[part 6 of 11: package /CANAnalyzer/CommunicationClusters]
AUTOSAR XML (schema 00051)
package /CANAnalyzer/CommunicationClusters  (continued)
  can cluster CAN_FD_IPB_41  (continued)
    can physical channel Channel  (continued)
      frame StatusCPDData3FBD_Trunk: id 0x161, frame-length=64, can-addressing-mode=STANDARD, can-frame-rx-behavior=CAN-FD, can-frame-tx-behavior=CAN-FD
        pdu StatusCPDData3FBD_Trunk: length=64, unused-bit-pattern=0
          signal StatusCPDData3FBD_Trunk_MsgCounter: start 0, 8 bit, little-endian, data-type-policy=OVERRIDE, base-type=uint8, compu {phys=raw}, range phys 0..252
          signal StatusCPDData3FBD_Trunk_LinkID: start 8, 8 bit, little-endian, data-type-policy=OVERRIDE, base-type=uint8, compu {phys=raw}, range phys 0..252
          signal StatusCPDData3FBD_Trunk_AGCValue: start 16, 8 bit, little-endian, data-type-policy=OVERRIDE, base-type=uint8, compu {phys=raw}, range phys 0..252
          signal StatusCPDData3FBD_Trunk_Channel: start 24, 8 bit, little-endian, data-type-policy=OVERRIDE, base-type=uint8, compu {phys=raw}, range phys 0..252
          signal StatusCPDData3FBD_Trunk_CIRData00: start 32, 8 bit, little-endian, data-type-policy=OVERRIDE, base-type=uint8, compu {phys=raw}, range phys 0..255
          signal StatusCPDData3FBD_Trunk_CIRData01: start 40, 8 bit, little-endian, data-type-policy=OVERRIDE, base-type=uint8, compu {phys=raw}, range phys 0..255
          signal StatusCPDData3FBD_Trunk_CIRData02: start 48, 8 bit, little-endian, data-type-policy=OVERRIDE, base-type=uint8, compu {phys=raw}, range phys 0..255
          signal StatusCPDData3FBD_Trunk_CIRData03: start 56, 8 bit, little-endian, data-type-policy=OVERRIDE, base-type=uint8, compu {phys=raw}, range phys 0..255
          signal StatusCPDData3FBD_Trunk_CIRData04: start 64, 8 bit, little-endian, data-type-policy=OVERRIDE, base-type=uint8, compu {phys=raw}, range phys 0..255
          signal StatusCPDData3FBD_Trunk_CIRData05: start 72, 8 bit, little-endian, data-type-policy=OVERRIDE, base-type=uint8, compu {phys=raw}, range phys 0..255
          signal StatusCPDData3FBD_Trunk_CIRData06: start 80, 8 bit, little-endian, data-type-policy=OVERRIDE, base-type=uint8, compu {phys=raw}, range phys 0..255
          signal StatusCPDData3FBD_Trunk_CIRData07: start 88, 8 bit, little-endian, data-type-policy=OVERRIDE, base-type=uint8, compu {phys=raw}, range phys 0..255
          signal StatusCPDData3FBD_Trunk_CIRData08: start 96, 8 bit, little-endian, data-type-policy=OVERRIDE, base-type=uint8, compu {phys=raw}, range phys 0..255
          signal StatusCPDData3FBD_Trunk_CIRData09: start 104, 8 bit, little-endian, data-type-policy=OVERRIDE, base-type=uint8, compu {phys=raw}, range phys 0..255
          signal StatusCPDData3FBD_Trunk_CIRData10: start 112, 8 bit, little-endian, data-type-policy=OVERRIDE, base-type=uint8, compu {phys=raw}, range phys 0..255
          signal StatusCPDData3FBD_Trunk_CIRData11: start 120, 8 bit, little-endian, data-type-policy=OVERRIDE, base-type=uint8, compu {phys=raw}, range phys 0..255
          signal StatusCPDData3FBD_Trunk_CIRData12: start 128, 8 bit, little-endian, data-type-policy=OVERRIDE, base-type=uint8, compu {phys=raw}, range phys 0..255
          signal StatusCPDData3FBD_Trunk_CIRData13: start 136, 8 bit, little-endian, data-type-policy=OVERRIDE, base-type=uint8, compu {phys=raw}, range phys 0..255
          signal StatusCPDData3FBD_Trunk_CIRData14: start 144, 8 bit, little-endian, data-type-policy=OVERRIDE, base-type=uint8, compu {phys=raw}, range phys 0..255
          signal StatusCPDData3FBD_Trunk_CIRData15: start 152, 8 bit, little-endian, data-type-policy=OVERRIDE, base-type=uint8, compu {phys=raw}, range phys 0..255
          signal StatusCPDData3FBD_Trunk_CIRData16: start 160, 8 bit, little-endian, data-type-policy=OVERRIDE, base-type=uint8, compu {phys=raw}, range phys 0..255
          signal StatusCPDData3FBD_Trunk_CIRData17: start 168, 8 bit, little-endian, data-type-policy=OVERRIDE, base-type=uint8, compu {phys=raw}, range phys 0..255
          signal StatusCPDData3FBD_Trunk_CIRData18: start 176, 8 bit, little-endian, data-type-policy=OVERRIDE, base-type=uint8, compu {phys=raw}, range phys 0..255
          signal StatusCPDData3FBD_Trunk_CIRData19: start 184, 8 bit, little-endian, data-type-policy=OVERRIDE, base-type=uint8, compu {phys=raw}, range phys 0..255
          signal StatusCPDData3FBD_Trunk_CIRData20: start 192, 8 bit, little-endian, data-type-policy=OVERRIDE, base-type=uint8, compu {phys=raw}, range phys 0..255
          signal StatusCPDData3FBD_Trunk_CIRData21: start 200, 8 bit, little-endian, data-type-policy=OVERRIDE, base-type=uint8, compu {phys=raw}, range phys 0..255
          signal StatusCPDData3FBD_Trunk_CIRData22: start 208, 8 bit, little-endian, data-type-policy=OVERRIDE, base-type=uint8, compu {phys=raw}, range phys 0..255
          signal StatusCPDData3FBD_Trunk_CIRData23: start 216, 8 bit, little-endian, data-type-policy=OVERRIDE, base-type=uint8, compu {phys=raw}, range phys 0..255
          signal StatusCPDData3FBD_Trunk_CIRData24: start 224, 8 bit, little-endian, data-type-policy=OVERRIDE, base-type=uint8, compu {phys=raw}, range phys 0..255
          signal StatusCPDData3FBD_Trunk_CIRData25: start 232, 8 bit, little-endian, data-type-policy=OVERRIDE, base-type=uint8, compu {phys=raw}, range phys 0..255
          signal StatusCPDData3FBD_Trunk_CIRData26: start 240, 8 bit, little-endian, data-type-policy=OVERRIDE, base-type=uint8, compu {phys=raw}, range phys 0..255
          signal StatusCPDData3FBD_Trunk_CIRData27: start 248, 8 bit, little-endian, data-type-policy=OVERRIDE, base-type=uint8, compu {phys=raw}, range phys 0..255
          signal StatusCPDData3FBD_Trunk_CIRData28: start 256, 8 bit, little-endian, data-type-policy=OVERRIDE, base-type=uint8, compu {phys=raw}, range phys 0..255
          signal StatusCPDData3FBD_Trunk_CIRData29: start 264, 8 bit, little-endian, data-type-policy=OVERRIDE, base-type=uint8, compu {phys=raw}, range phys 0..255
          signal StatusCPDData3FBD_Trunk_CIRData30: start 272, 8 bit, little-endian, data-type-policy=OVERRIDE, base-type=uint8, compu {phys=raw}, range phys 0..255
          signal StatusCPDData3FBD_Trunk_CIRData31: start 280, 8 bit, little-endian, data-type-policy=OVERRIDE, base-type=uint8, compu {phys=raw}, range phys 0..255
          signal StatusCPDData3FBD_Trunk_CIRData32: start 288, 8 bit, little-endian, data-type-policy=OVERRIDE, base-type=uint8, compu {phys=raw}, range phys 0..255
          signal StatusCPDData3FBD_Trunk_CIRData33: start 296, 8 bit, little-endian, data-type-policy=OVERRIDE, base-type=uint8, compu {phys=raw}, range phys 0..255
          signal StatusCPDData3FBD_Trunk_CIRData34: start 304, 8 bit, little-endian, data-type-policy=OVERRIDE, base-type=uint8, compu {phys=raw}, range phys 0..255
          signal StatusCPDData3FBD_Trunk_CIRData35: start 312, 8 bit, little-endian, data-type-policy=OVERRIDE, base-type=uint8, compu {phys=raw}, range phys 0..255
          signal StatusCPDData3FBD_Trunk_CIRData36: start 320, 8 bit, little-endian, data-type-policy=OVERRIDE, base-type=uint8, compu {phys=raw}, range phys 0..255
          signal StatusCPDData3FBD_Trunk_CIRData37: start 328, 8 bit, little-endian, data-type-policy=OVERRIDE, base-type=uint8, compu {phys=raw}, range phys 0..255
          signal StatusCPDData3FBD_Trunk_CIRData38: start 336, 8 bit, little-endian, data-type-policy=OVERRIDE, base-type=uint8, compu {phys=raw}, range phys 0..255
          signal StatusCPDData3FBD_Trunk_CIRData39: start 344, 8 bit, little-endian, data-type-policy=OVERRIDE, base-type=uint8, compu {phys=raw}, range phys 0..255
          signal StatusCPDData3FBD_Trunk_CIRData40: start 352, 8 bit, little-endian, data-type-policy=OVERRIDE, base-type=uint8, compu {phys=raw}, range phys 0..255
          signal StatusCPDData3FBD_Trunk_CIRData41: start 360, 8 bit, little-endian, data-type-policy=OVERRIDE, base-type=uint8, compu {phys=raw}, range phys 0..255
          signal StatusCPDData3FBD_Trunk_CIRData42: start 368, 8 bit, little-endian, data-type-policy=OVERRIDE, base-type=uint8, compu {phys=raw}, range phys 0..255
          signal StatusCPDData3FBD_Trunk_CIRData43: start 376, 8 bit, little-endian, data-type-policy=OVERRIDE, base-type=uint8, compu {phys=raw}, range phys 0..255
          signal StatusCPDData3FBD_Trunk_CIRData44: start 384, 8 bit, little-endian, data-type-policy=OVERRIDE, base-type=uint8, compu {phys=raw}, range phys 0..255
          signal StatusCPDData3FBD_Trunk_CIRData45: start 392, 8 bit, little-endian, data-type-policy=OVERRIDE, base-type=uint8, compu {phys=raw}, range phys 0..255
          signal StatusCPDData3FBD_Trunk_CIRData46: start 400, 8 bit, little-endian, data-type-policy=OVERRIDE, base-type=uint8, compu {phys=raw}, range phys 0..255
          signal StatusCPDData3FBD_Trunk_CIRData47: start 408, 8 bit, little-endian, data-type-policy=OVERRIDE, base-type=uint8, compu {phys=raw}, range phys 0..255
          signal StatusCPDData3FBD_Trunk_CIRData48: start 416, 8 bit, little-endian, data-type-policy=OVERRIDE, base-type=uint8, compu {phys=raw}, range phys 0..255
          signal StatusCPDData3FBD_Trunk_CIRData49: start 424, 8 bit, little-endian, data-type-policy=OVERRIDE, base-type=uint8, compu {phys=raw}, range phys 0..255
          signal StatusCPDData3FBD_Trunk_CIRData50: start 432, 8 bit, little-endian, data-type-policy=OVERRIDE, base-type=uint8, compu {phys=raw}, range phys 0..255
          signal StatusCPDData3FBD_Trunk_CIRData51: start 440, 8 bit, little-endian, data-type-policy=OVERRIDE, base-type=uint8, compu {phys=raw}, range phys 0..255
          signal StatusCPDData3FBD_Trunk_CIRData52: start 448, 8 bit, little-endian, data-type-policy=OVERRIDE, base-type=uint8, compu {phys=raw}, range phys 0..255
          signal StatusCPDData3FBD_Trunk_CIRData53: start 456, 8 bit, little-endian, data-type-policy=OVERRIDE, base-type=uint8, compu {phys=raw}, range phys 0..255
          signal StatusCPDData3FBD_Trunk_CIRData54: start 464, 8 bit, little-endian, data-type-policy=OVERRIDE, base-type=uint8, compu {phys=raw}, range phys 0..255
          signal StatusCPDData3FBD_Trunk_CIRData55: start 472, 8 bit, little-endian, data-type-policy=OVERRIDE, base-type=uint8, compu {phys=raw}, range phys 0..255
          signal StatusCPDData3FBD_Trunk_CIRData56: start 480, 8 bit, little-endian, data-type-policy=OVERRIDE, base-type=uint8, compu {phys=raw}, range phys 0..255
          signal StatusCPDData3FBD_Trunk_CIRData57: start 488, 8 bit, little-endian, data-type-policy=OVERRIDE, base-type=uint8, compu {phys=raw}, range phys 0..255
          signal StatusCPDData3FBD_Trunk_CIRData58: start 496, 8 bit, little-endian, data-type-policy=OVERRIDE, base-type=uint8, compu {phys=raw}, range phys 0..255
          signal StatusCPDData3FBD_Trunk_CIRData59: start 504, 8 bit, little-endian, data-type-policy=OVERRIDE, base-type=uint8, compu {phys=raw}, range phys 0..255
      frame StatusCPDData3FBD_VL: id 0x162, frame-length=64, can-addressing-mode=STANDARD, can-frame-rx-behavior=CAN-FD, can-frame-tx-behavior=CAN-FD
        pdu StatusCPDData3FBD_VL: length=64, unused-bit-pattern=0
          signal StatusCPDData3FBD_VL_MsgCounter: start 0, 8 bit, little-endian, data-type-policy=OVERRIDE, base-type=uint8, compu {phys=raw}, range phys 0..252
          signal StatusCPDData3FBD_VL_LinkID: start 8, 8 bit, little-endian, data-type-policy=OVERRIDE, base-type=uint8, compu {phys=raw}, range phys 0..252
          signal StatusCPDData3FBD_VL_AGCValue: start 16, 8 bit, little-endian, data-type-policy=OVERRIDE, base-type=uint8, compu {phys=raw}, range phys 0..252
          signal StatusCPDData3FBD_VL_Channel: start 24, 8 bit, little-endian, data-type-policy=OVERRIDE, base-type=uint8, compu {phys=raw}, range phys 0..252
          signal StatusCPDData3FBD_VL_CIRData00: start 32, 8 bit, little-endian, data-type-policy=OVERRIDE, base-type=uint8, compu {phys=raw}, range phys 0..255
          signal StatusCPDData3FBD_VL_CIRData01: start 40, 8 bit, little-endian, data-type-policy=OVERRIDE, base-type=uint8, compu {phys=raw}, range phys 0..255
          signal StatusCPDData3FBD_VL_CIRData02: start 48, 8 bit, little-endian, data-type-policy=OVERRIDE, base-type=uint8, compu {phys=raw}, range phys 0..255
          signal StatusCPDData3FBD_VL_CIRData03: start 56, 8 bit, little-endian, data-type-policy=OVERRIDE, base-type=uint8, compu {phys=raw}, range phys 0..255
          signal StatusCPDData3FBD_VL_CIRData04: start 64, 8 bit, little-endian, data-type-policy=OVERRIDE, base-type=uint8, compu {phys=raw}, range phys 0..255
          signal StatusCPDData3FBD_VL_CIRData05: start 72, 8 bit, little-endian, data-type-policy=OVERRIDE, base-type=uint8, compu {phys=raw}, range phys 0..255
          signal StatusCPDData3FBD_VL_CIRData06: start 80, 8 bit, little-endian, data-type-policy=OVERRIDE, base-type=uint8, compu {phys=raw}, range phys 0..255
          signal StatusCPDData3FBD_VL_CIRData07: start 88, 8 bit, little-endian, data-type-policy=OVERRIDE, base-type=uint8, compu {phys=raw}, range phys 0..255
          signal StatusCPDData3FBD_VL_CIRData08: start 96, 8 bit, little-endian, data-type-policy=OVERRIDE, base-type=uint8, compu {phys=raw}, range phys 0..255
          signal StatusCPDData3FBD_VL_CIRData09: start 104, 8 bit, little-endian, data-type-policy=OVERRIDE, base-type=uint8, compu {phys=raw}, range phys 0..255
          signal StatusCPDData3FBD_VL_CIRData10: start 112, 8 bit, little-endian, data-type-policy=OVERRIDE, base-type=uint8, compu {phys=raw}, range phys 0..255
          signal StatusCPDData3FBD_VL_CIRData11: start 120, 8 bit, little-endian, data-type-policy=OVERRIDE, base-type=uint8, compu {phys=raw}, range phys 0..255
          signal StatusCPDData3FBD_VL_CIRData12: start 128, 8 bit, little-endian, data-type-policy=OVERRIDE, base-type=uint8, compu {phys=raw}, range phys 0..255
          signal StatusCPDData3FBD_VL_CIRData13: start 136, 8 bit, little-endian, data-type-policy=OVERRIDE, base-type=uint8, compu {phys=raw}, range phys 0..255
          signal StatusCPDData3FBD_VL_CIRData14: start 144, 8 bit, little-endian, data-type-policy=OVERRIDE, base-type=uint8, compu {phys=raw}, range phys 0..255
          signal StatusCPDData3FBD_VL_CIRData15: start 152, 8 bit, little-endian, data-type-policy=OVERRIDE, base-type=uint8, compu {phys=raw}, range phys 0..255
          signal StatusCPDData3FBD_VL_CIRData16: start 160, 8 bit, little-endian, data-type-policy=OVERRIDE, base-type=uint8, compu {phys=raw}, range phys 0..255
          signal StatusCPDData3FBD_VL_CIRData17: start 168, 8 bit, little-endian, data-type-policy=OVERRIDE, base-type=uint8, compu {phys=raw}, range phys 0..255
          signal StatusCPDData3FBD_VL_CIRData18: start 176, 8 bit, little-endian, data-type-policy=OVERRIDE, base-type=uint8, compu {phys=raw}, range phys 0..255
          signal StatusCPDData3FBD_VL_CIRData19: start 184, 8 bit, little-endian, data-type-policy=OVERRIDE, base-type=uint8, compu {phys=raw}, range phys 0..255
          signal StatusCPDData3FBD_VL_CIRData20: start 192, 8 bit, little-endian, data-type-policy=OVERRIDE, base-type=uint8, compu {phys=raw}, range phys 0..255
          signal StatusCPDData3FBD_VL_CIRData21: start 200, 8 bit, little-endian, data-type-policy=OVERRIDE, base-type=uint8, compu {phys=raw}, range phys 0..255
          signal StatusCPDData3FBD_VL_CIRData22: start 208, 8 bit, little-endian, data-type-policy=OVERRIDE, base-type=uint8, compu {phys=raw}, range phys 0..255
          signal StatusCPDData3FBD_VL_CIRData23: start 216, 8 bit, little-endian, data-type-policy=OVERRIDE, base-type=uint8, compu {phys=raw}, range phys 0..255
          signal StatusCPDData3FBD_VL_CIRData24: start 224, 8 bit, little-endian, data-type-policy=OVERRIDE, base-type=uint8, compu {phys=raw}, range phys 0..255
          signal StatusCPDData3FBD_VL_CIRData25: start 232, 8 bit, little-endian, data-type-policy=OVERRIDE, base-type=uint8, compu {phys=raw}, range phys 0..255
          signal StatusCPDData3FBD_VL_CIRData26: start 240, 8 bit, little-endian, data-type-policy=OVERRIDE, base-type=uint8, compu {phys=raw}, range phys 0..255
          signal StatusCPDData3FBD_VL_CIRData27: start 248, 8 bit, little-endian, data-type-policy=OVERRIDE, base-type=uint8, compu {phys=raw}, range phys 0..255
          signal StatusCPDData3FBD_VL_CIRData28: start 256, 8 bit, little-endian, data-type-policy=OVERRIDE, base-type=uint8, compu {phys=raw}, range phys 0..255
          signal StatusCPDData3FBD_VL_CIRData29: start 264, 8 bit, little-endian, data-type-policy=OVERRIDE, base-type=uint8, compu {phys=raw}, range phys 0..255
          signal StatusCPDData3FBD_VL_CIRData30: start 272, 8 bit, little-endian, data-type-policy=OVERRIDE, base-type=uint8, compu {phys=raw}, range phys 0..255
          signal StatusCPDData3FBD_VL_CIRData31: start 280, 8 bit, little-endian, data-type-policy=OVERRIDE, base-type=uint8, compu {phys=raw}, range phys 0..255
          signal StatusCPDData3FBD_VL_CIRData32: start 288, 8 bit, little-endian, data-type-policy=OVERRIDE, base-type=uint8, compu {phys=raw}, range phys 0..255
          signal StatusCPDData3FBD_VL_CIRData33: start 296, 8 bit, little-endian, data-type-policy=OVERRIDE, base-type=uint8, compu {phys=raw}, range phys 0..255
          signal StatusCPDData3FBD_VL_CIRData34: start 304, 8 bit, little-endian, data-type-policy=OVERRIDE, base-type=uint8, compu {phys=raw}, range phys 0..255
          signal StatusCPDData3FBD_VL_CIRData35: start 312, 8 bit, little-endian, data-type-policy=OVERRIDE, base-type=uint8, compu {phys=raw}, range phys 0..255
          signal StatusCPDData3FBD_VL_CIRData36: start 320, 8 bit, little-endian, data-type-policy=OVERRIDE, base-type=uint8, compu {phys=raw}, range phys 0..255
          signal StatusCPDData3FBD_VL_CIRData37: start 328, 8 bit, little-endian, data-type-policy=OVERRIDE, base-type=uint8, compu {phys=raw}, range phys 0..255
          signal StatusCPDData3FBD_VL_CIRData38: start 336, 8 bit, little-endian, data-type-policy=OVERRIDE, base-type=uint8, compu {phys=raw}, range phys 0..255
          signal StatusCPDData3FBD_VL_CIRData39: start 344, 8 bit, little-endian, data-type-policy=OVERRIDE, base-type=uint8, compu {phys=raw}, range phys 0..255
          signal StatusCPDData3FBD_VL_CIRData40: start 352, 8 bit, little-endian, data-type-policy=OVERRIDE, base-type=uint8, compu {phys=raw}, range phys 0..255
          signal StatusCPDData3FBD_VL_CIRData41: start 360, 8 bit, little-endian, data-type-policy=OVERRIDE, base-type=uint8, compu {phys=raw}, range phys 0..255
          signal StatusCPDData3FBD_VL_CIRData42: start 368, 8 bit, little-endian, data-type-policy=OVERRIDE, base-type=uint8, compu {phys=raw}, range phys 0..255
          signal StatusCPDData3FBD_VL_CIRData43: start 376, 8 bit, little-endian, data-type-policy=OVERRIDE, base-type=uint8, compu {phys=raw}, range phys 0..255
          signal StatusCPDData3FBD_VL_CIRData44: start 384, 8 bit, little-endian, data-type-policy=OVERRIDE, base-type=uint8, compu {phys=raw}, range phys 0..255
          signal StatusCPDData3FBD_VL_CIRData45: start 392, 8 bit, little-endian, data-type-policy=OVERRIDE, base-type=uint8, compu {phys=raw}, range phys 0..255
          signal StatusCPDData3FBD_VL_CIRData46: start 400, 8 bit, little-endian, data-type-policy=OVERRIDE, base-type=uint8, compu {phys=raw}, range phys 0..255
          signal StatusCPDData3FBD_VL_CIRData47: start 408, 8 bit, little-endian, data-type-policy=OVERRIDE, base-type=uint8, compu {phys=raw}, range phys 0..255
          signal StatusCPDData3FBD_VL_CIRData48: start 416, 8 bit, little-endian, data-type-policy=OVERRIDE, base-type=uint8, compu {phys=raw}, range phys 0..255
          signal StatusCPDData3FBD_VL_CIRData49: start 424, 8 bit, little-endian, data-type-policy=OVERRIDE, base-type=uint8, compu {phys=raw}, range phys 0..255
          signal StatusCPDData3FBD_VL_CIRData50: start 432, 8 bit, little-endian, data-type-policy=OVERRIDE, base-type=uint8, compu {phys=raw}, range phys 0..255
          signal StatusCPDData3FBD_VL_CIRData51: start 440, 8 bit, little-endian, data-type-policy=OVERRIDE, base-type=uint8, compu {phys=raw}, range phys 0..255
          signal StatusCPDData3FBD_VL_CIRData52: start 448, 8 bit, little-endian, data-type-policy=OVERRIDE, base-type=uint8, compu {phys=raw}, range phys 0..255
          signal StatusCPDData3FBD_VL_CIRData53: start 456, 8 bit, little-endian, data-type-policy=OVERRIDE, base-type=uint8, compu {phys=raw}, range phys 0..255
          signal StatusCPDData3FBD_VL_CIRData54: start 464, 8 bit, little-endian, data-type-policy=OVERRIDE, base-type=uint8, compu {phys=raw}, range phys 0..255
          signal StatusCPDData3FBD_VL_CIRData55: start 472, 8 bit, little-endian, data-type-policy=OVERRIDE, base-type=uint8, compu {phys=raw}, range phys 0..255
          signal StatusCPDData3FBD_VL_CIRData56: start 480, 8 bit, little-endian, data-type-policy=OVERRIDE, base-type=uint8, compu {phys=raw}, range phys 0..255
          signal StatusCPDData3FBD_VL_CIRData57: start 488, 8 bit, little-endian, data-type-policy=OVERRIDE, base-type=uint8, compu {phys=raw}, range phys 0..255
          signal StatusCPDData3FBD_VL_CIRData58: start 496, 8 bit, little-endian, data-type-policy=OVERRIDE, base-type=uint8, compu {phys=raw}, range phys 0..255
          signal StatusCPDData3FBD_VL_CIRData59: start 504, 8 bit, little-endian, data-type-policy=OVERRIDE, base-type=uint8, compu {phys=raw}, range phys 0..255
      frame StatusCPDData3FBD_VM: id 0x15E, frame-length=64, can-addressing-mode=STANDARD, can-frame-rx-behavior=CAN-FD, can-frame-tx-behavior=CAN-FD
        pdu StatusCPDData3FBD_VM: length=64, unused-bit-pattern=0
          signal StatusCPDData3FBD_VM_MsgCounter: start 0, 8 bit, little-endian, data-type-policy=OVERRIDE, base-type=uint8, compu {phys=raw}, range phys 0..252
          signal StatusCPDData3FBD_VM_LinkID: start 8, 8 bit, little-endian, data-type-policy=OVERRIDE, base-type=uint8, compu {phys=raw}, range phys 0..252
          signal StatusCPDData3FBD_VM_AGCValue: start 16, 8 bit, little-endian, data-type-policy=OVERRIDE, base-type=uint8, compu {phys=raw}, range phys 0..252
          signal StatusCPDData3FBD_VM_Channel: start 24, 8 bit, little-endian, data-type-policy=OVERRIDE, base-type=uint8, compu {phys=raw}, range phys 0..252
          signal StatusCPDData3FBD_VM_CIRData00: start 32, 8 bit, little-endian, data-type-policy=OVERRIDE, base-type=uint8, compu {phys=raw}, range phys 0..255
          signal StatusCPDData3FBD_VM_CIRData01: start 40, 8 bit, little-endian, data-type-policy=OVERRIDE, base-type=uint8, compu {phys=raw}, range phys 0..255
          signal StatusCPDData3FBD_VM_CIRData02: start 48, 8 bit, little-endian, data-type-policy=OVERRIDE, base-type=uint8, compu {phys=raw}, range phys 0..255
          signal StatusCPDData3FBD_VM_CIRData03: start 56, 8 bit, little-endian, data-type-policy=OVERRIDE, base-type=uint8, compu {phys=raw}, range phys 0..255
          signal StatusCPDData3FBD_VM_CIRData04: start 64, 8 bit, little-endian, data-type-policy=OVERRIDE, base-type=uint8, compu {phys=raw}, range phys 0..255
          signal StatusCPDData3FBD_VM_CIRData05: start 72, 8 bit, little-endian, data-type-policy=OVERRIDE, base-type=uint8, compu {phys=raw}, range phys 0..255
          signal StatusCPDData3FBD_VM_CIRData06: start 80, 8 bit, little-endian, data-type-policy=OVERRIDE, base-type=uint8, compu {phys=raw}, range phys 0..255
          signal StatusCPDData3FBD_VM_CIRData07: start 88, 8 bit, little-endian, data-type-policy=OVERRIDE, base-type=uint8, compu {phys=raw}, range phys 0..255
          signal StatusCPDData3FBD_VM_CIRData08: start 96, 8 bit, little-endian, data-type-policy=OVERRIDE, base-type=uint8, compu {phys=raw}, range phys 0..255
          signal StatusCPDData3FBD_VM_CIRData09: start 104, 8 bit, little-endian, data-type-policy=OVERRIDE, base-type=uint8, compu {phys=raw}, range phys 0..255
          signal StatusCPDData3FBD_VM_CIRData10: start 112, 8 bit, little-endian, data-type-policy=OVERRIDE, base-type=uint8, compu {phys=raw}, range phys 0..255
          signal StatusCPDData3FBD_VM_CIRData11: start 120, 8 bit, little-endian, data-type-policy=OVERRIDE, base-type=uint8, compu {phys=raw}, range phys 0..255
          signal StatusCPDData3FBD_VM_CIRData12: start 128, 8 bit, little-endian, data-type-policy=OVERRIDE, base-type=uint8, compu {phys=raw}, range phys 0..255
          signal StatusCPDData3FBD_VM_CIRData13: start 136, 8 bit, little-endian, data-type-policy=OVERRIDE, base-type=uint8, compu {phys=raw}, range phys 0..255
          signal StatusCPDData3FBD_VM_CIRData14: start 144, 8 bit, little-endian, data-type-policy=OVERRIDE, base-type=uint8, compu {phys=raw}, range phys 0..255
          signal StatusCPDData3FBD_VM_CIRData15: start 152, 8 bit, little-endian, data-type-policy=OVERRIDE, base-type=uint8, compu {phys=raw}, range phys 0..255
          signal StatusCPDData3FBD_VM_CIRData16: start 160, 8 bit, little-endian, data-type-policy=OVERRIDE, base-type=uint8, compu {phys=raw}, range phys 0..255
          signal StatusCPDData3FBD_VM_CIRData17: start 168, 8 bit, little-endian, data-type-policy=OVERRIDE, base-type=uint8, compu {phys=raw}, range phys 0..255
          signal StatusCPDData3FBD_VM_CIRData18: start 176, 8 bit, little-endian, data-type-policy=OVERRIDE, base-type=uint8, compu {phys=raw}, range phys 0..255
          signal StatusCPDData3FBD_VM_CIRData19: start 184, 8 bit, little-endian, data-type-policy=OVERRIDE, base-type=uint8, compu {phys=raw}, range phys 0..255
          signal StatusCPDData3FBD_VM_CIRData20: start 192, 8 bit, little-endian, data-type-policy=OVERRIDE, base-type=uint8, compu {phys=raw}, range phys 0..255
          signal StatusCPDData3FBD_VM_CIRData21: start 200, 8 bit, little-endian, data-type-policy=OVERRIDE, base-type=uint8, compu {phys=raw}, range phys 0..255
          signal StatusCPDData3FBD_VM_CIRData22: start 208, 8 bit, little-endian, data-type-policy=OVERRIDE, base-type=uint8, compu {phys=raw}, range phys 0..255
          signal StatusCPDData3FBD_VM_CIRData23: start 216, 8 bit, little-endian, data-type-policy=OVERRIDE, base-type=uint8, compu {phys=raw}, range phys 0..255
          signal StatusCPDData3FBD_VM_CIRData24: start 224, 8 bit, little-endian, data-type-policy=OVERRIDE, base-type=uint8, compu {phys=raw}, range phys 0..255
          signal StatusCPDData3FBD_VM_CIRData25: start 232, 8 bit, little-endian, data-type-policy=OVERRIDE, base-type=uint8, compu {phys=raw}, range phys 0..255
          signal StatusCPDData3FBD_VM_CIRData26: start 240, 8 bit, little-endian, data-type-policy=OVERRIDE, base-type=uint8, compu {phys=raw}, range phys 0..255
          signal StatusCPDData3FBD_VM_CIRData27: start 248, 8 bit, little-endian, data-type-policy=OVERRIDE, base-type=uint8, compu {phys=raw}, range phys 0..255
          signal StatusCPDData3FBD_VM_CIRData28: start 256, 8 bit, little-endian, data-type-policy=OVERRIDE, base-type=uint8, compu {phys=raw}, range phys 0..255
          signal StatusCPDData3FBD_VM_CIRData29: start 264, 8 bit, little-endian, data-type-policy=OVERRIDE, base-type=uint8, compu {phys=raw}, range phys 0..255
          signal StatusCPDData3FBD_VM_CIRData30: start 272, 8 bit, little-endian, data-type-policy=OVERRIDE, base-type=uint8, compu {phys=raw}, range phys 0..255
          signal StatusCPDData3FBD_VM_CIRData31: start 280, 8 bit, little-endian, data-type-policy=OVERRIDE, base-type=uint8, compu {phys=raw}, range phys 0..255
          signal StatusCPDData3FBD_VM_CIRData32: start 288, 8 bit, little-endian, data-type-policy=OVERRIDE, base-type=uint8, compu {phys=raw}, range phys 0..255
          signal StatusCPDData3FBD_VM_CIRData33: start 296, 8 bit, little-endian, data-type-policy=OVERRIDE, base-type=uint8, compu {phys=raw}, range phys 0..255
          signal StatusCPDData3FBD_VM_CIRData34: start 304, 8 bit, little-endian, data-type-policy=OVERRIDE, base-type=uint8, compu {phys=raw}, range phys 0..255
          signal StatusCPDData3FBD_VM_CIRData35: start 312, 8 bit, little-endian, data-type-policy=OVERRIDE, base-type=uint8, compu {phys=raw}, range phys 0..255
          signal StatusCPDData3FBD_VM_CIRData36: start 320, 8 bit, little-endian, data-type-policy=OVERRIDE, base-type=uint8, compu {phys=raw}, range phys 0..255
          signal StatusCPDData3FBD_VM_CIRData37: start 328, 8 bit, little-endian, data-type-policy=OVERRIDE, base-type=uint8, compu {phys=raw}, range phys 0..255
          signal StatusCPDData3FBD_VM_CIRData38: start 336, 8 bit, little-endian, data-type-policy=OVERRIDE, base-type=uint8, compu {phys=raw}, range phys 0..255
          signal StatusCPDData3FBD_VM_CIRData39: start 344, 8 bit, little-endian, data-type-policy=OVERRIDE, base-type=uint8, compu {phys=raw}, range phys 0..255
          signal StatusCPDData3FBD_VM_CIRData40: start 352, 8 bit, little-endian, data-type-policy=OVERRIDE, base-type=uint8, compu {phys=raw}, range phys 0..255
          signal StatusCPDData3FBD_VM_CIRData41: start 360, 8 bit, little-endian, data-type-policy=OVERRIDE, base-type=uint8, compu {phys=raw}, range phys 0..255
          signal StatusCPDData3FBD_VM_CIRData42: start 368, 8 bit, little-endian, data-type-policy=OVERRIDE, base-type=uint8, compu {phys=raw}, range phys 0..255
          signal StatusCPDData3FBD_VM_CIRData43: start 376, 8 bit, little-endian, data-type-policy=OVERRIDE, base-type=uint8, compu {phys=raw}, range phys 0..255
          signal StatusCPDData3FBD_VM_CIRData44: start 384, 8 bit, little-endian, data-type-policy=OVERRIDE, base-type=uint8, compu {phys=raw}, range phys 0..255
          signal StatusCPDData3FBD_VM_CIRData45: start 392, 8 bit, little-endian, data-type-policy=OVERRIDE, base-type=uint8, compu {phys=raw}, range phys 0..255
          signal StatusCPDData3FBD_VM_CIRData46: start 400, 8 bit, little-endian, data-type-policy=OVERRIDE, base-type=uint8, compu {phys=raw}, range phys 0..255
          signal StatusCPDData3FBD_VM_CIRData47: start 408, 8 bit, little-endian, data-type-policy=OVERRIDE, base-type=uint8, compu {phys=raw}, range phys 0..255
          signal StatusCPDData3FBD_VM_CIRData48: start 416, 8 bit, little-endian, data-type-policy=OVERRIDE, base-type=uint8, compu {phys=raw}, range phys 0..255
          signal StatusCPDData3FBD_VM_CIRData49: start 424, 8 bit, little-endian, data-type-policy=OVERRIDE, base-type=uint8, compu {phys=raw}, range phys 0..255
          signal StatusCPDData3FBD_VM_CIRData50: start 432, 8 bit, little-endian, data-type-policy=OVERRIDE, base-type=uint8, compu {phys=raw}, range phys 0..255
          signal StatusCPDData3FBD_VM_CIRData51: start 440, 8 bit, little-endian, data-type-policy=OVERRIDE, base-type=uint8, compu {phys=raw}, range phys 0..255
          signal StatusCPDData3FBD_VM_CIRData52: start 448, 8 bit, little-endian, data-type-policy=OVERRIDE, base-type=uint8, compu {phys=raw}, range phys 0..255
          signal StatusCPDData3FBD_VM_CIRData53: start 456, 8 bit, little-endian, data-type-policy=OVERRIDE, base-type=uint8, compu {phys=raw}, range phys 0..255
          signal StatusCPDData3FBD_VM_CIRData54: start 464, 8 bit, little-endian, data-type-policy=OVERRIDE, base-type=uint8, compu {phys=raw}, range phys 0..255
          signal StatusCPDData3FBD_VM_CIRData55: start 472, 8 bit, little-endian, data-type-policy=OVERRIDE, base-type=uint8, compu {phys=raw}, range phys 0..255
          signal StatusCPDData3FBD_VM_CIRData56: start 480, 8 bit, little-endian, data-type-policy=OVERRIDE, base-type=uint8, compu {phys=raw}, range phys 0..255
          signal StatusCPDData3FBD_VM_CIRData57: start 488, 8 bit, little-endian, data-type-policy=OVERRIDE, base-type=uint8, compu {phys=raw}, range phys 0..255
          signal StatusCPDData3FBD_VM_CIRData58: start 496, 8 bit, little-endian, data-type-policy=OVERRIDE, base-type=uint8, compu {phys=raw}, range phys 0..255
          signal StatusCPDData3FBD_VM_CIRData59: start 504, 8 bit, little-endian, data-type-policy=OVERRIDE, base-type=uint8, compu {phys=raw}, range phys 0..255
      frame StatusCPDData3FBD_VR: id 0x163, frame-length=64, can-addressing-mode=STANDARD, can-frame-rx-behavior=CAN-FD, can-frame-tx-behavior=CAN-FD
        pdu StatusCPDData3FBD_VR: length=64, unused-bit-pattern=0
          signal StatusCPDData3FBD_VR_MsgCounter: start 0, 8 bit, little-endian, data-type-policy=OVERRIDE, base-type=uint8, compu {phys=raw}, range phys 0..252
          signal StatusCPDData3FBD_VR_LinkID: start 8, 8 bit, little-endian, data-type-policy=OVERRIDE, base-type=uint8, compu {phys=raw}, range phys 0..252
          signal StatusCPDData3FBD_VR_AGCValue: start 16, 8 bit, little-endian, data-type-policy=OVERRIDE, base-type=uint8, compu {phys=raw}, range phys 0..252
          signal StatusCPDData3FBD_VR_Channel: start 24, 8 bit, little-endian, data-type-policy=OVERRIDE, base-type=uint8, compu {phys=raw}, range phys 0..252
          signal StatusCPDData3FBD_VR_CIRData00: start 32, 8 bit, little-endian, data-type-policy=OVERRIDE, base-type=uint8, compu {phys=raw}, range phys 0..255
          signal StatusCPDData3FBD_VR_CIRData01: start 40, 8 bit, little-endian, data-type-policy=OVERRIDE, base-type=uint8, compu {phys=raw}, range phys 0..255
          signal StatusCPDData3FBD_VR_CIRData02: start 48, 8 bit, little-endian, data-type-policy=OVERRIDE, base-type=uint8, compu {phys=raw}, range phys 0..255
          signal StatusCPDData3FBD_VR_CIRData03: start 56, 8 bit, little-endian, data-type-policy=OVERRIDE, base-type=uint8, compu {phys=raw}, range phys 0..255
          signal StatusCPDData3FBD_VR_CIRData04: start 64, 8 bit, little-endian, data-type-policy=OVERRIDE, base-type=uint8, compu {phys=raw}, range phys 0..255
          signal StatusCPDData3FBD_VR_CIRData05: start 72, 8 bit, little-endian, data-type-policy=OVERRIDE, base-type=uint8, compu {phys=raw}, range phys 0..255
          signal StatusCPDData3FBD_VR_CIRData06: start 80, 8 bit, little-endian, data-type-policy=OVERRIDE, base-type=uint8, compu {phys=raw}, range phys 0..255
          signal StatusCPDData3FBD_VR_CIRData07: start 88, 8 bit, little-endian, data-type-policy=OVERRIDE, base-type=uint8, compu {phys=raw}, range phys 0..255
          signal StatusCPDData3FBD_VR_CIRData08: start 96, 8 bit, little-endian, data-type-policy=OVERRIDE, base-type=uint8, compu {phys=raw}, range phys 0..255
          signal StatusCPDData3FBD_VR_CIRData09: start 104, 8 bit, little-endian, data-type-policy=OVERRIDE, base-type=uint8, compu {phys=raw}, range phys 0..255
          signal StatusCPDData3FBD_VR_CIRData10: start 112, 8 bit, little-endian, data-type-policy=OVERRIDE, base-type=uint8, compu {phys=raw}, range phys 0..255
          signal StatusCPDData3FBD_VR_CIRData11: start 120, 8 bit, little-endian, data-type-policy=OVERRIDE, base-type=uint8, compu {phys=raw}, range phys 0..255
          signal StatusCPDData3FBD_VR_CIRData12: start 128, 8 bit, little-endian, data-type-policy=OVERRIDE, base-type=uint8, compu {phys=raw}, range phys 0..255
          signal StatusCPDData3FBD_VR_CIRData13: start 136, 8 bit, little-endian, data-type-policy=OVERRIDE, base-type=uint8, compu {phys=raw}, range phys 0..255
          signal StatusCPDData3FBD_VR_CIRData14: start 144, 8 bit, little-endian, data-type-policy=OVERRIDE, base-type=uint8, compu {phys=raw}, range phys 0..255
          signal StatusCPDData3FBD_VR_CIRData15: start 152, 8 bit, little-endian, data-type-policy=OVERRIDE, base-type=uint8, compu {phys=raw}, range phys 0..255
          signal StatusCPDData3FBD_VR_CIRData16: start 160, 8 bit, little-endian, data-type-policy=OVERRIDE, base-type=uint8, compu {phys=raw}, range phys 0..255
          signal StatusCPDData3FBD_VR_CIRData17: start 168, 8 bit, little-endian, data-type-policy=OVERRIDE, base-type=uint8, compu {phys=raw}, range phys 0..255
          signal StatusCPDData3FBD_VR_CIRData18: start 176, 8 bit, little-endian, data-type-policy=OVERRIDE, base-type=uint8, compu {phys=raw}, range phys 0..255
          signal StatusCPDData3FBD_VR_CIRData19: start 184, 8 bit, little-endian, data-type-policy=OVERRIDE, base-type=uint8, compu {phys=raw}, range phys 0..255
          signal StatusCPDData3FBD_VR_CIRData20: start 192, 8 bit, little-endian, data-type-policy=OVERRIDE, base-type=uint8, compu {phys=raw}, range phys 0..255
          signal StatusCPDData3FBD_VR_CIRData21: start 200, 8 bit, little-endian, data-type-policy=OVERRIDE, base-type=uint8, compu {phys=raw}, range phys 0..255
          signal StatusCPDData3FBD_VR_CIRData22: start 208, 8 bit, little-endian, data-type-policy=OVERRIDE, base-type=uint8, compu {phys=raw}, range phys 0..255
          signal StatusCPDData3FBD_VR_CIRData23: start 216, 8 bit, little-endian, data-type-policy=OVERRIDE, base-type=uint8, compu {phys=raw}, range phys 0..255
          signal StatusCPDData3FBD_VR_CIRData24: start 224, 8 bit, little-endian, data-type-policy=OVERRIDE, base-type=uint8, compu {phys=raw}, range phys 0..255
          signal StatusCPDData3FBD_VR_CIRData25: start 232, 8 bit, little-endian, data-type-policy=OVERRIDE, base-type=uint8, compu {phys=raw}, range phys 0..255
          signal StatusCPDData3FBD_VR_CIRData26: start 240, 8 bit, little-endian, data-type-policy=OVERRIDE, base-type=uint8, compu {phys=raw}, range phys 0..255
          signal StatusCPDData3FBD_VR_CIRData27: start 248, 8 bit, little-endian, data-type-policy=OVERRIDE, base-type=uint8, compu {phys=raw}, range phys 0..255
          signal StatusCPDData3FBD_VR_CIRData28: start 256, 8 bit, little-endian, data-type-policy=OVERRIDE, base-type=uint8, compu {phys=raw}, range phys 0..255
          signal StatusCPDData3FBD_VR_CIRData29: start 264, 8 bit, little-endian, data-type-policy=OVERRIDE, base-type=uint8, compu {phys=raw}, range phys 0..255
          signal StatusCPDData3FBD_VR_CIRData30: start 272, 8 bit, little-endian, data-type-policy=OVERRIDE, base-type=uint8, compu {phys=raw}, range phys 0..255
          signal StatusCPDData3FBD_VR_CIRData31: start 280, 8 bit, little-endian, data-type-policy=OVERRIDE, base-type=uint8, compu {phys=raw}, range phys 0..255
          signal StatusCPDData3FBD_VR_CIRData32: start 288, 8 bit, little-endian, data-type-policy=OVERRIDE, base-type=uint8, compu {phys=raw}, range phys 0..255
          signal StatusCPDData3FBD_VR_CIRData33: start 296, 8 bit, little-endian, data-type-policy=OVERRIDE, base-type=uint8, compu {phys=raw}, range phys 0..255
          signal StatusCPDData3FBD_VR_CIRData34: start 304, 8 bit, little-endian, data-type-policy=OVERRIDE, base-type=uint8, compu {phys=raw}, range phys 0..255
          signal StatusCPDData3FBD_VR_CIRData35: start 312, 8 bit, little-endian, data-type-policy=OVERRIDE, base-type=uint8, compu {phys=raw}, range phys 0..255
          signal StatusCPDData3FBD_VR_CIRData36: start 320, 8 bit, little-endian, data-type-policy=OVERRIDE, base-type=uint8, compu {phys=raw}, range phys 0..255
          signal StatusCPDData3FBD_VR_CIRData37: start 328, 8 bit, little-endian, data-type-policy=OVERRIDE, base-type=uint8, compu {phys=raw}, range phys 0..255
          signal StatusCPDData3FBD_VR_CIRData38: start 336, 8 bit, little-endian, data-type-policy=OVERRIDE, base-type=uint8, compu {phys=raw}, range phys 0..255
          signal StatusCPDData3FBD_VR_CIRData39: start 344, 8 bit, little-endian, data-type-policy=OVERRIDE, base-type=uint8, compu {phys=raw}, range phys 0..255
          signal StatusCPDData3FBD_VR_CIRData40: start 352, 8 bit, little-endian, data-type-policy=OVERRIDE, base-type=uint8, compu {phys=raw}, range phys 0..255
          signal StatusCPDData3FBD_VR_CIRData41: start 360, 8 bit, little-endian, data-type-policy=OVERRIDE, base-type=uint8, compu {phys=raw}, range phys 0..255
          signal StatusCPDData3FBD_VR_CIRData42: start 368, 8 bit, little-endian, data-type-policy=OVERRIDE, base-type=uint8, compu {phys=raw}, range phys 0..255
          signal StatusCPDData3FBD_VR_CIRData43: start 376, 8 bit, little-endian, data-type-policy=OVERRIDE, base-type=uint8, compu {phys=raw}, range phys 0..255
          signal StatusCPDData3FBD_VR_CIRData44: start 384, 8 bit, little-endian, data-type-policy=OVERRIDE, base-type=uint8, compu {phys=raw}, range phys 0..255
          signal StatusCPDData3FBD_VR_CIRData45: start 392, 8 bit, little-endian, data-type-policy=OVERRIDE, base-type=uint8, compu {phys=raw}, range phys 0..255
          signal StatusCPDData3FBD_VR_CIRData46: start 400, 8 bit, little-endian, data-type-policy=OVERRIDE, base-type=uint8, compu {phys=raw}, range phys 0..255
          signal StatusCPDData3FBD_VR_CIRData47: start 408, 8 bit, little-endian, data-type-policy=OVERRIDE, base-type=uint8, compu {phys=raw}, range phys 0..255
          signal StatusCPDData3FBD_VR_CIRData48: start 416, 8 bit, little-endian, data-type-policy=OVERRIDE, base-type=uint8, compu {phys=raw}, range phys 0..255
          signal StatusCPDData3FBD_VR_CIRData49: start 424, 8 bit, little-endian, data-type-policy=OVERRIDE, base-type=uint8, compu {phys=raw}, range phys 0..255
          signal StatusCPDData3FBD_VR_CIRData50: start 432, 8 bit, little-endian, data-type-policy=OVERRIDE, base-type=uint8, compu {phys=raw}, range phys 0..255
          signal StatusCPDData3FBD_VR_CIRData51: start 440, 8 bit, little-endian, data-type-policy=OVERRIDE, base-type=uint8, compu {phys=raw}, range phys 0..255
          signal StatusCPDData3FBD_VR_CIRData52: start 448, 8 bit, little-endian, data-type-policy=OVERRIDE, base-type=uint8, compu {phys=raw}, range phys 0..255
          signal StatusCPDData3FBD_VR_CIRData53: start 456, 8 bit, little-endian, data-type-policy=OVERRIDE, base-type=uint8, compu {phys=raw}, range phys 0..255
          signal StatusCPDData3FBD_VR_CIRData54: start 464, 8 bit, little-endian, data-type-policy=OVERRIDE, base-type=uint8, compu {phys=raw}, range phys 0..255
          signal StatusCPDData3FBD_VR_CIRData55: start 472, 8 bit, little-endian, data-type-policy=OVERRIDE, base-type=uint8, compu {phys=raw}, range phys 0..255
          signal StatusCPDData3FBD_VR_CIRData56: start 480, 8 bit, little-endian, data-type-policy=OVERRIDE, base-type=uint8, compu {phys=raw}, range phys 0..255
          signal StatusCPDData3FBD_VR_CIRData57: start 488, 8 bit, little-endian, data-type-policy=OVERRIDE, base-type=uint8, compu {phys=raw}, range phys 0..255
          signal StatusCPDData3FBD_VR_CIRData58: start 496, 8 bit, little-endian, data-type-policy=OVERRIDE, base-type=uint8, compu {phys=raw}, range phys 0..255
          signal StatusCPDData3FBD_VR_CIRData59: start 504, 8 bit, little-endian, data-type-policy=OVERRIDE, base-type=uint8, compu {phys=raw}, range phys 0..255
      frame StatusCPDData4FBD_HL: id 0x16E, frame-length=64, can-addressing-mode=STANDARD, can-frame-rx-behavior=CAN-FD, can-frame-tx-behavior=CAN-FD
        pdu StatusCPDData4FBD_HL: length=64, unused-bit-pattern=0
          signal StatusCPDData4FBD_HL_MsgCounter: start 0, 8 bit, little-endian, data-type-policy=OVERRIDE, base-type=uint8, compu {phys=raw}, range phys 0..252
          signal StatusCPDData4FBD_HL_LinkID: start 8, 8 bit, little-endian, data-type-policy=OVERRIDE, base-type=uint8, compu {phys=raw}, range phys 0..252
          signal StatusCPDData4FBD_HL_CollisionCounter: start 16, 8 bit, little-endian, data-type-policy=OVERRIDE, base-type=uint8, compu {phys=raw}, range phys 0..252
          signal StatusCPDData4FBD_HL_CIRSetting: start 24, 8 bit, little-endian, data-type-policy=OVERRIDE, compu {phys=raw}
          signal StatusCPDData4FBD_HL_CIRData60: start 32, 8 bit, little-endian, data-type-policy=OVERRIDE, base-type=uint8, compu {phys=raw}, range phys 0..255
          signal StatusCPDData4FBD_HL_CIRData61: start 40, 8 bit, little-endian, data-type-policy=OVERRIDE, base-type=uint8, compu {phys=raw}, range phys 0..255
          signal StatusCPDData4FBD_HL_CIRData62: start 48, 8 bit, little-endian, data-type-policy=OVERRIDE, base-type=uint8, compu {phys=raw}, range phys 0..255
          signal StatusCPDData4FBD_HL_CIRData63: start 56, 8 bit, little-endian, data-type-policy=OVERRIDE, base-type=uint8, compu {phys=raw}, range phys 0..255
          signal StatusCPDData4FBD_HL_CIRData64: start 64, 8 bit, little-endian, data-type-policy=OVERRIDE, base-type=uint8, compu {phys=raw}, range phys 0..255
          signal StatusCPDData4FBD_HL_CIRData65: start 72, 8 bit, little-endian, data-type-policy=OVERRIDE, base-type=uint8, compu {phys=raw}, range phys 0..255
          signal StatusCPDData4FBD_HL_CIRData66: start 80, 8 bit, little-endian, data-type-policy=OVERRIDE, base-type=uint8, compu {phys=raw}, range phys 0..255
          signal StatusCPDData4FBD_HL_CIRData67: start 88, 8 bit, little-endian, data-type-policy=OVERRIDE, base-type=uint8, compu {phys=raw}, range phys 0..255
          signal StatusCPDData4FBD_HL_CIRData68: start 96, 8 bit, little-endian, data-type-policy=OVERRIDE, base-type=uint8, compu {phys=raw}, range phys 0..255
          signal StatusCPDData4FBD_HL_CIRData69: start 104, 8 bit, little-endian, data-type-policy=OVERRIDE, base-type=uint8, compu {phys=raw}, range phys 0..255
          signal StatusCPDData4FBD_HL_CIRData70: start 112, 8 bit, little-endian, data-type-policy=OVERRIDE, base-type=uint8, compu {phys=raw}, range phys 0..255
          signal StatusCPDData4FBD_HL_CIRData71: start 120, 8 bit, little-endian, data-type-policy=OVERRIDE, base-type=uint8, compu {phys=raw}, range phys 0..255
          signal StatusCPDData4FBD_HL_CIRData72: start 128, 8 bit, little-endian, data-type-policy=OVERRIDE, base-type=uint8, compu {phys=raw}, range phys 0..255
          signal StatusCPDData4FBD_HL_CIRData73: start 136, 8 bit, little-endian, data-type-policy=OVERRIDE, base-type=uint8, compu {phys=raw}, range phys 0..255
          signal StatusCPDData4FBD_HL_CIRData74: start 144, 8 bit, little-endian, data-type-policy=OVERRIDE, base-type=uint8, compu {phys=raw}, range phys 0..255
          signal StatusCPDData4FBD_HL_CIRData75: start 152, 8 bit, little-endian, data-type-policy=OVERRIDE, base-type=uint8, compu {phys=raw}, range phys 0..255
          signal StatusCPDData4FBD_HL_CIRData76: start 160, 8 bit, little-endian, data-type-policy=OVERRIDE, base-type=uint8, compu {phys=raw}, range phys 0..255
          signal StatusCPDData4FBD_HL_CIRData77: start 168, 8 bit, little-endian, data-type-policy=OVERRIDE, base-type=uint8, compu {phys=raw}, range phys 0..255
          signal StatusCPDData4FBD_HL_CIRData78: start 176, 8 bit, little-endian, data-type-policy=OVERRIDE, base-type=uint8, compu {phys=raw}, range phys 0..255
          signal StatusCPDData4FBD_HL_CIRData79: start 184, 8 bit, little-endian, data-type-policy=OVERRIDE, base-type=uint8, compu {phys=raw}, range phys 0..255
          signal StatusCPDData4FBD_HL_CIRData80: start 192, 8 bit, little-endian, data-type-policy=OVERRIDE, base-type=uint8, compu {phys=raw}, range phys 0..255
          signal StatusCPDData4FBD_HL_CIRData81: start 200, 8 bit, little-endian, data-type-policy=OVERRIDE, base-type=uint8, compu {phys=raw}, range phys 0..255
          signal StatusCPDData4FBD_HL_CIRData82: start 208, 8 bit, little-endian, data-type-policy=OVERRIDE, base-type=uint8, compu {phys=raw}, range phys 0..255
          signal StatusCPDData4FBD_HL_CIRData83: start 216, 8 bit, little-endian, data-type-policy=OVERRIDE, base-type=uint8, compu {phys=raw}, range phys 0..255
          signal StatusCPDData4FBD_HL_CIRData84: start 224, 8 bit, little-endian, data-type-policy=OVERRIDE, base-type=uint8, compu {phys=raw}, range phys 0..255
          signal StatusCPDData4FBD_HL_CIRData85: start 232, 8 bit, little-endian, data-type-policy=OVERRIDE, base-type=uint8, compu {phys=raw}, range phys 0..255
          signal StatusCPDData4FBD_HL_CIRData86: start 240, 8 bit, little-endian, data-type-policy=OVERRIDE, base-type=uint8, compu {phys=raw}, range phys 0..255
          signal StatusCPDData4FBD_HL_CIRData87: start 248, 8 bit, little-endian, data-type-policy=OVERRIDE, base-type=uint8, compu {phys=raw}, range phys 0..255
          signal StatusCPDData4FBD_HL_CIRData88: start 256, 8 bit, little-endian, data-type-policy=OVERRIDE, base-type=uint8, compu {phys=raw}, range phys 0..255
          signal StatusCPDData4FBD_HL_CIRData89: start 264, 8 bit, little-endian, data-type-policy=OVERRIDE, base-type=uint8, compu {phys=raw}, range phys 0..255
          signal StatusCPDData4FBD_HL_CIRData90: start 272, 8 bit, little-endian, data-type-policy=OVERRIDE, base-type=uint8, compu {phys=raw}, range phys 0..255
          signal StatusCPDData4FBD_HL_CIRData91: start 280, 8 bit, little-endian, data-type-policy=OVERRIDE, base-type=uint8, compu {phys=raw}, range phys 0..255
          signal StatusCPDData4FBD_HL_CIRData92: start 288, 8 bit, little-endian, data-type-policy=OVERRIDE, base-type=uint8, compu {phys=raw}, range phys 0..255
          signal StatusCPDData4FBD_HL_CIRData93: start 296, 8 bit, little-endian, data-type-policy=OVERRIDE, base-type=uint8, compu {phys=raw}, range phys 0..255
          signal StatusCPDData4FBD_HL_CIRData94: start 304, 8 bit, little-endian, data-type-policy=OVERRIDE, base-type=uint8, compu {phys=raw}, range phys 0..255
          signal StatusCPDData4FBD_HL_CIRData95: start 312, 8 bit, little-endian, data-type-policy=OVERRIDE, base-type=uint8, compu {phys=raw}, range phys 0..255
          signal StatusCPDData4FBD_HL_CIRData96: start 320, 8 bit, little-endian, data-type-policy=OVERRIDE, base-type=uint8, compu {phys=raw}, range phys 0..255
          signal StatusCPDData4FBD_HL_CIRData97: start 328, 8 bit, little-endian, data-type-policy=OVERRIDE, base-type=uint8, compu {phys=raw}, range phys 0..255
          signal StatusCPDData4FBD_HL_CIRData98: start 336, 8 bit, little-endian, data-type-policy=OVERRIDE, base-type=uint8, compu {phys=raw}, range phys 0..255
          signal StatusCPDData4FBD_HL_CIRData99: start 344, 8 bit, little-endian, data-type-policy=OVERRIDE, base-type=uint8, compu {phys=raw}, range phys 0..255
          signal StatusCPDData4FBD_HL_CIRData100: start 352, 8 bit, little-endian, data-type-policy=OVERRIDE, base-type=uint8, compu {phys=raw}, range phys 0..255
          signal StatusCPDData4FBD_HL_CIRData101: start 360, 8 bit, little-endian, data-type-policy=OVERRIDE, base-type=uint8, compu {phys=raw}, range phys 0..255
          signal StatusCPDData4FBD_HL_CIRData102: start 368, 8 bit, little-endian, data-type-policy=OVERRIDE, base-type=uint8, compu {phys=raw}, range phys 0..255
          signal StatusCPDData4FBD_HL_CIRData103: start 376, 8 bit, little-endian, data-type-policy=OVERRIDE, base-type=uint8, compu {phys=raw}, range phys 0..255
          signal StatusCPDData4FBD_HL_CIRData104: start 384, 8 bit, little-endian, data-type-policy=OVERRIDE, base-type=uint8, compu {phys=raw}, range phys 0..255
          signal StatusCPDData4FBD_HL_CIRData105: start 392, 8 bit, little-endian, data-type-policy=OVERRIDE, base-type=uint8, compu {phys=raw}, range phys 0..255
          signal StatusCPDData4FBD_HL_CIRData106: start 400, 8 bit, little-endian, data-type-policy=OVERRIDE, base-type=uint8, compu {phys=raw}, range phys 0..255
          signal StatusCPDData4FBD_HL_CIRData107: start 408, 8 bit, little-endian, data-type-policy=OVERRIDE, base-type=uint8, compu {phys=raw}, range phys 0..255
          signal StatusCPDData4FBD_HL_CIRData108: start 416, 8 bit, little-endian, data-type-policy=OVERRIDE, base-type=uint8, compu {phys=raw}, range phys 0..255
          signal StatusCPDData4FBD_HL_CIRData109: start 424, 8 bit, little-endian, data-type-policy=OVERRIDE, base-type=uint8, compu {phys=raw}, range phys 0..255
          signal StatusCPDData4FBD_HL_CIRData110: start 432, 8 bit, little-endian, data-type-policy=OVERRIDE, base-type=uint8, compu {phys=raw}, range phys 0..255
          signal StatusCPDData4FBD_HL_CIRData111: start 440, 8 bit, little-endian, data-type-policy=OVERRIDE, base-type=uint8, compu {phys=raw}, range phys 0..255
          signal StatusCPDData4FBD_HL_CIRData112: start 448, 8 bit, little-endian, data-type-policy=OVERRIDE, base-type=uint8, compu {phys=raw}, range phys 0..255
          signal StatusCPDData4FBD_HL_CIRData113: start 456, 8 bit, little-endian, data-type-policy=OVERRIDE, base-type=uint8, compu {phys=raw}, range phys 0..255
          signal StatusCPDData4FBD_HL_CIRData114: start 464, 8 bit, little-endian, data-type-policy=OVERRIDE, base-type=uint8, compu {phys=raw}, range phys 0..255
          signal StatusCPDData4FBD_HL_CIRData115: start 472, 8 bit, little-endian, data-type-policy=OVERRIDE, base-type=uint8, compu {phys=raw}, range phys 0..255
          signal StatusCPDData4FBD_HL_CIRData116: start 480, 8 bit, little-endian, data-type-policy=OVERRIDE, base-type=uint8, compu {phys=raw}, range phys 0..255
          signal StatusCPDData4FBD_HL_CIRData117: start 488, 8 bit, little-endian, data-type-policy=OVERRIDE, base-type=uint8, compu {phys=raw}, range phys 0..255
          signal StatusCPDData4FBD_HL_CIRData118: start 496, 8 bit, little-endian, data-type-policy=OVERRIDE, base-type=uint8, compu {phys=raw}, range phys 0..255
          signal StatusCPDData4FBD_HL_CIRData119: start 504, 8 bit, little-endian, data-type-policy=OVERRIDE, base-type=uint8, compu {phys=raw}, range phys 0..255
      frame StatusCPDData4FBD_HM: id 0x169, frame-length=64, can-addressing-mode=STANDARD, can-frame-rx-behavior=CAN-FD, can-frame-tx-behavior=CAN-FD
        pdu StatusCPDData4FBD_HM: length=64, unused-bit-pattern=0
          signal StatusCPDData4FBD_HM_MsgCounter: start 0, 8 bit, little-endian, data-type-policy=OVERRIDE, base-type=uint8, compu {phys=raw}, range phys 0..252
          signal StatusCPDData4FBD_HM_LinkID: start 8, 8 bit, little-endian, data-type-policy=OVERRIDE, base-type=uint8, compu {phys=raw}, range phys 0..252
          signal StatusCPDData4FBD_HM_CollisionCounter: start 16, 8 bit, little-endian, data-type-policy=OVERRIDE, base-type=uint8, compu {phys=raw}, range phys 0..252
          signal StatusCPDData4FBD_HM_CIRSetting: start 24, 8 bit, little-endian, data-type-policy=OVERRIDE, compu {phys=raw}
          signal StatusCPDData4FBD_HM_CIRData60: start 32, 8 bit, little-endian, data-type-policy=OVERRIDE, base-type=uint8, compu {phys=raw}, range phys 0..255
          signal StatusCPDData4FBD_HM_CIRData61: start 40, 8 bit, little-endian, data-type-policy=OVERRIDE, base-type=uint8, compu {phys=raw}, range phys 0..255
          signal StatusCPDData4FBD_HM_CIRData62: start 48, 8 bit, little-endian, data-type-policy=OVERRIDE, base-type=uint8, compu {phys=raw}, range phys 0..255
          signal StatusCPDData4FBD_HM_CIRData63: start 56, 8 bit, little-endian, data-type-policy=OVERRIDE, base-type=uint8, compu {phys=raw}, range phys 0..255
          signal StatusCPDData4FBD_HM_CIRData64: start 64, 8 bit, little-endian, data-type-policy=OVERRIDE, base-type=uint8, compu {phys=raw}, range phys 0..255
          signal StatusCPDData4FBD_HM_CIRData65: start 72, 8 bit, little-endian, data-type-policy=OVERRIDE, base-type=uint8, compu {phys=raw}, range phys 0..255
          signal StatusCPDData4FBD_HM_CIRData66: start 80, 8 bit, little-endian, data-type-policy=OVERRIDE, base-type=uint8, compu {phys=raw}, range phys 0..255
          signal StatusCPDData4FBD_HM_CIRData67: start 88, 8 bit, little-endian, data-type-policy=OVERRIDE, base-type=uint8, compu {phys=raw}, range phys 0..255
          signal StatusCPDData4FBD_HM_CIRData68: start 96, 8 bit, little-endian, data-type-policy=OVERRIDE, base-type=uint8, compu {phys=raw}, range phys 0..255
          signal StatusCPDData4FBD_HM_CIRData69: start 104, 8 bit, little-endian, data-type-policy=OVERRIDE, base-type=uint8, compu {phys=raw}, range phys 0..255
          signal StatusCPDData4FBD_HM_CIRData70: start 112, 8 bit, little-endian, data-type-policy=OVERRIDE, base-type=uint8, compu {phys=raw}, range phys 0..255
          signal StatusCPDData4FBD_HM_CIRData71: start 120, 8 bit, little-endian, data-type-policy=OVERRIDE, base-type=uint8, compu {phys=raw}, range phys 0..255
          signal StatusCPDData4FBD_HM_CIRData72: start 128, 8 bit, little-endian, data-type-policy=OVERRIDE, base-type=uint8, compu {phys=raw}, range phys 0..255
          signal StatusCPDData4FBD_HM_CIRData73: start 136, 8 bit, little-endian, data-type-policy=OVERRIDE, base-type=uint8, compu {phys=raw}, range phys 0..255
          signal StatusCPDData4FBD_HM_CIRData74: start 144, 8 bit, little-endian, data-type-policy=OVERRIDE, base-type=uint8, compu {phys=raw}, range phys 0..255
          signal StatusCPDData4FBD_HM_CIRData75: start 152, 8 bit, little-endian, data-type-policy=OVERRIDE, base-type=uint8, compu {phys=raw}, range phys 0..255
          signal StatusCPDData4FBD_HM_CIRData76: start 160, 8 bit, little-endian, data-type-policy=OVERRIDE, base-type=uint8, compu {phys=raw}, range phys 0..255
          signal StatusCPDData4FBD_HM_CIRData77: start 168, 8 bit, little-endian, data-type-policy=OVERRIDE, base-type=uint8, compu {phys=raw}, range phys 0..255
          signal StatusCPDData4FBD_HM_CIRData78: start 176, 8 bit, little-endian, data-type-policy=OVERRIDE, base-type=uint8, compu {phys=raw}, range phys 0..255
          signal StatusCPDData4FBD_HM_CIRData79: start 184, 8 bit, little-endian, data-type-policy=OVERRIDE, base-type=uint8, compu {phys=raw}, range phys 0..255
          signal StatusCPDData4FBD_HM_CIRData80: start 192, 8 bit, little-endian, data-type-policy=OVERRIDE, base-type=uint8, compu {phys=raw}, range phys 0..255
          signal StatusCPDData4FBD_HM_CIRData81: start 200, 8 bit, little-endian, data-type-policy=OVERRIDE, base-type=uint8, compu {phys=raw}, range phys 0..255
          signal StatusCPDData4FBD_HM_CIRData82: start 208, 8 bit, little-endian, data-type-policy=OVERRIDE, base-type=uint8, compu {phys=raw}, range phys 0..255
          signal StatusCPDData4FBD_HM_CIRData83: start 216, 8 bit, little-endian, data-type-policy=OVERRIDE, base-type=uint8, compu {phys=raw}, range phys 0..255
          signal StatusCPDData4FBD_HM_CIRData84: start 224, 8 bit, little-endian, data-type-policy=OVERRIDE, base-type=uint8, compu {phys=raw}, range phys 0..255
          signal StatusCPDData4FBD_HM_CIRData85: start 232, 8 bit, little-endian, data-type-policy=OVERRIDE, base-type=uint8, compu {phys=raw}, range phys 0..255
          signal StatusCPDData4FBD_HM_CIRData86: start 240, 8 bit, little-endian, data-type-policy=OVERRIDE, base-type=uint8, compu {phys=raw}, range phys 0..255
          signal StatusCPDData4FBD_HM_CIRData87: start 248, 8 bit, little-endian, data-type-policy=OVERRIDE, base-type=uint8, compu {phys=raw}, range phys 0..255
          signal StatusCPDData4FBD_HM_CIRData88: start 256, 8 bit, little-endian, data-type-policy=OVERRIDE, base-type=uint8, compu {phys=raw}, range phys 0..255
          signal StatusCPDData4FBD_HM_CIRData89: start 264, 8 bit, little-endian, data-type-policy=OVERRIDE, base-type=uint8, compu {phys=raw}, range phys 0..255
          signal StatusCPDData4FBD_HM_CIRData90: start 272, 8 bit, little-endian, data-type-policy=OVERRIDE, base-type=uint8, compu {phys=raw}, range phys 0..255
          signal StatusCPDData4FBD_HM_CIRData91: start 280, 8 bit, little-endian, data-type-policy=OVERRIDE, base-type=uint8, compu {phys=raw}, range phys 0..255
          signal StatusCPDData4FBD_HM_CIRData92: start 288, 8 bit, little-endian, data-type-policy=OVERRIDE, base-type=uint8, compu {phys=raw}, range phys 0..255
          signal StatusCPDData4FBD_HM_CIRData93: start 296, 8 bit, little-endian, data-type-policy=OVERRIDE, base-type=uint8, compu {phys=raw}, range phys 0..255
          signal StatusCPDData4FBD_HM_CIRData94: start 304, 8 bit, little-endian, data-type-policy=OVERRIDE, base-type=uint8, compu {phys=raw}, range phys 0..255
          signal StatusCPDData4FBD_HM_CIRData95: start 312, 8 bit, little-endian, data-type-policy=OVERRIDE, base-type=uint8, compu {phys=raw}, range phys 0..255
          signal StatusCPDData4FBD_HM_CIRData96: start 320, 8 bit, little-endian, data-type-policy=OVERRIDE, base-type=uint8, compu {phys=raw}, range phys 0..255
          signal StatusCPDData4FBD_HM_CIRData97: start 328, 8 bit, little-endian, data-type-policy=OVERRIDE, base-type=uint8, compu {phys=raw}, range phys 0..255
          signal StatusCPDData4FBD_HM_CIRData98: start 336, 8 bit, little-endian, data-type-policy=OVERRIDE, base-type=uint8, compu {phys=raw}, range phys 0..255
          signal StatusCPDData4FBD_HM_CIRData99: start 344, 8 bit, little-endian, data-type-policy=OVERRIDE, base-type=uint8, compu {phys=raw}, range phys 0..255
          signal StatusCPDData4FBD_HM_CIRData100: start 352, 8 bit, little-endian, data-type-policy=OVERRIDE, base-type=uint8, compu {phys=raw}, range phys 0..255
          signal StatusCPDData4FBD_HM_CIRData101: start 360, 8 bit, little-endian, data-type-policy=OVERRIDE, base-type=uint8, compu {phys=raw}, range phys 0..255
          signal StatusCPDData4FBD_HM_CIRData102: start 368, 8 bit, little-endian, data-type-policy=OVERRIDE, base-type=uint8, compu {phys=raw}, range phys 0..255
          signal StatusCPDData4FBD_HM_CIRData103: start 376, 8 bit, little-endian, data-type-policy=OVERRIDE, base-type=uint8, compu {phys=raw}, range phys 0..255
          signal StatusCPDData4FBD_HM_CIRData104: start 384, 8 bit, little-endian, data-type-policy=OVERRIDE, base-type=uint8, compu {phys=raw}, range phys 0..255
          signal StatusCPDData4FBD_HM_CIRData105: start 392, 8 bit, little-endian, data-type-policy=OVERRIDE, base-type=uint8, compu {phys=raw}, range phys 0..255
          signal StatusCPDData4FBD_HM_CIRData106: start 400, 8 bit, little-endian, data-type-policy=OVERRIDE, base-type=uint8, compu {phys=raw}, range phys 0..255
          signal StatusCPDData4FBD_HM_CIRData107: start 408, 8 bit, little-endian, data-type-policy=OVERRIDE, base-type=uint8, compu {phys=raw}, range phys 0..255
          signal StatusCPDData4FBD_HM_CIRData108: start 416, 8 bit, little-endian, data-type-policy=OVERRIDE, base-type=uint8, compu {phys=raw}, range phys 0..255
          signal StatusCPDData4FBD_HM_CIRData109: start 424, 8 bit, little-endian, data-type-policy=OVERRIDE, base-type=uint8, compu {phys=raw}, range phys 0..255
          signal StatusCPDData4FBD_HM_CIRData110: start 432, 8 bit, little-endian, data-type-policy=OVERRIDE, base-type=uint8, compu {phys=raw}, range phys 0..255
          signal StatusCPDData4FBD_HM_CIRData111: start 440, 8 bit, little-endian, data-type-policy=OVERRIDE, base-type=uint8, compu {phys=raw}, range phys 0..255
          signal StatusCPDData4FBD_HM_CIRData112: start 448, 8 bit, little-endian, data-type-policy=OVERRIDE, base-type=uint8, compu {phys=raw}, range phys 0..255
          signal StatusCPDData4FBD_HM_CIRData113: start 456, 8 bit, little-endian, data-type-policy=OVERRIDE, base-type=uint8, compu {phys=raw}, range phys 0..255
          signal StatusCPDData4FBD_HM_CIRData114: start 464, 8 bit, little-endian, data-type-policy=OVERRIDE, base-type=uint8, compu {phys=raw}, range phys 0..255
          signal StatusCPDData4FBD_HM_CIRData115: start 472, 8 bit, little-endian, data-type-policy=OVERRIDE, base-type=uint8, compu {phys=raw}, range phys 0..255
          signal StatusCPDData4FBD_HM_CIRData116: start 480, 8 bit, little-endian, data-type-policy=OVERRIDE, base-type=uint8, compu {phys=raw}, range phys 0..255
          signal StatusCPDData4FBD_HM_CIRData117: start 488, 8 bit, little-endian, data-type-policy=OVERRIDE, base-type=uint8, compu {phys=raw}, range phys 0..255
          signal StatusCPDData4FBD_HM_CIRData118: start 496, 8 bit, little-endian, data-type-policy=OVERRIDE, base-type=uint8, compu {phys=raw}, range phys 0..255
          signal StatusCPDData4FBD_HM_CIRData119: start 504, 8 bit, little-endian, data-type-policy=OVERRIDE, base-type=uint8, compu {phys=raw}, range phys 0..255
      frame StatusCPDData4FBD_HR: id 0x16F, frame-length=64, can-addressing-mode=STANDARD, can-frame-rx-behavior=CAN-FD, can-frame-tx-behavior=CAN-FD
        pdu StatusCPDData4FBD_HR: length=64, unused-bit-pattern=0
          signal StatusCPDData4FBD_HR_MsgCounter: start 0, 8 bit, little-endian, data-type-policy=OVERRIDE, base-type=uint8, compu {phys=raw}, range phys 0..252
          signal StatusCPDData4FBD_HR_LinkID: start 8, 8 bit, little-endian, data-type-policy=OVERRIDE, base-type=uint8, compu {phys=raw}, range phys 0..252
          signal StatusCPDData4FBD_HR_CollisionCounter: start 16, 8 bit, little-endian, data-type-policy=OVERRIDE, base-type=uint8, compu {phys=raw}, range phys 0..252
          signal StatusCPDData4FBD_HR_CIRSetting: start 24, 8 bit, little-endian, data-type-policy=OVERRIDE, compu {phys=raw}
          signal StatusCPDData4FBD_HR_CIRData60: start 32, 8 bit, little-endian, data-type-policy=OVERRIDE, base-type=uint8, compu {phys=raw}, range phys 0..255
          signal StatusCPDData4FBD_HR_CIRData61: start 40, 8 bit, little-endian, data-type-policy=OVERRIDE, base-type=uint8, compu {phys=raw}, range phys 0..255
          signal StatusCPDData4FBD_HR_CIRData62: start 48, 8 bit, little-endian, data-type-policy=OVERRIDE, base-type=uint8, compu {phys=raw}, range phys 0..255
          signal StatusCPDData4FBD_HR_CIRData63: start 56, 8 bit, little-endian, data-type-policy=OVERRIDE, base-type=uint8, compu {phys=raw}, range phys 0..255
          signal StatusCPDData4FBD_HR_CIRData64: start 64, 8 bit, little-endian, data-type-policy=OVERRIDE, base-type=uint8, compu {phys=raw}, range phys 0..255
          signal StatusCPDData4FBD_HR_CIRData65: start 72, 8 bit, little-endian, data-type-policy=OVERRIDE, base-type=uint8, compu {phys=raw}, range phys 0..255
          signal StatusCPDData4FBD_HR_CIRData66: start 80, 8 bit, little-endian, data-type-policy=OVERRIDE, base-type=uint8, compu {phys=raw}, range phys 0..255
          signal StatusCPDData4FBD_HR_CIRData67: start 88, 8 bit, little-endian, data-type-policy=OVERRIDE, base-type=uint8, compu {phys=raw}, range phys 0..255
          signal StatusCPDData4FBD_HR_CIRData68: start 96, 8 bit, little-endian, data-type-policy=OVERRIDE, base-type=uint8, compu {phys=raw}, range phys 0..255
          signal StatusCPDData4FBD_HR_CIRData69: start 104, 8 bit, little-endian, data-type-policy=OVERRIDE, base-type=uint8, compu {phys=raw}, range phys 0..255
          signal StatusCPDData4FBD_HR_CIRData70: start 112, 8 bit, little-endian, data-type-policy=OVERRIDE, base-type=uint8, compu {phys=raw}, range phys 0..255
          signal StatusCPDData4FBD_HR_CIRData71: start 120, 8 bit, little-endian, data-type-policy=OVERRIDE, base-type=uint8, compu {phys=raw}, range phys 0..255
          signal StatusCPDData4FBD_HR_CIRData72: start 128, 8 bit, little-endian, data-type-policy=OVERRIDE, base-type=uint8, compu {phys=raw}, range phys 0..255
          signal StatusCPDData4FBD_HR_CIRData73: start 136, 8 bit, little-endian, data-type-policy=OVERRIDE, base-type=uint8, compu {phys=raw}, range phys 0..255
          signal StatusCPDData4FBD_HR_CIRData74: start 144, 8 bit, little-endian, data-type-policy=OVERRIDE, base-type=uint8, compu {phys=raw}, range phys 0..255
          signal StatusCPDData4FBD_HR_CIRData75: start 152, 8 bit, little-endian, data-type-policy=OVERRIDE, base-type=uint8, compu {phys=raw}, range phys 0..255
          signal StatusCPDData4FBD_HR_CIRData76: start 160, 8 bit, little-endian, data-type-policy=OVERRIDE, base-type=uint8, compu {phys=raw}, range phys 0..255
          signal StatusCPDData4FBD_HR_CIRData77: start 168, 8 bit, little-endian, data-type-policy=OVERRIDE, base-type=uint8, compu {phys=raw}, range phys 0..255
          signal StatusCPDData4FBD_HR_CIRData78: start 176, 8 bit, little-endian, data-type-policy=OVERRIDE, base-type=uint8, compu {phys=raw}, range phys 0..255
          signal StatusCPDData4FBD_HR_CIRData79: start 184, 8 bit, little-endian, data-type-policy=OVERRIDE, base-type=uint8, compu {phys=raw}, range phys 0..255
          signal StatusCPDData4FBD_HR_CIRData80: start 192, 8 bit, little-endian, data-type-policy=OVERRIDE, base-type=uint8, compu {phys=raw}, range phys 0..255
          signal StatusCPDData4FBD_HR_CIRData81: start 200, 8 bit, little-endian, data-type-policy=OVERRIDE, base-type=uint8, compu {phys=raw}, range phys 0..255
          signal StatusCPDData4FBD_HR_CIRData82: start 208, 8 bit, little-endian, data-type-policy=OVERRIDE, base-type=uint8, compu {phys=raw}, range phys 0..255
          signal StatusCPDData4FBD_HR_CIRData83: start 216, 8 bit, little-endian, data-type-policy=OVERRIDE, base-type=uint8, compu {phys=raw}, range phys 0..255
          signal StatusCPDData4FBD_HR_CIRData84: start 224, 8 bit, little-endian, data-type-policy=OVERRIDE, base-type=uint8, compu {phys=raw}, range phys 0..255
          signal StatusCPDData4FBD_HR_CIRData85: start 232, 8 bit, little-endian, data-type-policy=OVERRIDE, base-type=uint8, compu {phys=raw}, range phys 0..255
          signal StatusCPDData4FBD_HR_CIRData86: start 240, 8 bit, little-endian, data-type-policy=OVERRIDE, base-type=uint8, compu {phys=raw}, range phys 0..255
          signal StatusCPDData4FBD_HR_CIRData87: start 248, 8 bit, little-endian, data-type-policy=OVERRIDE, base-type=uint8, compu {phys=raw}, range phys 0..255
          signal StatusCPDData4FBD_HR_CIRData88: start 256, 8 bit, little-endian, data-type-policy=OVERRIDE, base-type=uint8, compu {phys=raw}, range phys 0..255
          signal StatusCPDData4FBD_HR_CIRData89: start 264, 8 bit, little-endian, data-type-policy=OVERRIDE, base-type=uint8, compu {phys=raw}, range phys 0..255
          signal StatusCPDData4FBD_HR_CIRData90: start 272, 8 bit, little-endian, data-type-policy=OVERRIDE, base-type=uint8, compu {phys=raw}, range phys 0..255
          signal StatusCPDData4FBD_HR_CIRData91: start 280, 8 bit, little-endian, data-type-policy=OVERRIDE, base-type=uint8, compu {phys=raw}, range phys 0..255
          signal StatusCPDData4FBD_HR_CIRData92: start 288, 8 bit, little-endian, data-type-policy=OVERRIDE, base-type=uint8, compu {phys=raw}, range phys 0..255
          signal StatusCPDData4FBD_HR_CIRData93: start 296, 8 bit, little-endian, data-type-policy=OVERRIDE, base-type=uint8, compu {phys=raw}, range phys 0..255
          signal StatusCPDData4FBD_HR_CIRData94: start 304, 8 bit, little-endian, data-type-policy=OVERRIDE, base-type=uint8, compu {phys=raw}, range phys 0..255
          signal StatusCPDData4FBD_HR_CIRData95: start 312, 8 bit, little-endian, data-type-policy=OVERRIDE, base-type=uint8, compu {phys=raw}, range phys 0..255
          signal StatusCPDData4FBD_HR_CIRData96: start 320, 8 bit, little-endian, data-type-policy=OVERRIDE, base-type=uint8, compu {phys=raw}, range phys 0..255
          signal StatusCPDData4FBD_HR_CIRData97: start 328, 8 bit, little-endian, data-type-policy=OVERRIDE, base-type=uint8, compu {phys=raw}, range phys 0..255
          signal StatusCPDData4FBD_HR_CIRData98: start 336, 8 bit, little-endian, data-type-policy=OVERRIDE, base-type=uint8, compu {phys=raw}, range phys 0..255
          signal StatusCPDData4FBD_HR_CIRData99: start 344, 8 bit, little-endian, data-type-policy=OVERRIDE, base-type=uint8, compu {phys=raw}, range phys 0..255
          signal StatusCPDData4FBD_HR_CIRData100: start 352, 8 bit, little-endian, data-type-policy=OVERRIDE, base-type=uint8, compu {phys=raw}, range phys 0..255
          signal StatusCPDData4FBD_HR_CIRData101: start 360, 8 bit, little-endian, data-type-policy=OVERRIDE, base-type=uint8, compu {phys=raw}, range phys 0..255
          signal StatusCPDData4FBD_HR_CIRData102: start 368, 8 bit, little-endian, data-type-policy=OVERRIDE, base-type=uint8, compu {phys=raw}, range phys 0..255
          signal StatusCPDData4FBD_HR_CIRData103: start 376, 8 bit, little-endian, data-type-policy=OVERRIDE, base-type=uint8, compu {phys=raw}, range phys 0..255
          signal StatusCPDData4FBD_HR_CIRData104: start 384, 8 bit, little-endian, data-type-policy=OVERRIDE, base-type=uint8, compu {phys=raw}, range phys 0..255
          signal StatusCPDData4FBD_HR_CIRData105: start 392, 8 bit, little-endian, data-type-policy=OVERRIDE, base-type=uint8, compu {phys=raw}, range phys 0..255
          signal StatusCPDData4FBD_HR_CIRData106: start 400, 8 bit, little-endian, data-type-policy=OVERRIDE, base-type=uint8, compu {phys=raw}, range phys 0..255
          signal StatusCPDData4FBD_HR_CIRData107: start 408, 8 bit, little-endian, data-type-policy=OVERRIDE, base-type=uint8, compu {phys=raw}, range phys 0..255
          signal StatusCPDData4FBD_HR_CIRData108: start 416, 8 bit, little-endian, data-type-policy=OVERRIDE, base-type=uint8, compu {phys=raw}, range phys 0..255
          signal StatusCPDData4FBD_HR_CIRData109: start 424, 8 bit, little-endian, data-type-policy=OVERRIDE, base-type=uint8, compu {phys=raw}, range phys 0..255
          signal StatusCPDData4FBD_HR_CIRData110: start 432, 8 bit, little-endian, data-type-policy=OVERRIDE, base-type=uint8, compu {phys=raw}, range phys 0..255
          signal StatusCPDData4FBD_HR_CIRData111: start 440, 8 bit, little-endian, data-type-policy=OVERRIDE, base-type=uint8, compu {phys=raw}, range phys 0..255
          signal StatusCPDData4FBD_HR_CIRData112: start 448, 8 bit, little-endian, data-type-policy=OVERRIDE, base-type=uint8, compu {phys=raw}, range phys 0..255
          signal StatusCPDData4FBD_HR_CIRData113: start 456, 8 bit, little-endian, data-type-policy=OVERRIDE, base-type=uint8, compu {phys=raw}, range phys 0..255
          signal StatusCPDData4FBD_HR_CIRData114: start 464, 8 bit, little-endian, data-type-policy=OVERRIDE, base-type=uint8, compu {phys=raw}, range phys 0..255
          signal StatusCPDData4FBD_HR_CIRData115: start 472, 8 bit, little-endian, data-type-policy=OVERRIDE, base-type=uint8, compu {phys=raw}, range phys 0..255
          signal StatusCPDData4FBD_HR_CIRData116: start 480, 8 bit, little-endian, data-type-policy=OVERRIDE, base-type=uint8, compu {phys=raw}, range phys 0..255
          signal StatusCPDData4FBD_HR_CIRData117: start 488, 8 bit, little-endian, data-type-policy=OVERRIDE, base-type=uint8, compu {phys=raw}, range phys 0..255
          signal StatusCPDData4FBD_HR_CIRData118: start 496, 8 bit, little-endian, data-type-policy=OVERRIDE, base-type=uint8, compu {phys=raw}, range phys 0..255
          signal StatusCPDData4FBD_HR_CIRData119: start 504, 8 bit, little-endian, data-type-policy=OVERRIDE, base-type=uint8, compu {phys=raw}, range phys 0..255
      frame StatusCPDData4FBD_Miko: id 0x16A, frame-length=64, can-addressing-mode=STANDARD, can-frame-rx-behavior=CAN-FD, can-frame-tx-behavior=CAN-FD
        pdu StatusCPDData4FBD_Miko: length=64, unused-bit-pattern=0
          signal StatusCPDData4FBD_Miko_MsgCounter: start 0, 8 bit, little-endian, data-type-policy=OVERRIDE, base-type=uint8, compu {phys=raw}, range phys 0..252
          signal StatusCPDData4FBD_Miko_LinkID: start 8, 8 bit, little-endian, data-type-policy=OVERRIDE, base-type=uint8, compu {phys=raw}, range phys 0..252
          signal StatusCPDData4FBD_Miko_CollisionCounter: start 16, 8 bit, little-endian, data-type-policy=OVERRIDE, base-type=uint8, compu {phys=raw}, range phys 0..252
          signal StatusCPDData4FBD_Miko_CIRSetting: start 24, 8 bit, little-endian, data-type-policy=OVERRIDE, compu {phys=raw}
          signal StatusCPDData4FBD_Miko_CIRData60: start 32, 8 bit, little-endian, data-type-policy=OVERRIDE, base-type=uint8, compu {phys=raw}, range phys 0..255
          signal StatusCPDData4FBD_Miko_CIRData61: start 40, 8 bit, little-endian, data-type-policy=OVERRIDE, base-type=uint8, compu {phys=raw}, range phys 0..255
          signal StatusCPDData4FBD_Miko_CIRData62: start 48, 8 bit, little-endian, data-type-policy=OVERRIDE, base-type=uint8, compu {phys=raw}, range phys 0..255
          signal StatusCPDData4FBD_Miko_CIRData63: start 56, 8 bit, little-endian, data-type-policy=OVERRIDE, base-type=uint8, compu {phys=raw}, range phys 0..255
          signal StatusCPDData4FBD_Miko_CIRData64: start 64, 8 bit, little-endian, data-type-policy=OVERRIDE, base-type=uint8, compu {phys=raw}, range phys 0..255
          signal StatusCPDData4FBD_Miko_CIRData65: start 72, 8 bit, little-endian, data-type-policy=OVERRIDE, base-type=uint8, compu {phys=raw}, range phys 0..255
          signal StatusCPDData4FBD_Miko_CIRData66: start 80, 8 bit, little-endian, data-type-policy=OVERRIDE, base-type=uint8, compu {phys=raw}, range phys 0..255
          signal StatusCPDData4FBD_Miko_CIRData67: start 88, 8 bit, little-endian, data-type-policy=OVERRIDE, base-type=uint8, compu {phys=raw}, range phys 0..255
          signal StatusCPDData4FBD_Miko_CIRData68: start 96, 8 bit, little-endian, data-type-policy=OVERRIDE, base-type=uint8, compu {phys=raw}, range phys 0..255
          signal StatusCPDData4FBD_Miko_CIRData69: start 104, 8 bit, little-endian, data-type-policy=OVERRIDE, base-type=uint8, compu {phys=raw}, range phys 0..255
          signal StatusCPDData4FBD_Miko_CIRData70: start 112, 8 bit, little-endian, data-type-policy=OVERRIDE, base-type=uint8, compu {phys=raw}, range phys 0..255
          signal StatusCPDData4FBD_Miko_CIRData71: start 120, 8 bit, little-endian, data-type-policy=OVERRIDE, base-type=uint8, compu {phys=raw}, range phys 0..255
          signal StatusCPDData4FBD_Miko_CIRData72: start 128, 8 bit, little-endian, data-type-policy=OVERRIDE, base-type=uint8, compu {phys=raw}, range phys 0..255
          signal StatusCPDData4FBD_Miko_CIRData73: start 136, 8 bit, little-endian, data-type-policy=OVERRIDE, base-type=uint8, compu {phys=raw}, range phys 0..255
          signal StatusCPDData4FBD_Miko_CIRData74: start 144, 8 bit, little-endian, data-type-policy=OVERRIDE, base-type=uint8, compu {phys=raw}, range phys 0..255
          signal StatusCPDData4FBD_Miko_CIRData75: start 152, 8 bit, little-endian, data-type-policy=OVERRIDE, base-type=uint8, compu {phys=raw}, range phys 0..255
          signal StatusCPDData4FBD_Miko_CIRData76: start 160, 8 bit, little-endian, data-type-policy=OVERRIDE, base-type=uint8, compu {phys=raw}, range phys 0..255
          signal StatusCPDData4FBD_Miko_CIRData77: start 168, 8 bit, little-endian, data-type-policy=OVERRIDE, base-type=uint8, compu {phys=raw}, range phys 0..255
          signal StatusCPDData4FBD_Miko_CIRData78: start 176, 8 bit, little-endian, data-type-policy=OVERRIDE, base-type=uint8, compu {phys=raw}, range phys 0..255
          signal StatusCPDData4FBD_Miko_CIRData79: start 184, 8 bit, little-endian, data-type-policy=OVERRIDE, base-type=uint8, compu {phys=raw}, range phys 0..255
          signal StatusCPDData4FBD_Miko_CIRData80: start 192, 8 bit, little-endian, data-type-policy=OVERRIDE, base-type=uint8, compu {phys=raw}, range phys 0..255
          signal StatusCPDData4FBD_Miko_CIRData81: start 200, 8 bit, little-endian, data-type-policy=OVERRIDE, base-type=uint8, compu {phys=raw}, range phys 0..255
          signal StatusCPDData4FBD_Miko_CIRData82: start 208, 8 bit, little-endian, data-type-policy=OVERRIDE, base-type=uint8, compu {phys=raw}, range phys 0..255
          signal StatusCPDData4FBD_Miko_CIRData83: start 216, 8 bit, little-endian, data-type-policy=OVERRIDE, base-type=uint8, compu {phys=raw}, range phys 0..255
          signal StatusCPDData4FBD_Miko_CIRData84: start 224, 8 bit, little-endian, data-type-policy=OVERRIDE, base-type=uint8, compu {phys=raw}, range phys 0..255
          signal StatusCPDData4FBD_Miko_CIRData85: start 232, 8 bit, little-endian, data-type-policy=OVERRIDE, base-type=uint8, compu {phys=raw}, range phys 0..255
          signal StatusCPDData4FBD_Miko_CIRData86: start 240, 8 bit, little-endian, data-type-policy=OVERRIDE, base-type=uint8, compu {phys=raw}, range phys 0..255
          signal StatusCPDData4FBD_Miko_CIRData87: start 248, 8 bit, little-endian, data-type-policy=OVERRIDE, base-type=uint8, compu {phys=raw}, range phys 0..255
          signal StatusCPDData4FBD_Miko_CIRData88: start 256, 8 bit, little-endian, data-type-policy=OVERRIDE, base-type=uint8, compu {phys=raw}, range phys 0..255
          signal StatusCPDData4FBD_Miko_CIRData89: start 264, 8 bit, little-endian, data-type-policy=OVERRIDE, base-type=uint8, compu {phys=raw}, range phys 0..255
          signal StatusCPDData4FBD_Miko_CIRData90: start 272, 8 bit, little-endian, data-type-policy=OVERRIDE, base-type=uint8, compu {phys=raw}, range phys 0..255
          signal StatusCPDData4FBD_Miko_CIRData91: start 280, 8 bit, little-endian, data-type-policy=OVERRIDE, base-type=uint8, compu {phys=raw}, range phys 0..255
          signal StatusCPDData4FBD_Miko_CIRData92: start 288, 8 bit, little-endian, data-type-policy=OVERRIDE, base-type=uint8, compu {phys=raw}, range phys 0..255
          signal StatusCPDData4FBD_Miko_CIRData93: start 296, 8 bit, little-endian, data-type-policy=OVERRIDE, base-type=uint8, compu {phys=raw}, range phys 0..255
          signal StatusCPDData4FBD_Miko_CIRData94: start 304, 8 bit, little-endian, data-type-policy=OVERRIDE, base-type=uint8, compu {phys=raw}, range phys 0..255
          signal StatusCPDData4FBD_Miko_CIRData95: start 312, 8 bit, little-endian, data-type-policy=OVERRIDE, base-type=uint8, compu {phys=raw}, range phys 0..255
          signal StatusCPDData4FBD_Miko_CIRData96: start 320, 8 bit, little-endian, data-type-policy=OVERRIDE, base-type=uint8, compu {phys=raw}, range phys 0..255
          signal StatusCPDData4FBD_Miko_CIRData97: start 328, 8 bit, little-endian, data-type-policy=OVERRIDE, base-type=uint8, compu {phys=raw}, range phys 0..255
          signal StatusCPDData4FBD_Miko_CIRData98: start 336, 8 bit, little-endian, data-type-policy=OVERRIDE, base-type=uint8, compu {phys=raw}, range phys 0..255
          signal StatusCPDData4FBD_Miko_CIRData99: start 344, 8 bit, little-endian, data-type-policy=OVERRIDE, base-type=uint8, compu {phys=raw}, range phys 0..255
          signal StatusCPDData4FBD_Miko_CIRData100: start 352, 8 bit, little-endian, data-type-policy=OVERRIDE, base-type=uint8, compu {phys=raw}, range phys 0..255
          signal StatusCPDData4FBD_Miko_CIRData101: start 360, 8 bit, little-endian, data-type-policy=OVERRIDE, base-type=uint8, compu {phys=raw}, range phys 0..255
          signal StatusCPDData4FBD_Miko_CIRData102: start 368, 8 bit, little-endian, data-type-policy=OVERRIDE, base-type=uint8, compu {phys=raw}, range phys 0..255
          signal StatusCPDData4FBD_Miko_CIRData103: start 376, 8 bit, little-endian, data-type-policy=OVERRIDE, base-type=uint8, compu {phys=raw}, range phys 0..255
          signal StatusCPDData4FBD_Miko_CIRData104: start 384, 8 bit, little-endian, data-type-policy=OVERRIDE, base-type=uint8, compu {phys=raw}, range phys 0..255
          signal StatusCPDData4FBD_Miko_CIRData105: start 392, 8 bit, little-endian, data-type-policy=OVERRIDE, base-type=uint8, compu {phys=raw}, range phys 0..255
          signal StatusCPDData4FBD_Miko_CIRData106: start 400, 8 bit, little-endian, data-type-policy=OVERRIDE, base-type=uint8, compu {phys=raw}, range phys 0..255
          signal StatusCPDData4FBD_Miko_CIRData107: start 408, 8 bit, little-endian, data-type-policy=OVERRIDE, base-type=uint8, compu {phys=raw}, range phys 0..255
          signal StatusCPDData4FBD_Miko_CIRData108: start 416, 8 bit, little-endian, data-type-policy=OVERRIDE, base-type=uint8, compu {phys=raw}, range phys 0..255
          signal StatusCPDData4FBD_Miko_CIRData109: start 424, 8 bit, little-endian, data-type-policy=OVERRIDE, base-type=uint8, compu {phys=raw}, range phys 0..255
          signal StatusCPDData4FBD_Miko_CIRData110: start 432, 8 bit, little-endian, data-type-policy=OVERRIDE, base-type=uint8, compu {phys=raw}, range phys 0..255
          signal StatusCPDData4FBD_Miko_CIRData111: start 440, 8 bit, little-endian, data-type-policy=OVERRIDE, base-type=uint8, compu {phys=raw}, range phys 0..255
          signal StatusCPDData4FBD_Miko_CIRData112: start 448, 8 bit, little-endian, data-type-policy=OVERRIDE, base-type=uint8, compu {phys=raw}, range phys 0..255
          signal StatusCPDData4FBD_Miko_CIRData113: start 456, 8 bit, little-endian, data-type-policy=OVERRIDE, base-type=uint8, compu {phys=raw}, range phys 0..255
          signal StatusCPDData4FBD_Miko_CIRData114: start 464, 8 bit, little-endian, data-type-policy=OVERRIDE, base-type=uint8, compu {phys=raw}, range phys 0..255
          signal StatusCPDData4FBD_Miko_CIRData115: start 472, 8 bit, little-endian, data-type-policy=OVERRIDE, base-type=uint8, compu {phys=raw}, range phys 0..255
          signal StatusCPDData4FBD_Miko_CIRData116: start 480, 8 bit, little-endian, data-type-policy=OVERRIDE, base-type=uint8, compu {phys=raw}, range phys 0..255
          signal StatusCPDData4FBD_Miko_CIRData117: start 488, 8 bit, little-endian, data-type-policy=OVERRIDE, base-type=uint8, compu {phys=raw}, range phys 0..255
          signal StatusCPDData4FBD_Miko_CIRData118: start 496, 8 bit, little-endian, data-type-policy=OVERRIDE, base-type=uint8, compu {phys=raw}, range phys 0..255
          signal StatusCPDData4FBD_Miko_CIRData119: start 504, 8 bit, little-endian, data-type-policy=OVERRIDE, base-type=uint8, compu {phys=raw}, range phys 0..255
      frame StatusCPDData4FBD_MM: id 0x344, frame-length=64, can-addressing-mode=STANDARD, can-frame-rx-behavior=CAN-FD, can-frame-tx-behavior=CAN-FD
        pdu StatusCPDData4FBD_MM: length=64, unused-bit-pattern=0
          signal StatusCPDData4FBD_MM_MsgCounter: start 0, 8 bit, little-endian, data-type-policy=OVERRIDE, base-type=uint8, compu {phys=raw}, range phys 0..252
          signal StatusCPDData4FBD_MM_LinkID: start 8, 8 bit, little-endian, data-type-policy=OVERRIDE, base-type=uint8, compu {phys=raw}, range phys 0..252
          signal StatusCPDData4FBD_MM_CollisionCounter: start 16, 8 bit, little-endian, data-type-policy=OVERRIDE, base-type=uint8, compu {phys=raw}, range phys 0..252
          signal StatusCPDData4FBD_MM_CIRSetting: start 24, 8 bit, little-endian, data-type-policy=OVERRIDE, compu {phys=raw}
          signal StatusCPDData4FBD_MM_CIRData60: start 32, 8 bit, little-endian, data-type-policy=OVERRIDE, base-type=uint8, compu {phys=raw}, range phys 0..255
          signal StatusCPDData4FBD_MM_CIRData61: start 40, 8 bit, little-endian, data-type-policy=OVERRIDE, base-type=uint8, compu {phys=raw}, range phys 0..255
          signal StatusCPDData4FBD_MM_CIRData62: start 48, 8 bit, little-endian, data-type-policy=OVERRIDE, base-type=uint8, compu {phys=raw}, range phys 0..255
          signal StatusCPDData4FBD_MM_CIRData63: start 56, 8 bit, little-endian, data-type-policy=OVERRIDE, base-type=uint8, compu {phys=raw}, range phys 0..255
          signal StatusCPDData4FBD_MM_CIRData64: start 64, 8 bit, little-endian, data-type-policy=OVERRIDE, base-type=uint8, compu {phys=raw}, range phys 0..255
          signal StatusCPDData4FBD_MM_CIRData65: start 72, 8 bit, little-endian, data-type-policy=OVERRIDE, base-type=uint8, compu {phys=raw}, range phys 0..255
          signal StatusCPDData4FBD_MM_CIRData66: start 80, 8 bit, little-endian, data-type-policy=OVERRIDE, base-type=uint8, compu {phys=raw}, range phys 0..255
          signal StatusCPDData4FBD_MM_CIRData67: start 88, 8 bit, little-endian, data-type-policy=OVERRIDE, base-type=uint8, compu {phys=raw}, range phys 0..255
          signal StatusCPDData4FBD_MM_CIRData68: start 96, 8 bit, little-endian, data-type-policy=OVERRIDE, base-type=uint8, compu {phys=raw}, range phys 0..255
          signal StatusCPDData4FBD_MM_CIRData69: start 104, 8 bit, little-endian, data-type-policy=OVERRIDE, base-type=uint8, compu {phys=raw}, range phys 0..255
          signal StatusCPDData4FBD_MM_CIRData70: start 112, 8 bit, little-endian, data-type-policy=OVERRIDE, base-type=uint8, compu {phys=raw}, range phys 0..255
          signal StatusCPDData4FBD_MM_CIRData71: start 120, 8 bit, little-endian, data-type-policy=OVERRIDE, base-type=uint8, compu {phys=raw}, range phys 0..255
          signal StatusCPDData4FBD_MM_CIRData72: start 128, 8 bit, little-endian, data-type-policy=OVERRIDE, base-type=uint8, compu {phys=raw}, range phys 0..255
          signal StatusCPDData4FBD_MM_CIRData73: start 136, 8 bit, little-endian, data-type-policy=OVERRIDE, base-type=uint8, compu {phys=raw}, range phys 0..255
          signal StatusCPDData4FBD_MM_CIRData74: start 144, 8 bit, little-endian, data-type-policy=OVERRIDE, base-type=uint8, compu {phys=raw}, range phys 0..255
          signal StatusCPDData4FBD_MM_CIRData75: start 152, 8 bit, little-endian, data-type-policy=OVERRIDE, base-type=uint8, compu {phys=raw}, range phys 0..255
          signal StatusCPDData4FBD_MM_CIRData76: start 160, 8 bit, little-endian, data-type-policy=OVERRIDE, base-type=uint8, compu {phys=raw}, range phys 0..255
          signal StatusCPDData4FBD_MM_CIRData77: start 168, 8 bit, little-endian, data-type-policy=OVERRIDE, base-type=uint8, compu {phys=raw}, range phys 0..255
          signal StatusCPDData4FBD_MM_CIRData78: start 176, 8 bit, little-endian, data-type-policy=OVERRIDE, base-type=uint8, compu {phys=raw}, range phys 0..255
          signal StatusCPDData4FBD_MM_CIRData79: start 184, 8 bit, little-endian, data-type-policy=OVERRIDE, base-type=uint8, compu {phys=raw}, range phys 0..255
          signal StatusCPDData4FBD_MM_CIRData80: start 192, 8 bit, little-endian, data-type-policy=OVERRIDE, base-type=uint8, compu {phys=raw}, range phys 0..255
          signal StatusCPDData4FBD_MM_CIRData81: start 200, 8 bit, little-endian, data-type-policy=OVERRIDE, base-type=uint8, compu {phys=raw}, range phys 0..255
          signal StatusCPDData4FBD_MM_CIRData82: start 208, 8 bit, little-endian, data-type-policy=OVERRIDE, base-type=uint8, compu {phys=raw}, range phys 0..255
          signal StatusCPDData4FBD_MM_CIRData83: start 216, 8 bit, little-endian, data-type-policy=OVERRIDE, base-type=uint8, compu {phys=raw}, range phys 0..255
          signal StatusCPDData4FBD_MM_CIRData84: start 224, 8 bit, little-endian, data-type-policy=OVERRIDE, base-type=uint8, compu {phys=raw}, range phys 0..255
          signal StatusCPDData4FBD_MM_CIRData85: start 232, 8 bit, little-endian, data-type-policy=OVERRIDE, base-type=uint8, compu {phys=raw}, range phys 0..255
          signal StatusCPDData4FBD_MM_CIRData86: start 240, 8 bit, little-endian, data-type-policy=OVERRIDE, base-type=uint8, compu {phys=raw}, range phys 0..255
          signal StatusCPDData4FBD_MM_CIRData87: start 248, 8 bit, little-endian, data-type-policy=OVERRIDE, base-type=uint8, compu {phys=raw}, range phys 0..255
          signal StatusCPDData4FBD_MM_CIRData88: start 256, 8 bit, little-endian, data-type-policy=OVERRIDE, base-type=uint8, compu {phys=raw}, range phys 0..255
          signal StatusCPDData4FBD_MM_CIRData89: start 264, 8 bit, little-endian, data-type-policy=OVERRIDE, base-type=uint8, compu {phys=raw}, range phys 0..255
          signal StatusCPDData4FBD_MM_CIRData90: start 272, 8 bit, little-endian, data-type-policy=OVERRIDE, base-type=uint8, compu {phys=raw}, range phys 0..255
          signal StatusCPDData4FBD_MM_CIRData91: start 280, 8 bit, little-endian, data-type-policy=OVERRIDE, base-type=uint8, compu {phys=raw}, range phys 0..255
          signal StatusCPDData4FBD_MM_CIRData92: start 288, 8 bit, little-endian, data-type-policy=OVERRIDE, base-type=uint8, compu {phys=raw}, range phys 0..255
          signal StatusCPDData4FBD_MM_CIRData93: start 296, 8 bit, little-endian, data-type-policy=OVERRIDE, base-type=uint8, compu {phys=raw}, range phys 0..255
          signal StatusCPDData4FBD_MM_CIRData94: start 304, 8 bit, little-endian, data-type-policy=OVERRIDE, base-type=uint8, compu {phys=raw}, range phys 0..255
          signal StatusCPDData4FBD_MM_CIRData95: start 312, 8 bit, little-endian, data-type-policy=OVERRIDE, base-type=uint8, compu {phys=raw}, range phys 0..255
          signal StatusCPDData4FBD_MM_CIRData96: start 320, 8 bit, little-endian, data-type-policy=OVERRIDE, base-type=uint8, compu {phys=raw}, range phys 0..255
          signal StatusCPDData4FBD_MM_CIRData97: start 328, 8 bit, little-endian, data-type-policy=OVERRIDE, base-type=uint8, compu {phys=raw}, range phys 0..255
          signal StatusCPDData4FBD_MM_CIRData98: start 336, 8 bit, little-endian, data-type-policy=OVERRIDE, base-type=uint8, compu {phys=raw}, range phys 0..255
          signal StatusCPDData4FBD_MM_CIRData99: start 344, 8 bit, little-endian, data-type-policy=OVERRIDE, base-type=uint8, compu {phys=raw}, range phys 0..255
          signal StatusCPDData4FBD_MM_CIRData100: start 352, 8 bit, little-endian, data-type-policy=OVERRIDE, base-type=uint8, compu {phys=raw}, range phys 0..255
          signal StatusCPDData4FBD_MM_CIRData101: start 360, 8 bit, little-endian, data-type-policy=OVERRIDE, base-type=uint8, compu {phys=raw}, range phys 0..255
          signal StatusCPDData4FBD_MM_CIRData102: start 368, 8 bit, little-endian, data-type-policy=OVERRIDE, base-type=uint8, compu {phys=raw}, range phys 0..255
          signal StatusCPDData4FBD_MM_CIRData103: start 376, 8 bit, little-endian, data-type-policy=OVERRIDE, base-type=uint8, compu {phys=raw}, range phys 0..255
          signal StatusCPDData4FBD_MM_CIRData104: start 384, 8 bit, little-endian, data-type-policy=OVERRIDE, base-type=uint8, compu {phys=raw}, range phys 0..255
          signal StatusCPDData4FBD_MM_CIRData105: start 392, 8 bit, little-endian, data-type-policy=OVERRIDE, base-type=uint8, compu {phys=raw}, range phys 0..255
          signal StatusCPDData4FBD_MM_CIRData106: start 400, 8 bit, little-endian, data-type-policy=OVERRIDE, base-type=uint8, compu {phys=raw}, range phys 0..255
          signal StatusCPDData4FBD_MM_CIRData107: start 408, 8 bit, little-endian, data-type-policy=OVERRIDE, base-type=uint8, compu {phys=raw}, range phys 0..255
          signal StatusCPDData4FBD_MM_CIRData108: start 416, 8 bit, little-endian, data-type-policy=OVERRIDE, base-type=uint8, compu {phys=raw}, range phys 0..255
          signal StatusCPDData4FBD_MM_CIRData109: start 424, 8 bit, little-endian, data-type-policy=OVERRIDE, base-type=uint8, compu {phys=raw}, range phys 0..255
          signal StatusCPDData4FBD_MM_CIRData110: start 432, 8 bit, little-endian, data-type-policy=OVERRIDE, base-type=uint8, compu {phys=raw}, range phys 0..255
          signal StatusCPDData4FBD_MM_CIRData111: start 440, 8 bit, little-endian, data-type-policy=OVERRIDE, base-type=uint8, compu {phys=raw}, range phys 0..255
          signal StatusCPDData4FBD_MM_CIRData112: start 448, 8 bit, little-endian, data-type-policy=OVERRIDE, base-type=uint8, compu {phys=raw}, range phys 0..255
          signal StatusCPDData4FBD_MM_CIRData113: start 456, 8 bit, little-endian, data-type-policy=OVERRIDE, base-type=uint8, compu {phys=raw}, range phys 0..255
          signal StatusCPDData4FBD_MM_CIRData114: start 464, 8 bit, little-endian, data-type-policy=OVERRIDE, base-type=uint8, compu {phys=raw}, range phys 0..255
          signal StatusCPDData4FBD_MM_CIRData115: start 472, 8 bit, little-endian, data-type-policy=OVERRIDE, base-type=uint8, compu {phys=raw}, range phys 0..255
          signal StatusCPDData4FBD_MM_CIRData116: start 480, 8 bit, little-endian, data-type-policy=OVERRIDE, base-type=uint8, compu {phys=raw}, range phys 0..255
          signal StatusCPDData4FBD_MM_CIRData117: start 488, 8 bit, little-endian, data-type-policy=OVERRIDE, base-type=uint8, compu {phys=raw}, range phys 0..255
          signal StatusCPDData4FBD_MM_CIRData118: start 496, 8 bit, little-endian, data-type-policy=OVERRIDE, base-type=uint8, compu {phys=raw}, range phys 0..255
          signal StatusCPDData4FBD_MM_CIRData119: start 504, 8 bit, little-endian, data-type-policy=OVERRIDE, base-type=uint8, compu {phys=raw}, range phys 0..255
      frame StatusCPDData4FBD_Trunk: id 0x16B, frame-length=64, can-addressing-mode=STANDARD, can-frame-rx-behavior=CAN-FD, can-frame-tx-behavior=CAN-FD
        pdu StatusCPDData4FBD_Trunk: length=64, unused-bit-pattern=0
          signal StatusCPDData4FBD_Trunk_MsgCounter: start 0, 8 bit, little-endian, data-type-policy=OVERRIDE, base-type=uint8, compu {phys=raw}, range phys 0..252
          signal StatusCPDData4FBD_Trunk_LinkID: start 8, 8 bit, little-endian, data-type-policy=OVERRIDE, base-type=uint8, compu {phys=raw}, range phys 0..252
          signal StatusCPDData4FBD_Trunk_CollisionCounter: start 16, 8 bit, little-endian, data-type-policy=OVERRIDE, base-type=uint8, compu {phys=raw}, range phys 0..252
          signal StatusCPDData4FBD_Trunk_CIRSetting: start 24, 8 bit, little-endian, data-type-policy=OVERRIDE, compu {phys=raw}
          signal StatusCPDData4FBD_Trunk_CIRData60: start 32, 8 bit, little-endian, data-type-policy=OVERRIDE, base-type=uint8, compu {phys=raw}, range phys 0..255
          signal StatusCPDData4FBD_Trunk_CIRData61: start 40, 8 bit, little-endian, data-type-policy=OVERRIDE, base-type=uint8, compu {phys=raw}, range phys 0..255
          signal StatusCPDData4FBD_Trunk_CIRData62: start 48, 8 bit, little-endian, data-type-policy=OVERRIDE, base-type=uint8, compu {phys=raw}, range phys 0..255
          signal StatusCPDData4FBD_Trunk_CIRData63: start 56, 8 bit, little-endian, data-type-policy=OVERRIDE, base-type=uint8, compu {phys=raw}, range phys 0..255
          signal StatusCPDData4FBD_Trunk_CIRData64: start 64, 8 bit, little-endian, data-type-policy=OVERRIDE, base-type=uint8, compu {phys=raw}, range phys 0..255
          signal StatusCPDData4FBD_Trunk_CIRData65: start 72, 8 bit, little-endian, data-type-policy=OVERRIDE, base-type=uint8, compu {phys=raw}, range phys 0..255
          signal StatusCPDData4FBD_Trunk_CIRData66: start 80, 8 bit, little-endian, data-type-policy=OVERRIDE, base-type=uint8, compu {phys=raw}, range phys 0..255
          signal StatusCPDData4FBD_Trunk_CIRData67: start 88, 8 bit, little-endian, data-type-policy=OVERRIDE, base-type=uint8, compu {phys=raw}, range phys 0..255
          signal StatusCPDData4FBD_Trunk_CIRData68: start 96, 8 bit, little-endian, data-type-policy=OVERRIDE, base-type=uint8, compu {phys=raw}, range phys 0..255
          signal StatusCPDData4FBD_Trunk_CIRData69: start 104, 8 bit, little-endian, data-type-policy=OVERRIDE, base-type=uint8, compu {phys=raw}, range phys 0..255
          signal StatusCPDData4FBD_Trunk_CIRData70: start 112, 8 bit, little-endian, data-type-policy=OVERRIDE, base-type=uint8, compu {phys=raw}, range phys 0..255
          signal StatusCPDData4FBD_Trunk_CIRData71: start 120, 8 bit, little-endian, data-type-policy=OVERRIDE, base-type=uint8, compu {phys=raw}, range phys 0..255
          signal StatusCPDData4FBD_Trunk_CIRData72: start 128, 8 bit, little-endian, data-type-policy=OVERRIDE, base-type=uint8, compu {phys=raw}, range phys 0..255
          signal StatusCPDData4FBD_Trunk_CIRData73: start 136, 8 bit, little-endian, data-type-policy=OVERRIDE, base-type=uint8, compu {phys=raw}, range phys 0..255
          signal StatusCPDData4FBD_Trunk_CIRData74: start 144, 8 bit, little-endian, data-type-policy=OVERRIDE, base-type=uint8, compu {phys=raw}, range phys 0..255
          signal StatusCPDData4FBD_Trunk_CIRData75: start 152, 8 bit, little-endian, data-type-policy=OVERRIDE, base-type=uint8, compu {phys=raw}, range phys 0..255
          signal StatusCPDData4FBD_Trunk_CIRData76: start 160, 8 bit, little-endian, data-type-policy=OVERRIDE, base-type=uint8, compu {phys=raw}, range phys 0..255
          signal StatusCPDData4FBD_Trunk_CIRData77: start 168, 8 bit, little-endian, data-type-policy=OVERRIDE, base-type=uint8, compu {phys=raw}, range phys 0..255
          signal StatusCPDData4FBD_Trunk_CIRData78: start 176, 8 bit, little-endian, data-type-policy=OVERRIDE, base-type=uint8, compu {phys=raw}, range phys 0..255
          signal StatusCPDData4FBD_Trunk_CIRData79: start 184, 8 bit, little-endian, data-type-policy=OVERRIDE, base-type=uint8, compu {phys=raw}, range phys 0..255
          signal StatusCPDData4FBD_Trunk_CIRData80: start 192, 8 bit, little-endian, data-type-policy=OVERRIDE, base-type=uint8, compu {phys=raw}, range phys 0..255
          signal StatusCPDData4FBD_Trunk_CIRData81: start 200, 8 bit, little-endian, data-type-policy=OVERRIDE, base-type=uint8, compu {phys=raw}, range phys 0..255
          signal StatusCPDData4FBD_Trunk_CIRData82: start 208, 8 bit, little-endian, data-type-policy=OVERRIDE, base-type=uint8, compu {phys=raw}, range phys 0..255
          signal StatusCPDData4FBD_Trunk_CIRData83: start 216, 8 bit, little-endian, data-type-policy=OVERRIDE, base-type=uint8, compu {phys=raw}, range phys 0..255
          signal StatusCPDData4FBD_Trunk_CIRData84: start 224, 8 bit, little-endian, data-type-policy=OVERRIDE, base-type=uint8, compu {phys=raw}, range phys 0..255
          signal StatusCPDData4FBD_Trunk_CIRData85: start 232, 8 bit, little-endian, data-type-policy=OVERRIDE, base-type=uint8, compu {phys=raw}, range phys 0..255
          signal StatusCPDData4FBD_Trunk_CIRData86: start 240, 8 bit, little-endian, data-type-policy=OVERRIDE, base-type=uint8, compu {phys=raw}, range phys 0..255
          signal StatusCPDData4FBD_Trunk_CIRData87: start 248, 8 bit, little-endian, data-type-policy=OVERRIDE, base-type=uint8, compu {phys=raw}, range phys 0..255
          signal StatusCPDData4FBD_Trunk_CIRData88: start 256, 8 bit, little-endian, data-type-policy=OVERRIDE, base-type=uint8, compu {phys=raw}, range phys 0..255
          signal StatusCPDData4FBD_Trunk_CIRData89: start 264, 8 bit, little-endian, data-type-policy=OVERRIDE, base-type=uint8, compu {phys=raw}, range phys 0..255
          signal StatusCPDData4FBD_Trunk_CIRData90: start 272, 8 bit, little-endian, data-type-policy=OVERRIDE, base-type=uint8, compu {phys=raw}, range phys 0..255
          signal StatusCPDData4FBD_Trunk_CIRData91: start 280, 8 bit, little-endian, data-type-policy=OVERRIDE, base-type=uint8, compu {phys=raw}, range phys 0..255
          signal StatusCPDData4FBD_Trunk_CIRData92: start 288, 8 bit, little-endian, data-type-policy=OVERRIDE, base-type=uint8, compu {phys=raw}, range phys 0..255
          signal StatusCPDData4FBD_Trunk_CIRData93: start 296, 8 bit, little-endian, data-type-policy=OVERRIDE, base-type=uint8, compu {phys=raw}, range phys 0..255
          signal StatusCPDData4FBD_Trunk_CIRData94: start 304, 8 bit, little-endian, data-type-policy=OVERRIDE, base-type=uint8, compu {phys=raw}, range phys 0..255
          signal StatusCPDData4FBD_Trunk_CIRData95: start 312, 8 bit, little-endian, data-type-policy=OVERRIDE, base-type=uint8, compu {phys=raw}, range phys 0..255
          signal StatusCPDData4FBD_Trunk_CIRData96: start 320, 8 bit, little-endian, data-type-policy=OVERRIDE, base-type=uint8, compu {phys=raw}, range phys 0..255
          signal StatusCPDData4FBD_Trunk_CIRData97: start 328, 8 bit, little-endian, data-type-policy=OVERRIDE, base-type=uint8, compu {phys=raw}, range phys 0..255
          signal StatusCPDData4FBD_Trunk_CIRData98: start 336, 8 bit, little-endian, data-type-policy=OVERRIDE, base-type=uint8, compu {phys=raw}, range phys 0..255
          signal StatusCPDData4FBD_Trunk_CIRData99: start 344, 8 bit, little-endian, data-type-policy=OVERRIDE, base-type=uint8, compu {phys=raw}, range phys 0..255
          signal StatusCPDData4FBD_Trunk_CIRData100: start 352, 8 bit, little-endian, data-type-policy=OVERRIDE, base-type=uint8, compu {phys=raw}, range phys 0..255
          signal StatusCPDData4FBD_Trunk_CIRData101: start 360, 8 bit, little-endian, data-type-policy=OVERRIDE, base-type=uint8, compu {phys=raw}, range phys 0..255
          signal StatusCPDData4FBD_Trunk_CIRData102: start 368, 8 bit, little-endian, data-type-policy=OVERRIDE, base-type=uint8, compu {phys=raw}, range phys 0..255
          signal StatusCPDData4FBD_Trunk_CIRData103: start 376, 8 bit, little-endian, data-type-policy=OVERRIDE, base-type=uint8, compu {phys=raw}, range phys 0..255
          signal StatusCPDData4FBD_Trunk_CIRData104: start 384, 8 bit, little-endian, data-type-policy=OVERRIDE, base-type=uint8, compu {phys=raw}, range phys 0..255
          signal StatusCPDData4FBD_Trunk_CIRData105: start 392, 8 bit, little-endian, data-type-policy=OVERRIDE, base-type=uint8, compu {phys=raw}, range phys 0..255
          signal StatusCPDData4FBD_Trunk_CIRData106: start 400, 8 bit, little-endian, data-type-policy=OVERRIDE, base-type=uint8, compu {phys=raw}, range phys 0..255
          signal StatusCPDData4FBD_Trunk_CIRData107: start 408, 8 bit, little-endian, data-type-policy=OVERRIDE, base-type=uint8, compu {phys=raw}, range phys 0..255
          signal StatusCPDData4FBD_Trunk_CIRData108: start 416, 8 bit, little-endian, data-type-policy=OVERRIDE, base-type=uint8, compu {phys=raw}, range phys 0..255
          signal StatusCPDData4FBD_Trunk_CIRData109: start 424, 8 bit, little-endian, data-type-policy=OVERRIDE, base-type=uint8, compu {phys=raw}, range phys 0..255
          signal StatusCPDData4FBD_Trunk_CIRData110: start 432, 8 bit, little-endian, data-type-policy=OVERRIDE, base-type=uint8, compu {phys=raw}, range phys 0..255
          signal StatusCPDData4FBD_Trunk_CIRData111: start 440, 8 bit, little-endian, data-type-policy=OVERRIDE, base-type=uint8, compu {phys=raw}, range phys 0..255
          signal StatusCPDData4FBD_Trunk_CIRData112: start 448, 8 bit, little-endian, data-type-policy=OVERRIDE, base-type=uint8, compu {phys=raw}, range phys 0..255
          signal StatusCPDData4FBD_Trunk_CIRData113: start 456, 8 bit, little-endian, data-type-policy=OVERRIDE, base-type=uint8, compu {phys=raw}, range phys 0..255
          signal StatusCPDData4FBD_Trunk_CIRData114: start 464, 8 bit, little-endian, data-type-policy=OVERRIDE, base-type=uint8, compu {phys=raw}, range phys 0..255
          signal StatusCPDData4FBD_Trunk_CIRData115: start 472, 8 bit, little-endian, data-type-policy=OVERRIDE, base-type=uint8, compu {phys=raw}, range phys 0..255
          signal StatusCPDData4FBD_Trunk_CIRData116: start 480, 8 bit, little-endian, data-type-policy=OVERRIDE, base-type=uint8, compu {phys=raw}, range phys 0..255
          signal StatusCPDData4FBD_Trunk_CIRData117: start 488, 8 bit, little-endian, data-type-policy=OVERRIDE, base-type=uint8, compu {phys=raw}, range phys 0..255
          signal StatusCPDData4FBD_Trunk_CIRData118: start 496, 8 bit, little-endian, data-type-policy=OVERRIDE, base-type=uint8, compu {phys=raw}, range phys 0..255
          signal StatusCPDData4FBD_Trunk_CIRData119: start 504, 8 bit, little-endian, data-type-policy=OVERRIDE, base-type=uint8, compu {phys=raw}, range phys 0..255
      frame StatusCPDData4FBD_VL: id 0x16C, frame-length=64, can-addressing-mode=STANDARD, can-frame-rx-behavior=CAN-FD, can-frame-tx-behavior=CAN-FD
        pdu StatusCPDData4FBD_VL: length=64, unused-bit-pattern=0
          signal StatusCPDData4FBD_VL_MsgCounter: start 0, 8 bit, little-endian, data-type-policy=OVERRIDE, base-type=uint8, compu {phys=raw}, range phys 0..252
          signal StatusCPDData4FBD_VL_LinkID: start 8, 8 bit, little-endian, data-type-policy=OVERRIDE, base-type=uint8, compu {phys=raw}, range phys 0..252
          signal StatusCPDData4FBD_VL_CollisionCounter: start 16, 8 bit, little-endian, data-type-policy=OVERRIDE, base-type=uint8, compu {phys=raw}, range phys 0..252
          signal StatusCPDData4FBD_VL_CIRSetting: start 24, 8 bit, little-endian, data-type-policy=OVERRIDE, compu {phys=raw}
          signal StatusCPDData4FBD_VL_CIRData60: start 32, 8 bit, little-endian, data-type-policy=OVERRIDE, base-type=uint8, compu {phys=raw}, range phys 0..255
          signal StatusCPDData4FBD_VL_CIRData61: start 40, 8 bit, little-endian, data-type-policy=OVERRIDE, base-type=uint8, compu {phys=raw}, range phys 0..255
          signal StatusCPDData4FBD_VL_CIRData62: start 48, 8 bit, little-endian, data-type-policy=OVERRIDE, base-type=uint8, compu {phys=raw}, range phys 0..255
          signal StatusCPDData4FBD_VL_CIRData63: start 56, 8 bit, little-endian, data-type-policy=OVERRIDE, base-type=uint8, compu {phys=raw}, range phys 0..255
          signal StatusCPDData4FBD_VL_CIRData64: start 64, 8 bit, little-endian, data-type-policy=OVERRIDE, base-type=uint8, compu {phys=raw}, range phys 0..255
          signal StatusCPDData4FBD_VL_CIRData65: start 72, 8 bit, little-endian, data-type-policy=OVERRIDE, base-type=uint8, compu {phys=raw}, range phys 0..255
          signal StatusCPDData4FBD_VL_CIRData66: start 80, 8 bit, little-endian, data-type-policy=OVERRIDE, base-type=uint8, compu {phys=raw}, range phys 0..255
          signal StatusCPDData4FBD_VL_CIRData67: start 88, 8 bit, little-endian, data-type-policy=OVERRIDE, base-type=uint8, compu {phys=raw}, range phys 0..255
          signal StatusCPDData4FBD_VL_CIRData68: start 96, 8 bit, little-endian, data-type-policy=OVERRIDE, base-type=uint8, compu {phys=raw}, range phys 0..255
          signal StatusCPDData4FBD_VL_CIRData69: start 104, 8 bit, little-endian, data-type-policy=OVERRIDE, base-type=uint8, compu {phys=raw}, range phys 0..255
          signal StatusCPDData4FBD_VL_CIRData70: start 112, 8 bit, little-endian, data-type-policy=OVERRIDE, base-type=uint8, compu {phys=raw}, range phys 0..255
          signal StatusCPDData4FBD_VL_CIRData71: start 120, 8 bit, little-endian, data-type-policy=OVERRIDE, base-type=uint8, compu {phys=raw}, range phys 0..255
          signal StatusCPDData4FBD_VL_CIRData72: start 128, 8 bit, little-endian, data-type-policy=OVERRIDE, base-type=uint8, compu {phys=raw}, range phys 0..255
          signal StatusCPDData4FBD_VL_CIRData73: start 136, 8 bit, little-endian, data-type-policy=OVERRIDE, base-type=uint8, compu {phys=raw}, range phys 0..255
          signal StatusCPDData4FBD_VL_CIRData74: start 144, 8 bit, little-endian, data-type-policy=OVERRIDE, base-type=uint8, compu {phys=raw}, range phys 0..255
          signal StatusCPDData4FBD_VL_CIRData75: start 152, 8 bit, little-endian, data-type-policy=OVERRIDE, base-type=uint8, compu {phys=raw}, range phys 0..255
          signal StatusCPDData4FBD_VL_CIRData76: start 160, 8 bit, little-endian, data-type-policy=OVERRIDE, base-type=uint8, compu {phys=raw}, range phys 0..255
          signal StatusCPDData4FBD_VL_CIRData77: start 168, 8 bit, little-endian, data-type-policy=OVERRIDE, base-type=uint8, compu {phys=raw}, range phys 0..255
          signal StatusCPDData4FBD_VL_CIRData78: start 176, 8 bit, little-endian, data-type-policy=OVERRIDE, base-type=uint8, compu {phys=raw}, range phys 0..255
          signal StatusCPDData4FBD_VL_CIRData79: start 184, 8 bit, little-endian, data-type-policy=OVERRIDE, base-type=uint8, compu {phys=raw}, range phys 0..255
          signal StatusCPDData4FBD_VL_CIRData80: start 192, 8 bit, little-endian, data-type-policy=OVERRIDE, base-type=uint8, compu {phys=raw}, range phys 0..255
          signal StatusCPDData4FBD_VL_CIRData81: start 200, 8 bit, little-endian, data-type-policy=OVERRIDE, base-type=uint8, compu {phys=raw}, range phys 0..255
          signal StatusCPDData4FBD_VL_CIRData82: start 208, 8 bit, little-endian, data-type-policy=OVERRIDE, base-type=uint8, compu {phys=raw}, range phys 0..255
          signal StatusCPDData4FBD_VL_CIRData83: start 216, 8 bit, little-endian, data-type-policy=OVERRIDE, base-type=uint8, compu {phys=raw}, range phys 0..255
          signal StatusCPDData4FBD_VL_CIRData84: start 224, 8 bit, little-endian, data-type-policy=OVERRIDE, base-type=uint8, compu {phys=raw}, range phys 0..255
          signal StatusCPDData4FBD_VL_CIRData85: start 232, 8 bit, little-endian, data-type-policy=OVERRIDE, base-type=uint8, compu {phys=raw}, range phys 0..255
          signal StatusCPDData4FBD_VL_CIRData86: start 240, 8 bit, little-endian, data-type-policy=OVERRIDE, base-type=uint8, compu {phys=raw}, range phys 0..255
          signal StatusCPDData4FBD_VL_CIRData87: start 248, 8 bit, little-endian, data-type-policy=OVERRIDE, base-type=uint8, compu {phys=raw}, range phys 0..255
          signal StatusCPDData4FBD_VL_CIRData88: start 256, 8 bit, little-endian, data-type-policy=OVERRIDE, base-type=uint8, compu {phys=raw}, range phys 0..255
          signal StatusCPDData4FBD_VL_CIRData89: start 264, 8 bit, little-endian, data-type-policy=OVERRIDE, base-type=uint8, compu {phys=raw}, range phys 0..255
          signal StatusCPDData4FBD_VL_CIRData90: start 272, 8 bit, little-endian, data-type-policy=OVERRIDE, base-type=uint8, compu {phys=raw}, range phys 0..255
          signal StatusCPDData4FBD_VL_CIRData91: start 280, 8 bit, little-endian, data-type-policy=OVERRIDE, base-type=uint8, compu {phys=raw}, range phys 0..255
          signal StatusCPDData4FBD_VL_CIRData92: start 288, 8 bit, little-endian, data-type-policy=OVERRIDE, base-type=uint8, compu {phys=raw}, range phys 0..255
          signal StatusCPDData4FBD_VL_CIRData93: start 296, 8 bit, little-endian, data-type-policy=OVERRIDE, base-type=uint8, compu {phys=raw}, range phys 0..255
          signal StatusCPDData4FBD_VL_CIRData94: start 304, 8 bit, little-endian, data-type-policy=OVERRIDE, base-type=uint8, compu {phys=raw}, range phys 0..255
          signal StatusCPDData4FBD_VL_CIRData95: start 312, 8 bit, little-endian, data-type-policy=OVERRIDE, base-type=uint8, compu {phys=raw}, range phys 0..255
          signal StatusCPDData4FBD_VL_CIRData96: start 320, 8 bit, little-endian, data-type-policy=OVERRIDE, base-type=uint8, compu {phys=raw}, range phys 0..255
          signal StatusCPDData4FBD_VL_CIRData97: start 328, 8 bit, little-endian, data-type-policy=OVERRIDE, base-type=uint8, compu {phys=raw}, range phys 0..255
          signal StatusCPDData4FBD_VL_CIRData98: start 336, 8 bit, little-endian, data-type-policy=OVERRIDE, base-type=uint8, compu {phys=raw}, range phys 0..255
          signal StatusCPDData4FBD_VL_CIRData99: start 344, 8 bit, little-endian, data-type-policy=OVERRIDE, base-type=uint8, compu {phys=raw}, range phys 0..255
          signal StatusCPDData4FBD_VL_CIRData100: start 352, 8 bit, little-endian, data-type-policy=OVERRIDE, base-type=uint8, compu {phys=raw}, range phys 0..255
          signal StatusCPDData4FBD_VL_CIRData101: start 360, 8 bit, little-endian, data-type-policy=OVERRIDE, base-type=uint8, compu {phys=raw}, range phys 0..255
          signal StatusCPDData4FBD_VL_CIRData102: start 368, 8 bit, little-endian, data-type-policy=OVERRIDE, base-type=uint8, compu {phys=raw}, range phys 0..255
          signal StatusCPDData4FBD_VL_CIRData103: start 376, 8 bit, little-endian, data-type-policy=OVERRIDE, base-type=uint8, compu {phys=raw}, range phys 0..255
          signal StatusCPDData4FBD_VL_CIRData104: start 384, 8 bit, little-endian, data-type-policy=OVERRIDE, base-type=uint8, compu {phys=raw}, range phys 0..255
          signal StatusCPDData4FBD_VL_CIRData105: start 392, 8 bit, little-endian, data-type-policy=OVERRIDE, base-type=uint8, compu {phys=raw}, range phys 0..255
          signal StatusCPDData4FBD_VL_CIRData106: start 400, 8 bit, little-endian, data-type-policy=OVERRIDE, base-type=uint8, compu {phys=raw}, range phys 0..255
          signal StatusCPDData4FBD_VL_CIRData107: start 408, 8 bit, little-endian, data-type-policy=OVERRIDE, base-type=uint8, compu {phys=raw}, range phys 0..255
          signal StatusCPDData4FBD_VL_CIRData108: start 416, 8 bit, little-endian, data-type-policy=OVERRIDE, base-type=uint8, compu {phys=raw}, range phys 0..255
          signal StatusCPDData4FBD_VL_CIRData109: start 424, 8 bit, little-endian, data-type-policy=OVERRIDE, base-type=uint8, compu {phys=raw}, range phys 0..255
          signal StatusCPDData4FBD_VL_CIRData110: start 432, 8 bit, little-endian, data-type-policy=OVERRIDE, base-type=uint8, compu {phys=raw}, range phys 0..255
          signal StatusCPDData4FBD_VL_CIRData111: start 440, 8 bit, little-endian, data-type-policy=OVERRIDE, base-type=uint8, compu {phys=raw}, range phys 0..255
          signal StatusCPDData4FBD_VL_CIRData112: start 448, 8 bit, little-endian, data-type-policy=OVERRIDE, base-type=uint8, compu {phys=raw}, range phys 0..255
          signal StatusCPDData4FBD_VL_CIRData113: start 456, 8 bit, little-endian, data-type-policy=OVERRIDE, base-type=uint8, compu {phys=raw}, range phys 0..255
          signal StatusCPDData4FBD_VL_CIRData114: start 464, 8 bit, little-endian, data-type-policy=OVERRIDE, base-type=uint8, compu {phys=raw}, range phys 0..255
          signal StatusCPDData4FBD_VL_CIRData115: start 472, 8 bit, little-endian, data-type-policy=OVERRIDE, base-type=uint8, compu {phys=raw}, range phys 0..255
          signal StatusCPDData4FBD_VL_CIRData116: start 480, 8 bit, little-endian, data-type-policy=OVERRIDE, base-type=uint8, compu {phys=raw}, range phys 0..255
          signal StatusCPDData4FBD_VL_CIRData117: start 488, 8 bit, little-endian, data-type-policy=OVERRIDE, base-type=uint8, compu {phys=raw}, range phys 0..255
          signal StatusCPDData4FBD_VL_CIRData118: start 496, 8 bit, little-endian, data-type-policy=OVERRIDE, base-type=uint8, compu {phys=raw}, range phys 0..255
          signal StatusCPDData4FBD_VL_CIRData119: start 504, 8 bit, little-endian, data-type-policy=OVERRIDE, base-type=uint8, compu {phys=raw}, range phys 0..255
      frame StatusCPDData4FBD_VM: id 0x168, frame-length=64, can-addressing-mode=STANDARD, can-frame-rx-behavior=CAN-FD, can-frame-tx-behavior=CAN-FD
        pdu StatusCPDData4FBD_VM: length=64, unused-bit-pattern=0
          signal StatusCPDData4FBD_VM_MsgCounter: start 0, 8 bit, little-endian, data-type-policy=OVERRIDE, base-type=uint8, compu {phys=raw}, range phys 0..252
          signal StatusCPDData4FBD_VM_LinkID: start 8, 8 bit, little-endian, data-type-policy=OVERRIDE, base-type=uint8, compu {phys=raw}, range phys 0..252
          signal StatusCPDData4FBD_VM_CollisionCounter: start 16, 8 bit, little-endian, data-type-policy=OVERRIDE, base-type=uint8, compu {phys=raw}, range phys 0..252
          signal StatusCPDData4FBD_VM_CIRSetting: start 24, 8 bit, little-endian, data-type-policy=OVERRIDE, compu {phys=raw}
          signal StatusCPDData4FBD_VM_CIRData60: start 32, 8 bit, little-endian, data-type-policy=OVERRIDE, base-type=uint8, compu {phys=raw}, range phys 0..255
          signal StatusCPDData4FBD_VM_CIRData61: start 40, 8 bit, little-endian, data-type-policy=OVERRIDE, base-type=uint8, compu {phys=raw}, range phys 0..255
          signal StatusCPDData4FBD_VM_CIRData62: start 48, 8 bit, little-endian, data-type-policy=OVERRIDE, base-type=uint8, compu {phys=raw}, range phys 0..255
          signal StatusCPDData4FBD_VM_CIRData63: start 56, 8 bit, little-endian, data-type-policy=OVERRIDE, base-type=uint8, compu {phys=raw}, range phys 0..255
          signal StatusCPDData4FBD_VM_CIRData64: start 64, 8 bit, little-endian, data-type-policy=OVERRIDE, base-type=uint8, compu {phys=raw}, range phys 0..255
          signal StatusCPDData4FBD_VM_CIRData65: start 72, 8 bit, little-endian, data-type-policy=OVERRIDE, base-type=uint8, compu {phys=raw}, range phys 0..255
          signal StatusCPDData4FBD_VM_CIRData66: start 80, 8 bit, little-endian, data-type-policy=OVERRIDE, base-type=uint8, compu {phys=raw}, range phys 0..255
          signal StatusCPDData4FBD_VM_CIRData67: start 88, 8 bit, little-endian, data-type-policy=OVERRIDE, base-type=uint8, compu {phys=raw}, range phys 0..255
          signal StatusCPDData4FBD_VM_CIRData68: start 96, 8 bit, little-endian, data-type-policy=OVERRIDE, base-type=uint8, compu {phys=raw}, range phys 0..255
          signal StatusCPDData4FBD_VM_CIRData69: start 104, 8 bit, little-endian, data-type-policy=OVERRIDE, base-type=uint8, compu {phys=raw}, range phys 0..255
          signal StatusCPDData4FBD_VM_CIRData70: start 112, 8 bit, little-endian, data-type-policy=OVERRIDE, base-type=uint8, compu {phys=raw}, range phys 0..255
          signal StatusCPDData4FBD_VM_CIRData71: start 120, 8 bit, little-endian, data-type-policy=OVERRIDE, base-type=uint8, compu {phys=raw}, range phys 0..255
          signal StatusCPDData4FBD_VM_CIRData72: start 128, 8 bit, little-endian, data-type-policy=OVERRIDE, base-type=uint8, compu {phys=raw}, range phys 0..255
          signal StatusCPDData4FBD_VM_CIRData73: start 136, 8 bit, little-endian, data-type-policy=OVERRIDE, base-type=uint8, compu {phys=raw}, range phys 0..255
          signal StatusCPDData4FBD_VM_CIRData74: start 144, 8 bit, little-endian, data-type-policy=OVERRIDE, base-type=uint8, compu {phys=raw}, range phys 0..255
          signal StatusCPDData4FBD_VM_CIRData75: start 152, 8 bit, little-endian, data-type-policy=OVERRIDE, base-type=uint8, compu {phys=raw}, range phys 0..255
          signal StatusCPDData4FBD_VM_CIRData76: start 160, 8 bit, little-endian, data-type-policy=OVERRIDE, base-type=uint8, compu {phys=raw}, range phys 0..255
          signal StatusCPDData4FBD_VM_CIRData77: start 168, 8 bit, little-endian, data-type-policy=OVERRIDE, base-type=uint8, compu {phys=raw}, range phys 0..255
          signal StatusCPDData4FBD_VM_CIRData78: start 176, 8 bit, little-endian, data-type-policy=OVERRIDE, base-type=uint8, compu {phys=raw}, range phys 0..255
          signal StatusCPDData4FBD_VM_CIRData79: start 184, 8 bit, little-endian, data-type-policy=OVERRIDE, base-type=uint8, compu {phys=raw}, range phys 0..255
          signal StatusCPDData4FBD_VM_CIRData80: start 192, 8 bit, little-endian, data-type-policy=OVERRIDE, base-type=uint8, compu {phys=raw}, range phys 0..255
          signal StatusCPDData4FBD_VM_CIRData81: start 200, 8 bit, little-endian, data-type-policy=OVERRIDE, base-type=uint8, compu {phys=raw}, range phys 0..255
          signal StatusCPDData4FBD_VM_CIRData82: start 208, 8 bit, little-endian, data-type-policy=OVERRIDE, base-type=uint8, compu {phys=raw}, range phys 0..255
          signal StatusCPDData4FBD_VM_CIRData83: start 216, 8 bit, little-endian, data-type-policy=OVERRIDE, base-type=uint8, compu {phys=raw}, range phys 0..255
          signal StatusCPDData4FBD_VM_CIRData84: start 224, 8 bit, little-endian, data-type-policy=OVERRIDE, base-type=uint8, compu {phys=raw}, range phys 0..255
          signal StatusCPDData4FBD_VM_CIRData85: start 232, 8 bit, little-endian, data-type-policy=OVERRIDE, base-type=uint8, compu {phys=raw}, range phys 0..255
          signal StatusCPDData4FBD_VM_CIRData86: start 240, 8 bit, little-endian, data-type-policy=OVERRIDE, base-type=uint8, compu {phys=raw}, range phys 0..255
          signal StatusCPDData4FBD_VM_CIRData87: start 248, 8 bit, little-endian, data-type-policy=OVERRIDE, base-type=uint8, compu {phys=raw}, range phys 0..255
          signal StatusCPDData4FBD_VM_CIRData88: start 256, 8 bit, little-endian, data-type-policy=OVERRIDE, base-type=uint8, compu {phys=raw}, range phys 0..255
          signal StatusCPDData4FBD_VM_CIRData89: start 264, 8 bit, little-endian, data-type-policy=OVERRIDE, base-type=uint8, compu {phys=raw}, range phys 0..255
          signal StatusCPDData4FBD_VM_CIRData90: start 272, 8 bit, little-endian, data-type-policy=OVERRIDE, base-type=uint8, compu {phys=raw}, range phys 0..255
          signal StatusCPDData4FBD_VM_CIRData91: start 280, 8 bit, little-endian, data-type-policy=OVERRIDE, base-type=uint8, compu {phys=raw}, range phys 0..255
          signal StatusCPDData4FBD_VM_CIRData92: start 288, 8 bit, little-endian, data-type-policy=OVERRIDE, base-type=uint8, compu {phys=raw}, range phys 0..255
          signal StatusCPDData4FBD_VM_CIRData93: start 296, 8 bit, little-endian, data-type-policy=OVERRIDE, base-type=uint8, compu {phys=raw}, range phys 0..255
          signal StatusCPDData4FBD_VM_CIRData94: start 304, 8 bit, little-endian, data-type-policy=OVERRIDE, base-type=uint8, compu {phys=raw}, range phys 0..255
          signal StatusCPDData4FBD_VM_CIRData95: start 312, 8 bit, little-endian, data-type-policy=OVERRIDE, base-type=uint8, compu {phys=raw}, range phys 0..255
          signal StatusCPDData4FBD_VM_CIRData96: start 320, 8 bit, little-endian, data-type-policy=OVERRIDE, base-type=uint8, compu {phys=raw}, range phys 0..255
          signal StatusCPDData4FBD_VM_CIRData97: start 328, 8 bit, little-endian, data-type-policy=OVERRIDE, base-type=uint8, compu {phys=raw}, range phys 0..255
          signal StatusCPDData4FBD_VM_CIRData98: start 336, 8 bit, little-endian, data-type-policy=OVERRIDE, base-type=uint8, compu {phys=raw}, range phys 0..255
          signal StatusCPDData4FBD_VM_CIRData99: start 344, 8 bit, little-endian, data-type-policy=OVERRIDE, base-type=uint8, compu {phys=raw}, range phys 0..255
          signal StatusCPDData4FBD_VM_CIRData100: start 352, 8 bit, little-endian, data-type-policy=OVERRIDE, base-type=uint8, compu {phys=raw}, range phys 0..255
          signal StatusCPDData4FBD_VM_CIRData101: start 360, 8 bit, little-endian, data-type-policy=OVERRIDE, base-type=uint8, compu {phys=raw}, range phys 0..255
          signal StatusCPDData4FBD_VM_CIRData102: start 368, 8 bit, little-endian, data-type-policy=OVERRIDE, base-type=uint8, compu {phys=raw}, range phys 0..255
          signal StatusCPDData4FBD_VM_CIRData103: start 376, 8 bit, little-endian, data-type-policy=OVERRIDE, base-type=uint8, compu {phys=raw}, range phys 0..255
          signal StatusCPDData4FBD_VM_CIRData104: start 384, 8 bit, little-endian, data-type-policy=OVERRIDE, base-type=uint8, compu {phys=raw}, range phys 0..255
          signal StatusCPDData4FBD_VM_CIRData105: start 392, 8 bit, little-endian, data-type-policy=OVERRIDE, base-type=uint8, compu {phys=raw}, range phys 0..255
          signal StatusCPDData4FBD_VM_CIRData106: start 400, 8 bit, little-endian, data-type-policy=OVERRIDE, base-type=uint8, compu {phys=raw}, range phys 0..255
          signal StatusCPDData4FBD_VM_CIRData107: start 408, 8 bit, little-endian, data-type-policy=OVERRIDE, base-type=uint8, compu {phys=raw}, range phys 0..255
          signal StatusCPDData4FBD_VM_CIRData108: start 416, 8 bit, little-endian, data-type-policy=OVERRIDE, base-type=uint8, compu {phys=raw}, range phys 0..255
          signal StatusCPDData4FBD_VM_CIRData109: start 424, 8 bit, little-endian, data-type-policy=OVERRIDE, base-type=uint8, compu {phys=raw}, range phys 0..255
          signal StatusCPDData4FBD_VM_CIRData110: start 432, 8 bit, little-endian, data-type-policy=OVERRIDE, base-type=uint8, compu {phys=raw}, range phys 0..255
          signal StatusCPDData4FBD_VM_CIRData111: start 440, 8 bit, little-endian, data-type-policy=OVERRIDE, base-type=uint8, compu {phys=raw}, range phys 0..255
          signal StatusCPDData4FBD_VM_CIRData112: start 448, 8 bit, little-endian, data-type-policy=OVERRIDE, base-type=uint8, compu {phys=raw}, range phys 0..255
          signal StatusCPDData4FBD_VM_CIRData113: start 456, 8 bit, little-endian, data-type-policy=OVERRIDE, base-type=uint8, compu {phys=raw}, range phys 0..255
          signal StatusCPDData4FBD_VM_CIRData114: start 464, 8 bit, little-endian, data-type-policy=OVERRIDE, base-type=uint8, compu {phys=raw}, range phys 0..255
          signal StatusCPDData4FBD_VM_CIRData115: start 472, 8 bit, little-endian, data-type-policy=OVERRIDE, base-type=uint8, compu {phys=raw}, range phys 0..255
          signal StatusCPDData4FBD_VM_CIRData116: start 480, 8 bit, little-endian, data-type-policy=OVERRIDE, base-type=uint8, compu {phys=raw}, range phys 0..255
          signal StatusCPDData4FBD_VM_CIRData117: start 488, 8 bit, little-endian, data-type-policy=OVERRIDE, base-type=uint8, compu {phys=raw}, range phys 0..255
          signal StatusCPDData4FBD_VM_CIRData118: start 496, 8 bit, little-endian, data-type-policy=OVERRIDE, base-type=uint8, compu {phys=raw}, range phys 0..255
          signal StatusCPDData4FBD_VM_CIRData119: start 504, 8 bit, little-endian, data-type-policy=OVERRIDE, base-type=uint8, compu {phys=raw}, range phys 0..255
      frame StatusCPDData4FBD_VR: id 0x16D, frame-length=64, can-addressing-mode=STANDARD, can-frame-rx-behavior=CAN-FD, can-frame-tx-behavior=CAN-FD
        pdu StatusCPDData4FBD_VR: length=64, unused-bit-pattern=0
          signal StatusCPDData4FBD_VR_MsgCounter: start 0, 8 bit, little-endian, data-type-policy=OVERRIDE, base-type=uint8, compu {phys=raw}, range phys 0..252
          signal StatusCPDData4FBD_VR_LinkID: start 8, 8 bit, little-endian, data-type-policy=OVERRIDE, base-type=uint8, compu {phys=raw}, range phys 0..252
          signal StatusCPDData4FBD_VR_CollisionCounter: start 16, 8 bit, little-endian, data-type-policy=OVERRIDE, base-type=uint8, compu {phys=raw}, range phys 0..252
          signal StatusCPDData4FBD_VR_CIRSetting: start 24, 8 bit, little-endian, data-type-policy=OVERRIDE, compu {phys=raw}
          signal StatusCPDData4FBD_VR_CIRData60: start 32, 8 bit, little-endian, data-type-policy=OVERRIDE, base-type=uint8, compu {phys=raw}, range phys 0..255
          signal StatusCPDData4FBD_VR_CIRData61: start 40, 8 bit, little-endian, data-type-policy=OVERRIDE, base-type=uint8, compu {phys=raw}, range phys 0..255
          signal StatusCPDData4FBD_VR_CIRData62: start 48, 8 bit, little-endian, data-type-policy=OVERRIDE, base-type=uint8, compu {phys=raw}, range phys 0..255
          signal StatusCPDData4FBD_VR_CIRData63: start 56, 8 bit, little-endian, data-type-policy=OVERRIDE, base-type=uint8, compu {phys=raw}, range phys 0..255
          signal StatusCPDData4FBD_VR_CIRData64: start 64, 8 bit, little-endian, data-type-policy=OVERRIDE, base-type=uint8, compu {phys=raw}, range phys 0..255
          signal StatusCPDData4FBD_VR_CIRData65: start 72, 8 bit, little-endian, data-type-policy=OVERRIDE, base-type=uint8, compu {phys=raw}, range phys 0..255
          signal StatusCPDData4FBD_VR_CIRData66: start 80, 8 bit, little-endian, data-type-policy=OVERRIDE, base-type=uint8, compu {phys=raw}, range phys 0..255
          signal StatusCPDData4FBD_VR_CIRData67: start 88, 8 bit, little-endian, data-type-policy=OVERRIDE, base-type=uint8, compu {phys=raw}, range phys 0..255
          signal StatusCPDData4FBD_VR_CIRData68: start 96, 8 bit, little-endian, data-type-policy=OVERRIDE, base-type=uint8, compu {phys=raw}, range phys 0..255
          signal StatusCPDData4FBD_VR_CIRData69: start 104, 8 bit, little-endian, data-type-policy=OVERRIDE, base-type=uint8, compu {phys=raw}, range phys 0..255
          signal StatusCPDData4FBD_VR_CIRData70: start 112, 8 bit, little-endian, data-type-policy=OVERRIDE, base-type=uint8, compu {phys=raw}, range phys 0..255
          signal StatusCPDData4FBD_VR_CIRData71: start 120, 8 bit, little-endian, data-type-policy=OVERRIDE, base-type=uint8, compu {phys=raw}, range phys 0..255
          signal StatusCPDData4FBD_VR_CIRData72: start 128, 8 bit, little-endian, data-type-policy=OVERRIDE, base-type=uint8, compu {phys=raw}, range phys 0..255
          signal StatusCPDData4FBD_VR_CIRData73: start 136, 8 bit, little-endian, data-type-policy=OVERRIDE, base-type=uint8, compu {phys=raw}, range phys 0..255
          signal StatusCPDData4FBD_VR_CIRData74: start 144, 8 bit, little-endian, data-type-policy=OVERRIDE, base-type=uint8, compu {phys=raw}, range phys 0..255
          signal StatusCPDData4FBD_VR_CIRData75: start 152, 8 bit, little-endian, data-type-policy=OVERRIDE, base-type=uint8, compu {phys=raw}, range phys 0..255
          signal StatusCPDData4FBD_VR_CIRData76: start 160, 8 bit, little-endian, data-type-policy=OVERRIDE, base-type=uint8, compu {phys=raw}, range phys 0..255
          signal StatusCPDData4FBD_VR_CIRData77: start 168, 8 bit, little-endian, data-type-policy=OVERRIDE, base-type=uint8, compu {phys=raw}, range phys 0..255
          signal StatusCPDData4FBD_VR_CIRData78: start 176, 8 bit, little-endian, data-type-policy=OVERRIDE, base-type=uint8, compu {phys=raw}, range phys 0..255
          signal StatusCPDData4FBD_VR_CIRData79: start 184, 8 bit, little-endian, data-type-policy=OVERRIDE, base-type=uint8, compu {phys=raw}, range phys 0..255
          signal StatusCPDData4FBD_VR_CIRData80: start 192, 8 bit, little-endian, data-type-policy=OVERRIDE, base-type=uint8, compu {phys=raw}, range phys 0..255
          signal StatusCPDData4FBD_VR_CIRData81: start 200, 8 bit, little-endian, data-type-policy=OVERRIDE, base-type=uint8, compu {phys=raw}, range phys 0..255
          signal StatusCPDData4FBD_VR_CIRData82: start 208, 8 bit, little-endian, data-type-policy=OVERRIDE, base-type=uint8, compu {phys=raw}, range phys 0..255
          signal StatusCPDData4FBD_VR_CIRData83: start 216, 8 bit, little-endian, data-type-policy=OVERRIDE, base-type=uint8, compu {phys=raw}, range phys 0..255
          signal StatusCPDData4FBD_VR_CIRData84: start 224, 8 bit, little-endian, data-type-policy=OVERRIDE, base-type=uint8, compu {phys=raw}, range phys 0..255
          signal StatusCPDData4FBD_VR_CIRData85: start 232, 8 bit, little-endian, data-type-policy=OVERRIDE, base-type=uint8, compu {phys=raw}, range phys 0..255
          signal StatusCPDData4FBD_VR_CIRData86: start 240, 8 bit, little-endian, data-type-policy=OVERRIDE, base-type=uint8, compu {phys=raw}, range phys 0..255
          signal StatusCPDData4FBD_VR_CIRData87: start 248, 8 bit, little-endian, data-type-policy=OVERRIDE, base-type=uint8, compu {phys=raw}, range phys 0..255
          signal StatusCPDData4FBD_VR_CIRData88: start 256, 8 bit, little-endian, data-type-policy=OVERRIDE, base-type=uint8, compu {phys=raw}, range phys 0..255
          signal StatusCPDData4FBD_VR_CIRData89: start 264, 8 bit, little-endian, data-type-policy=OVERRIDE, base-type=uint8, compu {phys=raw}, range phys 0..255
          signal StatusCPDData4FBD_VR_CIRData90: start 272, 8 bit, little-endian, data-type-policy=OVERRIDE, base-type=uint8, compu {phys=raw}, range phys 0..255
          signal StatusCPDData4FBD_VR_CIRData91: start 280, 8 bit, little-endian, data-type-policy=OVERRIDE, base-type=uint8, compu {phys=raw}, range phys 0..255
          signal StatusCPDData4FBD_VR_CIRData92: start 288, 8 bit, little-endian, data-type-policy=OVERRIDE, base-type=uint8, compu {phys=raw}, range phys 0..255
          signal StatusCPDData4FBD_VR_CIRData93: start 296, 8 bit, little-endian, data-type-policy=OVERRIDE, base-type=uint8, compu {phys=raw}, range phys 0..255
          signal StatusCPDData4FBD_VR_CIRData94: start 304, 8 bit, little-endian, data-type-policy=OVERRIDE, base-type=uint8, compu {phys=raw}, range phys 0..255
          signal StatusCPDData4FBD_VR_CIRData95: start 312, 8 bit, little-endian, data-type-policy=OVERRIDE, base-type=uint8, compu {phys=raw}, range phys 0..255
          signal StatusCPDData4FBD_VR_CIRData96: start 320, 8 bit, little-endian, data-type-policy=OVERRIDE, base-type=uint8, compu {phys=raw}, range phys 0..255
          signal StatusCPDData4FBD_VR_CIRData97: start 328, 8 bit, little-endian, data-type-policy=OVERRIDE, base-type=uint8, compu {phys=raw}, range phys 0..255
          signal StatusCPDData4FBD_VR_CIRData98: start 336, 8 bit, little-endian, data-type-policy=OVERRIDE, base-type=uint8, compu {phys=raw}, range phys 0..255
          signal StatusCPDData4FBD_VR_CIRData99: start 344, 8 bit, little-endian, data-type-policy=OVERRIDE, base-type=uint8, compu {phys=raw}, range phys 0..255
          signal StatusCPDData4FBD_VR_CIRData100: start 352, 8 bit, little-endian, data-type-policy=OVERRIDE, base-type=uint8, compu {phys=raw}, range phys 0..255
          signal StatusCPDData4FBD_VR_CIRData101: start 360, 8 bit, little-endian, data-type-policy=OVERRIDE, base-type=uint8, compu {phys=raw}, range phys 0..255
          signal StatusCPDData4FBD_VR_CIRData102: start 368, 8 bit, little-endian, data-type-policy=OVERRIDE, base-type=uint8, compu {phys=raw}, range phys 0..255
          signal StatusCPDData4FBD_VR_CIRData103: start 376, 8 bit, little-endian, data-type-policy=OVERRIDE, base-type=uint8, compu {phys=raw}, range phys 0..255
          signal StatusCPDData4FBD_VR_CIRData104: start 384, 8 bit, little-endian, data-type-policy=OVERRIDE, base-type=uint8, compu {phys=raw}, range phys 0..255
          signal StatusCPDData4FBD_VR_CIRData105: start 392, 8 bit, little-endian, data-type-policy=OVERRIDE, base-type=uint8, compu {phys=raw}, range phys 0..255
          signal StatusCPDData4FBD_VR_CIRData106: start 400, 8 bit, little-endian, data-type-policy=OVERRIDE, base-type=uint8, compu {phys=raw}, range phys 0..255
          signal StatusCPDData4FBD_VR_CIRData107: start 408, 8 bit, little-endian, data-type-policy=OVERRIDE, base-type=uint8, compu {phys=raw}, range phys 0..255
          signal StatusCPDData4FBD_VR_CIRData108: start 416, 8 bit, little-endian, data-type-policy=OVERRIDE, base-type=uint8, compu {phys=raw}, range phys 0..255
          signal StatusCPDData4FBD_VR_CIRData109: start 424, 8 bit, little-endian, data-type-policy=OVERRIDE, base-type=uint8, compu {phys=raw}, range phys 0..255
          signal StatusCPDData4FBD_VR_CIRData110: start 432, 8 bit, little-endian, data-type-policy=OVERRIDE, base-type=uint8, compu {phys=raw}, range phys 0..255
          signal StatusCPDData4FBD_VR_CIRData111: start 440, 8 bit, little-endian, data-type-policy=OVERRIDE, base-type=uint8, compu {phys=raw}, range phys 0..255
          signal StatusCPDData4FBD_VR_CIRData112: start 448, 8 bit, little-endian, data-type-policy=OVERRIDE, base-type=uint8, compu {phys=raw}, range phys 0..255
          signal StatusCPDData4FBD_VR_CIRData113: start 456, 8 bit, little-endian, data-type-policy=OVERRIDE, base-type=uint8, compu {phys=raw}, range phys 0..255
          signal StatusCPDData4FBD_VR_CIRData114: start 464, 8 bit, little-endian, data-type-policy=OVERRIDE, base-type=uint8, compu {phys=raw}, range phys 0..255
          signal StatusCPDData4FBD_VR_CIRData115: start 472, 8 bit, little-endian, data-type-policy=OVERRIDE, base-type=uint8, compu {phys=raw}, range phys 0..255
          signal StatusCPDData4FBD_VR_CIRData116: start 480, 8 bit, little-endian, data-type-policy=OVERRIDE, base-type=uint8, compu {phys=raw}, range phys 0..255
          signal StatusCPDData4FBD_VR_CIRData117: start 488, 8 bit, little-endian, data-type-policy=OVERRIDE, base-type=uint8, compu {phys=raw}, range phys 0..255
          signal StatusCPDData4FBD_VR_CIRData118: start 496, 8 bit, little-endian, data-type-policy=OVERRIDE, base-type=uint8, compu {phys=raw}, range phys 0..255
          signal StatusCPDData4FBD_VR_CIRData119: start 504, 8 bit, little-endian, data-type-policy=OVERRIDE, base-type=uint8, compu {phys=raw}, range phys 0..255
      frame StatusCSRangingFBD_HL: id 0xC4, frame-length=24, can-addressing-mode=STANDARD, can-frame-rx-behavior=CAN-FD, can-frame-tx-behavior=CAN-FD
        pdu StatusCSRangingFBD_HL: length=24, unused-bit-pattern=0
          signal StatusCSRangingFBD_HL_SessionID: start 0, 8 bit, little-endian, data-type-policy=OVERRIDE, base-type=uint8, compu {phys=raw}, range phys 0..252
          signal StatusCSRangingFBD_HL_IRKListIndex: start 8, 8 bit, little-endian, data-type-policy=OVERRIDE, base-type=uint8, compu {phys=raw}, range phys 0..252
          signal StatusCSRangingFBD_HL_Distance: start 16, 16 bit, little-endian, data-type-policy=OVERRIDE, base-type=uint16, compu {phys=raw; unit cm}, range phys 0..65532
          signal StatusCSRangingFBD_HL_ProcedureCount: start 32, 16 bit, little-endian, data-type-policy=OVERRIDE, base-type=uint16, compu {phys=raw}, range phys 0..65532
          signal StatusCSRangingFBD_HL_Quality: start 48, 8 bit, little-endian, data-type-policy=OVERRIDE, base-type=uint8, compu {phys=raw}, range phys 0..252
          signal StatusCSRangingFBD_HL_RoundTripTime: start 56, 16 bit, little-endian, data-type-policy=OVERRIDE, base-type=uint16, compu {phys=raw; unit cm}, range phys 0..65532
          signal StatusCSRangingFBD_HL_IV00: start 72, 8 bit, little-endian, data-type-policy=OVERRIDE, base-type=uint8, compu {phys=raw}, range phys 0..255
          signal StatusCSRangingFBD_HL_IV01: start 80, 8 bit, little-endian, data-type-policy=OVERRIDE, base-type=uint8, compu {phys=raw}, range phys 0..255
          signal StatusCSRangingFBD_HL_IV02: start 88, 8 bit, little-endian, data-type-policy=OVERRIDE, base-type=uint8, compu {phys=raw}, range phys 0..255
          signal StatusCSRangingFBD_HL_IV03: start 96, 8 bit, little-endian, data-type-policy=OVERRIDE, base-type=uint8, compu {phys=raw}, range phys 0..255
          signal StatusCSRangingFBD_HL_Sign00: start 104, 8 bit, little-endian, data-type-policy=OVERRIDE, base-type=uint8, compu {phys=raw}, range phys 0..255
          signal StatusCSRangingFBD_HL_Sign01: start 112, 8 bit, little-endian, data-type-policy=OVERRIDE, base-type=uint8, compu {phys=raw}, range phys 0..255
          signal StatusCSRangingFBD_HL_Sign02: start 120, 8 bit, little-endian, data-type-policy=OVERRIDE, base-type=uint8, compu {phys=raw}, range phys 0..255
          signal StatusCSRangingFBD_HL_Sign03: start 128, 8 bit, little-endian, data-type-policy=OVERRIDE, base-type=uint8, compu {phys=raw}, range phys 0..255
          signal StatusCSRangingFBD_HL_Sign04: start 136, 8 bit, little-endian, data-type-policy=OVERRIDE, base-type=uint8, compu {phys=raw}, range phys 0..255
          signal StatusCSRangingFBD_HL_Sign05: start 144, 8 bit, little-endian, data-type-policy=OVERRIDE, base-type=uint8, compu {phys=raw}, range phys 0..255
          signal StatusCSRangingFBD_HL_Sign06: start 152, 8 bit, little-endian, data-type-policy=OVERRIDE, base-type=uint8, compu {phys=raw}, range phys 0..255
          signal StatusCSRangingFBD_HL_Sign07: start 160, 8 bit, little-endian, data-type-policy=OVERRIDE, base-type=uint8, compu {phys=raw}, range phys 0..255
          signal StatusCSRangingFBD_HL_Status1: start 168, 8 bit, little-endian, data-type-policy=OVERRIDE, base-type=uint8, compu {phys=raw}, range phys 0..252
          signal StatusCSRangingFBD_HL_Status2: start 176, 8 bit, little-endian, data-type-policy=OVERRIDE, base-type=uint8, compu {phys=raw}, range phys 0..252
          signal StatusCSRangingFBD_HL_NADM: start 184, 8 bit, little-endian, data-type-policy=OVERRIDE, compu {phys=raw}
      frame StatusCSRangingFBD_HM: id 0xBF, frame-length=24, can-addressing-mode=STANDARD, can-frame-rx-behavior=CAN-FD, can-frame-tx-behavior=CAN-FD
        pdu StatusCSRangingFBD_HM: length=24, unused-bit-pattern=0
          signal StatusCSRangingFBD_HM_SessionID: start 0, 8 bit, little-endian, data-type-policy=OVERRIDE, base-type=uint8, compu {phys=raw}, range phys 0..252
          signal StatusCSRangingFBD_HM_IRKListIndex: start 8, 8 bit, little-endian, data-type-policy=OVERRIDE, base-type=uint8, compu {phys=raw}, range phys 0..252
          signal StatusCSRangingFBD_HM_Distance: start 16, 16 bit, little-endian, data-type-policy=OVERRIDE, base-type=uint16, compu {phys=raw; unit cm}, range phys 0..65532
          signal StatusCSRangingFBD_HM_ProcedureCount: start 32, 16 bit, little-endian, data-type-policy=OVERRIDE, base-type=uint16, compu {phys=raw}, range phys 0..65532
          signal StatusCSRangingFBD_HM_Quality: start 48, 8 bit, little-endian, data-type-policy=OVERRIDE, base-type=uint8, compu {phys=raw}, range phys 0..252
          signal StatusCSRangingFBD_HM_RoundTripTime: start 56, 16 bit, little-endian, data-type-policy=OVERRIDE, base-type=uint16, compu {phys=raw; unit cm}, range phys 0..65532
          signal StatusCSRangingFBD_HM_IV00: start 72, 8 bit, little-endian, data-type-policy=OVERRIDE, base-type=uint8, compu {phys=raw}, range phys 0..255
          signal StatusCSRangingFBD_HM_IV01: start 80, 8 bit, little-endian, data-type-policy=OVERRIDE, base-type=uint8, compu {phys=raw}, range phys 0..255
          signal StatusCSRangingFBD_HM_IV02: start 88, 8 bit, little-endian, data-type-policy=OVERRIDE, base-type=uint8, compu {phys=raw}, range phys 0..255
          signal StatusCSRangingFBD_HM_IV03: start 96, 8 bit, little-endian, data-type-policy=OVERRIDE, base-type=uint8, compu {phys=raw}, range phys 0..255
          signal StatusCSRangingFBD_HM_Sign00: start 104, 8 bit, little-endian, data-type-policy=OVERRIDE, base-type=uint8, compu {phys=raw}, range phys 0..255
          signal StatusCSRangingFBD_HM_Sign01: start 112, 8 bit, little-endian, data-type-policy=OVERRIDE, base-type=uint8, compu {phys=raw}, range phys 0..255
          signal StatusCSRangingFBD_HM_Sign02: start 120, 8 bit, little-endian, data-type-policy=OVERRIDE, base-type=uint8, compu {phys=raw}, range phys 0..255
          signal StatusCSRangingFBD_HM_Sign03: start 128, 8 bit, little-endian, data-type-policy=OVERRIDE, base-type=uint8, compu {phys=raw}, range phys 0..255
          signal StatusCSRangingFBD_HM_Sign04: start 136, 8 bit, little-endian, data-type-policy=OVERRIDE, base-type=uint8, compu {phys=raw}, range phys 0..255
          signal StatusCSRangingFBD_HM_Sign05: start 144, 8 bit, little-endian, data-type-policy=OVERRIDE, base-type=uint8, compu {phys=raw}, range phys 0..255
          signal StatusCSRangingFBD_HM_Sign06: start 152, 8 bit, little-endian, data-type-policy=OVERRIDE, base-type=uint8, compu {phys=raw}, range phys 0..255
          signal StatusCSRangingFBD_HM_Sign07: start 160, 8 bit, little-endian, data-type-policy=OVERRIDE, base-type=uint8, compu {phys=raw}, range phys 0..255
          signal StatusCSRangingFBD_HM_Status1: start 168, 8 bit, little-endian, data-type-policy=OVERRIDE, base-type=uint8, compu {phys=raw}, range phys 0..252
          signal StatusCSRangingFBD_HM_Status2: start 176, 8 bit, little-endian, data-type-policy=OVERRIDE, base-type=uint8, compu {phys=raw}, range phys 0..252
          signal StatusCSRangingFBD_HM_NADM: start 184, 8 bit, little-endian, data-type-policy=OVERRIDE, compu {phys=raw}
      frame StatusCSRangingFBD_HR: id 0xC5, frame-length=24, can-addressing-mode=STANDARD, can-frame-rx-behavior=CAN-FD, can-frame-tx-behavior=CAN-FD
        pdu StatusCSRangingFBD_HR: length=24, unused-bit-pattern=0
          signal StatusCSRangingFBD_HR_SessionID: start 0, 8 bit, little-endian, data-type-policy=OVERRIDE, base-type=uint8, compu {phys=raw}, range phys 0..252
          signal StatusCSRangingFBD_HR_IRKListIndex: start 8, 8 bit, little-endian, data-type-policy=OVERRIDE, base-type=uint8, compu {phys=raw}, range phys 0..252
          signal StatusCSRangingFBD_HR_Distance: start 16, 16 bit, little-endian, data-type-policy=OVERRIDE, base-type=uint16, compu {phys=raw; unit cm}, range phys 0..65532
          signal StatusCSRangingFBD_HR_ProcedureCount: start 32, 16 bit, little-endian, data-type-policy=OVERRIDE, base-type=uint16, compu {phys=raw}, range phys 0..65532
          signal StatusCSRangingFBD_HR_Quality: start 48, 8 bit, little-endian, data-type-policy=OVERRIDE, base-type=uint8, compu {phys=raw}, range phys 0..252
          signal StatusCSRangingFBD_HR_RoundTripTime: start 56, 16 bit, little-endian, data-type-policy=OVERRIDE, base-type=uint16, compu {phys=raw; unit cm}, range phys 0..65532
          signal StatusCSRangingFBD_HR_IV00: start 72, 8 bit, little-endian, data-type-policy=OVERRIDE, base-type=uint8, compu {phys=raw}, range phys 0..255
          signal StatusCSRangingFBD_HR_IV01: start 80, 8 bit, little-endian, data-type-policy=OVERRIDE, base-type=uint8, compu {phys=raw}, range phys 0..255
          signal StatusCSRangingFBD_HR_IV02: start 88, 8 bit, little-endian, data-type-policy=OVERRIDE, base-type=uint8, compu {phys=raw}, range phys 0..255
          signal StatusCSRangingFBD_HR_IV03: start 96, 8 bit, little-endian, data-type-policy=OVERRIDE, base-type=uint8, compu {phys=raw}, range phys 0..255
          signal StatusCSRangingFBD_HR_Sign00: start 104, 8 bit, little-endian, data-type-policy=OVERRIDE, base-type=uint8, compu {phys=raw}, range phys 0..255
          signal StatusCSRangingFBD_HR_Sign01: start 112, 8 bit, little-endian, data-type-policy=OVERRIDE, base-type=uint8, compu {phys=raw}, range phys 0..255
          signal StatusCSRangingFBD_HR_Sign02: start 120, 8 bit, little-endian, data-type-policy=OVERRIDE, base-type=uint8, compu {phys=raw}, range phys 0..255
          signal StatusCSRangingFBD_HR_Sign03: start 128, 8 bit, little-endian, data-type-policy=OVERRIDE, base-type=uint8, compu {phys=raw}, range phys 0..255
          signal StatusCSRangingFBD_HR_Sign04: start 136, 8 bit, little-endian, data-type-policy=OVERRIDE, base-type=uint8, compu {phys=raw}, range phys 0..255
          signal StatusCSRangingFBD_HR_Sign05: start 144, 8 bit, little-endian, data-type-policy=OVERRIDE, base-type=uint8, compu {phys=raw}, range phys 0..255
          signal StatusCSRangingFBD_HR_Sign06: start 152, 8 bit, little-endian, data-type-policy=OVERRIDE, base-type=uint8, compu {phys=raw}, range phys 0..255
          signal StatusCSRangingFBD_HR_Sign07: start 160, 8 bit, little-endian, data-type-policy=OVERRIDE, base-type=uint8, compu {phys=raw}, range phys 0..255
          signal StatusCSRangingFBD_HR_Status1: start 168, 8 bit, little-endian, data-type-policy=OVERRIDE, base-type=uint8, compu {phys=raw}, range phys 0..252
          signal StatusCSRangingFBD_HR_Status2: start 176, 8 bit, little-endian, data-type-policy=OVERRIDE, base-type=uint8, compu {phys=raw}, range phys 0..252
          signal StatusCSRangingFBD_HR_NADM: start 184, 8 bit, little-endian, data-type-policy=OVERRIDE, compu {phys=raw}
      frame StatusCSRangingFBD_Miko: id 0xC0, frame-length=24, can-addressing-mode=STANDARD, can-frame-rx-behavior=CAN-FD, can-frame-tx-behavior=CAN-FD
        pdu StatusCSRangingFBD_Miko: length=24, unused-bit-pattern=0
          signal StatusCSRangingFBD_Miko_SessionID: start 0, 8 bit, little-endian, data-type-policy=OVERRIDE, base-type=uint8, compu {phys=raw}, range phys 0..252
          signal StatusCSRangingFBD_Miko_IRKListIndex: start 8, 8 bit, little-endian, data-type-policy=OVERRIDE, base-type=uint8, compu {phys=raw}, range phys 0..252
          signal StatusCSRangingFBD_Miko_Distance: start 16, 16 bit, little-endian, data-type-policy=OVERRIDE, base-type=uint16, compu {phys=raw; unit cm}, range phys 0..65532
          signal StatusCSRangingFBD_Miko_ProcedureCount: start 32, 16 bit, little-endian, data-type-policy=OVERRIDE, base-type=uint16, compu {phys=raw}, range phys 0..65532
          signal StatusCSRangingFBD_Miko_Quality: start 48, 8 bit, little-endian, data-type-policy=OVERRIDE, base-type=uint8, compu {phys=raw}, range phys 0..252
          signal StatusCSRangingFBD_Miko_RoundTripTime: start 56, 16 bit, little-endian, data-type-policy=OVERRIDE, base-type=uint16, compu {phys=raw; unit cm}, range phys 0..65532
          signal StatusCSRangingFBD_Miko_IV00: start 72, 8 bit, little-endian, data-type-policy=OVERRIDE, base-type=uint8, compu {phys=raw}, range phys 0..255
          signal StatusCSRangingFBD_Miko_IV01: start 80, 8 bit, little-endian, data-type-policy=OVERRIDE, base-type=uint8, compu {phys=raw}, range phys 0..255
          signal StatusCSRangingFBD_Miko_IV02: start 88, 8 bit, little-endian, data-type-policy=OVERRIDE, base-type=uint8, compu {phys=raw}, range phys 0..255
          signal StatusCSRangingFBD_Miko_IV03: start 96, 8 bit, little-endian, data-type-policy=OVERRIDE, base-type=uint8, compu {phys=raw}, range phys 0..255
          signal StatusCSRangingFBD_Miko_Sign00: start 104, 8 bit, little-endian, data-type-policy=OVERRIDE, base-type=uint8, compu {phys=raw}, range phys 0..255
          signal StatusCSRangingFBD_Miko_Sign01: start 112, 8 bit, little-endian, data-type-policy=OVERRIDE, base-type=uint8, compu {phys=raw}, range phys 0..255
          signal StatusCSRangingFBD_Miko_Sign02: start 120, 8 bit, little-endian, data-type-policy=OVERRIDE, base-type=uint8, compu {phys=raw}, range phys 0..255
          signal StatusCSRangingFBD_Miko_Sign03: start 128, 8 bit, little-endian, data-type-policy=OVERRIDE, base-type=uint8, compu {phys=raw}, range phys 0..255
          signal StatusCSRangingFBD_Miko_Sign04: start 136, 8 bit, little-endian, data-type-policy=OVERRIDE, base-type=uint8, compu {phys=raw}, range phys 0..255
          signal StatusCSRangingFBD_Miko_Sign05: start 144, 8 bit, little-endian, data-type-policy=OVERRIDE, base-type=uint8, compu {phys=raw}, range phys 0..255
          signal StatusCSRangingFBD_Miko_Sign06: start 152, 8 bit, little-endian, data-type-policy=OVERRIDE, base-type=uint8, compu {phys=raw}, range phys 0..255
          signal StatusCSRangingFBD_Miko_Sign07: start 160, 8 bit, little-endian, data-type-policy=OVERRIDE, base-type=uint8, compu {phys=raw}, range phys 0..255
          signal StatusCSRangingFBD_Miko_Status1: start 168, 8 bit, little-endian, data-type-policy=OVERRIDE, base-type=uint8, compu {phys=raw}, range phys 0..252
          signal StatusCSRangingFBD_Miko_Status2: start 176, 8 bit, little-endian, data-type-policy=OVERRIDE, base-type=uint8, compu {phys=raw}, range phys 0..252
          signal StatusCSRangingFBD_Miko_NADM: start 184, 8 bit, little-endian, data-type-policy=OVERRIDE, compu {phys=raw}
      frame StatusCSRangingFBD_MM: id 0xC6, frame-length=24, can-addressing-mode=STANDARD, can-frame-rx-behavior=CAN-FD, can-frame-tx-behavior=CAN-FD
        pdu StatusCSRangingFBD_MM: length=24, unused-bit-pattern=0
          signal StatusCSRangingFBD_MM_SessionID: start 0, 8 bit, little-endian, data-type-policy=OVERRIDE, base-type=uint8, compu {phys=raw}, range phys 0..252
          signal StatusCSRangingFBD_MM_IRKListIndex: start 8, 8 bit, little-endian, data-type-policy=OVERRIDE, base-type=uint8, compu {phys=raw}, range phys 0..252
          signal StatusCSRangingFBD_MM_Distance: start 16, 16 bit, little-endian, data-type-policy=OVERRIDE, base-type=uint16, compu {phys=raw; unit cm}, range phys 0..65532
          signal StatusCSRangingFBD_MM_ProcedureCount: start 32, 16 bit, little-endian, data-type-policy=OVERRIDE, base-type=uint16, compu {phys=raw}, range phys 0..65532
          signal StatusCSRangingFBD_MM_Quality: start 48, 8 bit, little-endian, data-type-policy=OVERRIDE, base-type=uint8, compu {phys=raw}, range phys 0..252
          signal StatusCSRangingFBD_MM_RoundTripTime: start 56, 16 bit, little-endian, data-type-policy=OVERRIDE, base-type=uint16, compu {phys=raw; unit cm}, range phys 0..65532
          signal StatusCSRangingFBD_MM_IV00: start 72, 8 bit, little-endian, data-type-policy=OVERRIDE, base-type=uint8, compu {phys=raw}, range phys 0..255
          signal StatusCSRangingFBD_MM_IV01: start 80, 8 bit, little-endian, data-type-policy=OVERRIDE, base-type=uint8, compu {phys=raw}, range phys 0..255
          signal StatusCSRangingFBD_MM_IV02: start 88, 8 bit, little-endian, data-type-policy=OVERRIDE, base-type=uint8, compu {phys=raw}, range phys 0..255
          signal StatusCSRangingFBD_MM_IV03: start 96, 8 bit, little-endian, data-type-policy=OVERRIDE, base-type=uint8, compu {phys=raw}, range phys 0..255
          signal StatusCSRangingFBD_MM_Sign00: start 104, 8 bit, little-endian, data-type-policy=OVERRIDE, base-type=uint8, compu {phys=raw}, range phys 0..255
          signal StatusCSRangingFBD_MM_Sign01: start 112, 8 bit, little-endian, data-type-policy=OVERRIDE, base-type=uint8, compu {phys=raw}, range phys 0..255
          signal StatusCSRangingFBD_MM_Sign02: start 120, 8 bit, little-endian, data-type-policy=OVERRIDE, base-type=uint8, compu {phys=raw}, range phys 0..255
          signal StatusCSRangingFBD_MM_Sign03: start 128, 8 bit, little-endian, data-type-policy=OVERRIDE, base-type=uint8, compu {phys=raw}, range phys 0..255
          signal StatusCSRangingFBD_MM_Sign04: start 136, 8 bit, little-endian, data-type-policy=OVERRIDE, base-type=uint8, compu {phys=raw}, range phys 0..255
          signal StatusCSRangingFBD_MM_Sign05: start 144, 8 bit, little-endian, data-type-policy=OVERRIDE, base-type=uint8, compu {phys=raw}, range phys 0..255
          signal StatusCSRangingFBD_MM_Sign06: start 152, 8 bit, little-endian, data-type-policy=OVERRIDE, base-type=uint8, compu {phys=raw}, range phys 0..255
          signal StatusCSRangingFBD_MM_Sign07: start 160, 8 bit, little-endian, data-type-policy=OVERRIDE, base-type=uint8, compu {phys=raw}, range phys 0..255
          signal StatusCSRangingFBD_MM_Status1: start 168, 8 bit, little-endian, data-type-policy=OVERRIDE, base-type=uint8, compu {phys=raw}, range phys 0..252
          signal StatusCSRangingFBD_MM_Status2: start 176, 8 bit, little-endian, data-type-policy=OVERRIDE, base-type=uint8, compu {phys=raw}, range phys 0..252
          signal StatusCSRangingFBD_MM_NADM: start 184, 8 bit, little-endian, data-type-policy=OVERRIDE, compu {phys=raw}
      frame StatusCSRangingFBD_Trunk: id 0xC1, frame-length=24, can-addressing-mode=STANDARD, can-frame-rx-behavior=CAN-FD, can-frame-tx-behavior=CAN-FD
        pdu StatusCSRangingFBD_Trunk: length=24, unused-bit-pattern=0
          signal StatusCSRangingFBD_Trunk_SessionID: start 0, 8 bit, little-endian, data-type-policy=OVERRIDE, base-type=uint8, compu {phys=raw}, range phys 0..252
          signal StatusCSRangingFBD_Trunk_IRKListIndex: start 8, 8 bit, little-endian, data-type-policy=OVERRIDE, base-type=uint8, compu {phys=raw}, range phys 0..252
          signal StatusCSRangingFBD_Trunk_Distance: start 16, 16 bit, little-endian, data-type-policy=OVERRIDE, base-type=uint16, compu {phys=raw; unit cm}, range phys 0..65532
          signal StatusCSRangingFBD_Trunk_ProcedureCount: start 32, 16 bit, little-endian, data-type-policy=OVERRIDE, base-type=uint16, compu {phys=raw}, range phys 0..65532
          signal StatusCSRangingFBD_Trunk_Quality: start 48, 8 bit, little-endian, data-type-policy=OVERRIDE, base-type=uint8, compu {phys=raw}, range phys 0..252
          signal StatusCSRangingFBD_Trunk_RoundTripTime: start 56, 16 bit, little-endian, data-type-policy=OVERRIDE, base-type=uint16, compu {phys=raw; unit cm}, range phys 0..65532
          signal StatusCSRangingFBD_Trunk_IV00: start 72, 8 bit, little-endian, data-type-policy=OVERRIDE, base-type=uint8, compu {phys=raw}, range phys 0..255
          signal StatusCSRangingFBD_Trunk_IV01: start 80, 8 bit, little-endian, data-type-policy=OVERRIDE, base-type=uint8, compu {phys=raw}, range phys 0..255
          signal StatusCSRangingFBD_Trunk_IV02: start 88, 8 bit, little-endian, data-type-policy=OVERRIDE, base-type=uint8, compu {phys=raw}, range phys 0..255
          signal StatusCSRangingFBD_Trunk_IV03: start 96, 8 bit, little-endian, data-type-policy=OVERRIDE, base-type=uint8, compu {phys=raw}, range phys 0..255
          signal StatusCSRangingFBD_Trunk_Sign00: start 104, 8 bit, little-endian, data-type-policy=OVERRIDE, base-type=uint8, compu {phys=raw}, range phys 0..255
          signal StatusCSRangingFBD_Trunk_Sign01: start 112, 8 bit, little-endian, data-type-policy=OVERRIDE, base-type=uint8, compu {phys=raw}, range phys 0..255
          signal StatusCSRangingFBD_Trunk_Sign02: start 120, 8 bit, little-endian, data-type-policy=OVERRIDE, base-type=uint8, compu {phys=raw}, range phys 0..255
          signal StatusCSRangingFBD_Trunk_Sign03: start 128, 8 bit, little-endian, data-type-policy=OVERRIDE, base-type=uint8, compu {phys=raw}, range phys 0..255
          signal StatusCSRangingFBD_Trunk_Sign04: start 136, 8 bit, little-endian, data-type-policy=OVERRIDE, base-type=uint8, compu {phys=raw}, range phys 0..255
          signal StatusCSRangingFBD_Trunk_Sign05: start 144, 8 bit, little-endian, data-type-policy=OVERRIDE, base-type=uint8, compu {phys=raw}, range phys 0..255
          signal StatusCSRangingFBD_Trunk_Sign06: start 152, 8 bit, little-endian, data-type-policy=OVERRIDE, base-type=uint8, compu {phys=raw}, range phys 0..255
          signal StatusCSRangingFBD_Trunk_Sign07: start 160, 8 bit, little-endian, data-type-policy=OVERRIDE, base-type=uint8, compu {phys=raw}, range phys 0..255
          signal StatusCSRangingFBD_Trunk_Status1: start 168, 8 bit, little-endian, data-type-policy=OVERRIDE, base-type=uint8, compu {phys=raw}, range phys 0..252
          signal StatusCSRangingFBD_Trunk_Status2: start 176, 8 bit, little-endian, data-type-policy=OVERRIDE, base-type=uint8, compu {phys=raw}, range phys 0..252
          signal StatusCSRangingFBD_Trunk_NADM: start 184, 8 bit, little-endian, data-type-policy=OVERRIDE, compu {phys=raw}
      frame StatusCSRangingFBD_VL: id 0xC2, frame-length=24, can-addressing-mode=STANDARD, can-frame-rx-behavior=CAN-FD, can-frame-tx-behavior=CAN-FD
        pdu StatusCSRangingFBD_VL: length=24, unused-bit-pattern=0
          signal StatusCSRangingFBD_VL_SessionID: start 0, 8 bit, little-endian, data-type-policy=OVERRIDE, base-type=uint8, compu {phys=raw}, range phys 0..252
          signal StatusCSRangingFBD_VL_IRKListIndex: start 8, 8 bit, little-endian, data-type-policy=OVERRIDE, base-type=uint8, compu {phys=raw}, range phys 0..252
          signal StatusCSRangingFBD_VL_Distance: start 16, 16 bit, little-endian, data-type-policy=OVERRIDE, base-type=uint16, compu {phys=raw; unit cm}, range phys 0..65532
          signal StatusCSRangingFBD_VL_ProcedureCount: start 32, 16 bit, little-endian, data-type-policy=OVERRIDE, base-type=uint16, compu {phys=raw}, range phys 0..65532
          signal StatusCSRangingFBD_VL_Quality: start 48, 8 bit, little-endian, data-type-policy=OVERRIDE, base-type=uint8, compu {phys=raw}, range phys 0..252
          signal StatusCSRangingFBD_VL_RoundTripTime: start 56, 16 bit, little-endian, data-type-policy=OVERRIDE, base-type=uint16, compu {phys=raw; unit cm}, range phys 0..65532
          signal StatusCSRangingFBD_VL_IV00: start 72, 8 bit, little-endian, data-type-policy=OVERRIDE, base-type=uint8, compu {phys=raw}, range phys 0..255
          signal StatusCSRangingFBD_VL_IV01: start 80, 8 bit, little-endian, data-type-policy=OVERRIDE, base-type=uint8, compu {phys=raw}, range phys 0..255
          signal StatusCSRangingFBD_VL_IV02: start 88, 8 bit, little-endian, data-type-policy=OVERRIDE, base-type=uint8, compu {phys=raw}, range phys 0..255
          signal StatusCSRangingFBD_VL_IV03: start 96, 8 bit, little-endian, data-type-policy=OVERRIDE, base-type=uint8, compu {phys=raw}, range phys 0..255
          signal StatusCSRangingFBD_VL_Sign00: start 104, 8 bit, little-endian, data-type-policy=OVERRIDE, base-type=uint8, compu {phys=raw}, range phys 0..255
          signal StatusCSRangingFBD_VL_Sign01: start 112, 8 bit, little-endian, data-type-policy=OVERRIDE, base-type=uint8, compu {phys=raw}, range phys 0..255
          signal StatusCSRangingFBD_VL_Sign02: start 120, 8 bit, little-endian, data-type-policy=OVERRIDE, base-type=uint8, compu {phys=raw}, range phys 0..255
          signal StatusCSRangingFBD_VL_Sign03: start 128, 8 bit, little-endian, data-type-policy=OVERRIDE, base-type=uint8, compu {phys=raw}, range phys 0..255
          signal StatusCSRangingFBD_VL_Sign04: start 136, 8 bit, little-endian, data-type-policy=OVERRIDE, base-type=uint8, compu {phys=raw}, range phys 0..255
          signal StatusCSRangingFBD_VL_Sign05: start 144, 8 bit, little-endian, data-type-policy=OVERRIDE, base-type=uint8, compu {phys=raw}, range phys 0..255
          signal StatusCSRangingFBD_VL_Sign06: start 152, 8 bit, little-endian, data-type-policy=OVERRIDE, base-type=uint8, compu {phys=raw}, range phys 0..255
          signal StatusCSRangingFBD_VL_Sign07: start 160, 8 bit, little-endian, data-type-policy=OVERRIDE, base-type=uint8, compu {phys=raw}, range phys 0..255
          signal StatusCSRangingFBD_VL_Status1: start 168, 8 bit, little-endian, data-type-policy=OVERRIDE, base-type=uint8, compu {phys=raw}, range phys 0..252
          signal StatusCSRangingFBD_VL_Status2: start 176, 8 bit, little-endian, data-type-policy=OVERRIDE, base-type=uint8, compu {phys=raw}, range phys 0..252
          signal StatusCSRangingFBD_VL_NADM: start 184, 8 bit, little-endian, data-type-policy=OVERRIDE, compu {phys=raw}
      frame StatusCSRangingFBD_VM: id 0xBE, frame-length=24, can-addressing-mode=STANDARD, can-frame-rx-behavior=CAN-FD, can-frame-tx-behavior=CAN-FD
        pdu StatusCSRangingFBD_VM: length=24, unused-bit-pattern=0
          signal StatusCSRangingFBD_VM_SessionID: start 0, 8 bit, little-endian, data-type-policy=OVERRIDE, base-type=uint8, compu {phys=raw}, range phys 0..252
          signal StatusCSRangingFBD_VM_IRKListIndex: start 8, 8 bit, little-endian, data-type-policy=OVERRIDE, base-type=uint8, compu {phys=raw}, range phys 0..252
          signal StatusCSRangingFBD_VM_Distance: start 16, 16 bit, little-endian, data-type-policy=OVERRIDE, base-type=uint16, compu {phys=raw; unit cm}, range phys 0..65532
          signal StatusCSRangingFBD_VM_ProcedureCount: start 32, 16 bit, little-endian, data-type-policy=OVERRIDE, base-type=uint16, compu {phys=raw}, range phys 0..65532
          signal StatusCSRangingFBD_VM_Quality: start 48, 8 bit, little-endian, data-type-policy=OVERRIDE, base-type=uint8, compu {phys=raw}, range phys 0..252
          signal StatusCSRangingFBD_VM_RoundTripTime: start 56, 16 bit, little-endian, data-type-policy=OVERRIDE, base-type=uint16, compu {phys=raw; unit cm}, range phys 0..65532
          signal StatusCSRangingFBD_VM_IV00: start 72, 8 bit, little-endian, data-type-policy=OVERRIDE, base-type=uint8, compu {phys=raw}, range phys 0..255
          signal StatusCSRangingFBD_VM_IV01: start 80, 8 bit, little-endian, data-type-policy=OVERRIDE, base-type=uint8, compu {phys=raw}, range phys 0..255
          signal StatusCSRangingFBD_VM_IV02: start 88, 8 bit, little-endian, data-type-policy=OVERRIDE, base-type=uint8, compu {phys=raw}, range phys 0..255
          signal StatusCSRangingFBD_VM_IV03: start 96, 8 bit, little-endian, data-type-policy=OVERRIDE, base-type=uint8, compu {phys=raw}, range phys 0..255
          signal StatusCSRangingFBD_VM_Sign00: start 104, 8 bit, little-endian, data-type-policy=OVERRIDE, base-type=uint8, compu {phys=raw}, range phys 0..255
          signal StatusCSRangingFBD_VM_Sign01: start 112, 8 bit, little-endian, data-type-policy=OVERRIDE, base-type=uint8, compu {phys=raw}, range phys 0..255
          signal StatusCSRangingFBD_VM_Sign02: start 120, 8 bit, little-endian, data-type-policy=OVERRIDE, base-type=uint8, compu {phys=raw}, range phys 0..255
          signal StatusCSRangingFBD_VM_Sign03: start 128, 8 bit, little-endian, data-type-policy=OVERRIDE, base-type=uint8, compu {phys=raw}, range phys 0..255
          signal StatusCSRangingFBD_VM_Sign04: start 136, 8 bit, little-endian, data-type-policy=OVERRIDE, base-type=uint8, compu {phys=raw}, range phys 0..255
          signal StatusCSRangingFBD_VM_Sign05: start 144, 8 bit, little-endian, data-type-policy=OVERRIDE, base-type=uint8, compu {phys=raw}, range phys 0..255
          signal StatusCSRangingFBD_VM_Sign06: start 152, 8 bit, little-endian, data-type-policy=OVERRIDE, base-type=uint8, compu {phys=raw}, range phys 0..255
          signal StatusCSRangingFBD_VM_Sign07: start 160, 8 bit, little-endian, data-type-policy=OVERRIDE, base-type=uint8, compu {phys=raw}, range phys 0..255
          signal StatusCSRangingFBD_VM_Status1: start 168, 8 bit, little-endian, data-type-policy=OVERRIDE, base-type=uint8, compu {phys=raw}, range phys 0..252
          signal StatusCSRangingFBD_VM_Status2: start 176, 8 bit, little-endian, data-type-policy=OVERRIDE, base-type=uint8, compu {phys=raw}, range phys 0..252
          signal StatusCSRangingFBD_VM_NADM: start 184, 8 bit, little-endian, data-type-policy=OVERRIDE, compu {phys=raw}
      frame StatusCSRangingFBD_VR: id 0xC3, frame-length=24, can-addressing-mode=STANDARD, can-frame-rx-behavior=CAN-FD, can-frame-tx-behavior=CAN-FD
        pdu StatusCSRangingFBD_VR: length=24, unused-bit-pattern=0
          signal StatusCSRangingFBD_VR_SessionID: start 0, 8 bit, little-endian, data-type-policy=OVERRIDE, base-type=uint8, compu {phys=raw}, range phys 0..252
          signal StatusCSRangingFBD_VR_IRKListIndex: start 8, 8 bit, little-endian, data-type-policy=OVERRIDE, base-type=uint8, compu {phys=raw}, range phys 0..252
          signal StatusCSRangingFBD_VR_Distance: start 16, 16 bit, little-endian, data-type-policy=OVERRIDE, base-type=uint16, compu {phys=raw; unit cm}, range phys 0..65532
          signal StatusCSRangingFBD_VR_ProcedureCount: start 32, 16 bit, little-endian, data-type-policy=OVERRIDE, base-type=uint16, compu {phys=raw}, range phys 0..65532
          signal StatusCSRangingFBD_VR_Quality: start 48, 8 bit, little-endian, data-type-policy=OVERRIDE, base-type=uint8, compu {phys=raw}, range phys 0..252
          signal StatusCSRangingFBD_VR_RoundTripTime: start 56, 16 bit, little-endian, data-type-policy=OVERRIDE, base-type=uint16, compu {phys=raw; unit cm}, range phys 0..65532
          signal StatusCSRangingFBD_VR_IV00: start 72, 8 bit, little-endian, data-type-policy=OVERRIDE, base-type=uint8, compu {phys=raw}, range phys 0..255
          signal StatusCSRangingFBD_VR_IV01: start 80, 8 bit, little-endian, data-type-policy=OVERRIDE, base-type=uint8, compu {phys=raw}, range phys 0..255
          signal StatusCSRangingFBD_VR_IV02: start 88, 8 bit, little-endian, data-type-policy=OVERRIDE, base-type=uint8, compu {phys=raw}, range phys 0..255
          signal StatusCSRangingFBD_VR_IV03: start 96, 8 bit, little-endian, data-type-policy=OVERRIDE, base-type=uint8, compu {phys=raw}, range phys 0..255
          signal StatusCSRangingFBD_VR_Sign00: start 104, 8 bit, little-endian, data-type-policy=OVERRIDE, base-type=uint8, compu {phys=raw}, range phys 0..255
          signal StatusCSRangingFBD_VR_Sign01: start 112, 8 bit, little-endian, data-type-policy=OVERRIDE, base-type=uint8, compu {phys=raw}, range phys 0..255
          signal StatusCSRangingFBD_VR_Sign02: start 120, 8 bit, little-endian, data-type-policy=OVERRIDE, base-type=uint8, compu {phys=raw}, range phys 0..255
          signal StatusCSRangingFBD_VR_Sign03: start 128, 8 bit, little-endian, data-type-policy=OVERRIDE, base-type=uint8, compu {phys=raw}, range phys 0..255
          signal StatusCSRangingFBD_VR_Sign04: start 136, 8 bit, little-endian, data-type-policy=OVERRIDE, base-type=uint8, compu {phys=raw}, range phys 0..255
          signal StatusCSRangingFBD_VR_Sign05: start 144, 8 bit, little-endian, data-type-policy=OVERRIDE, base-type=uint8, compu {phys=raw}, range phys 0..255
          signal StatusCSRangingFBD_VR_Sign06: start 152, 8 bit, little-endian, data-type-policy=OVERRIDE, base-type=uint8, compu {phys=raw}, range phys 0..255
          signal StatusCSRangingFBD_VR_Sign07: start 160, 8 bit, little-endian, data-type-policy=OVERRIDE, base-type=uint8, compu {phys=raw}, range phys 0..255
          signal StatusCSRangingFBD_VR_Status1: start 168, 8 bit, little-endian, data-type-policy=OVERRIDE, base-type=uint8, compu {phys=raw}, range phys 0..252
          signal StatusCSRangingFBD_VR_Status2: start 176, 8 bit, little-endian, data-type-policy=OVERRIDE, base-type=uint8, compu {phys=raw}, range phys 0..252
          signal StatusCSRangingFBD_VR_NADM: start 184, 8 bit, little-endian, data-type-policy=OVERRIDE, compu {phys=raw}
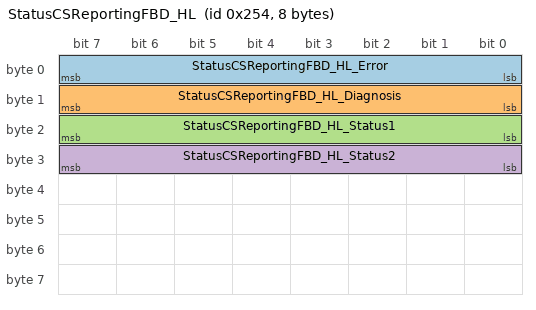
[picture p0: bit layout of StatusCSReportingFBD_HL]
      frame StatusCSReportingFBD_HL: id 0x254, frame-length=8, can-addressing-mode=STANDARD, can-frame-rx-behavior=CAN-20, can-frame-tx-behavior=CAN-20
        pdu StatusCSReportingFBD_HL: length=8, unused-bit-pattern=0
          signal StatusCSReportingFBD_HL_Error: start 0, 8 bit, little-endian, data-type-policy=OVERRIDE, compu {phys=raw}
          signal StatusCSReportingFBD_HL_Diagnosis: start 8, 8 bit, little-endian, data-type-policy=OVERRIDE, base-type=uint8, compu {phys=raw}, range phys 0..252
          signal StatusCSReportingFBD_HL_Status1: start 16, 8 bit, little-endian, data-type-policy=OVERRIDE, base-type=uint8, compu {phys=raw}, range phys 0..252
          signal StatusCSReportingFBD_HL_Status2: start 24, 8 bit, little-endian, data-type-policy=OVERRIDE, base-type=uint8, compu {phys=raw}, range phys 0..252
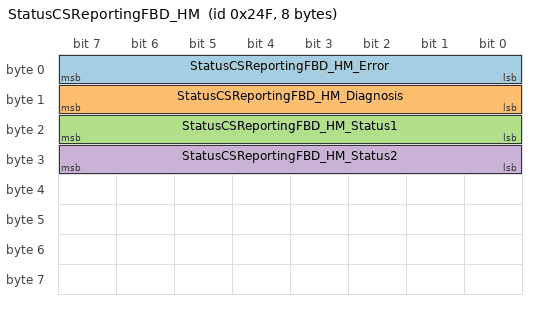
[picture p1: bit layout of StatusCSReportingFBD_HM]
      frame StatusCSReportingFBD_HM: id 0x24F, frame-length=8, can-addressing-mode=STANDARD, can-frame-rx-behavior=CAN-20, can-frame-tx-behavior=CAN-20
        pdu StatusCSReportingFBD_HM: length=8, unused-bit-pattern=0
          signal StatusCSReportingFBD_HM_Error: start 0, 8 bit, little-endian, data-type-policy=OVERRIDE, compu {phys=raw}
          signal StatusCSReportingFBD_HM_Diagnosis: start 8, 8 bit, little-endian, data-type-policy=OVERRIDE, base-type=uint8, compu {phys=raw}, range phys 0..252
          signal StatusCSReportingFBD_HM_Status1: start 16, 8 bit, little-endian, data-type-policy=OVERRIDE, base-type=uint8, compu {phys=raw}, range phys 0..252
          signal StatusCSReportingFBD_HM_Status2: start 24, 8 bit, little-endian, data-type-policy=OVERRIDE, base-type=uint8, compu {phys=raw}, range phys 0..252
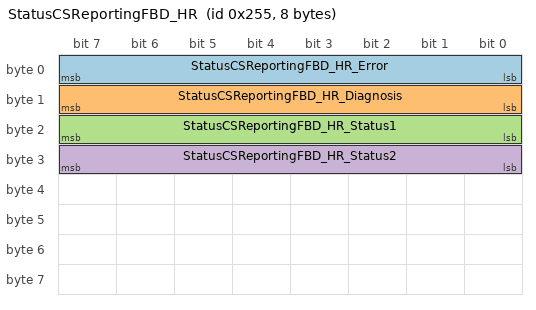
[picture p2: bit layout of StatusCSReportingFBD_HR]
      frame StatusCSReportingFBD_HR: id 0x255, frame-length=8, can-addressing-mode=STANDARD, can-frame-rx-behavior=CAN-20, can-frame-tx-behavior=CAN-20
        pdu StatusCSReportingFBD_HR: length=8, unused-bit-pattern=0
          signal StatusCSReportingFBD_HR_Error: start 0, 8 bit, little-endian, data-type-policy=OVERRIDE, compu {phys=raw}
          signal StatusCSReportingFBD_HR_Diagnosis: start 8, 8 bit, little-endian, data-type-policy=OVERRIDE, base-type=uint8, compu {phys=raw}, range phys 0..252
          signal StatusCSReportingFBD_HR_Status1: start 16, 8 bit, little-endian, data-type-policy=OVERRIDE, base-type=uint8, compu {phys=raw}, range phys 0..252
          signal StatusCSReportingFBD_HR_Status2: start 24, 8 bit, little-endian, data-type-policy=OVERRIDE, base-type=uint8, compu {phys=raw}, range phys 0..252
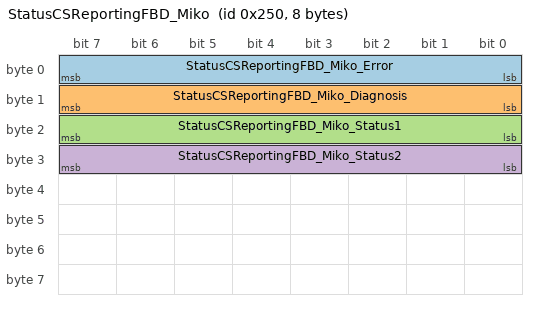
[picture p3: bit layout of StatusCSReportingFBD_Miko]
      frame StatusCSReportingFBD_Miko: id 0x250, frame-length=8, can-addressing-mode=STANDARD, can-frame-rx-behavior=CAN-20, can-frame-tx-behavior=CAN-20
        pdu StatusCSReportingFBD_Miko: length=8, unused-bit-pattern=0
          signal StatusCSReportingFBD_Miko_Error: start 0, 8 bit, little-endian, data-type-policy=OVERRIDE, compu {phys=raw}
          signal StatusCSReportingFBD_Miko_Diagnosis: start 8, 8 bit, little-endian, data-type-policy=OVERRIDE, base-type=uint8, compu {phys=raw}, range phys 0..252
          signal StatusCSReportingFBD_Miko_Status1: start 16, 8 bit, little-endian, data-type-policy=OVERRIDE, base-type=uint8, compu {phys=raw}, range phys 0..252
          signal StatusCSReportingFBD_Miko_Status2: start 24, 8 bit, little-endian, data-type-policy=OVERRIDE, base-type=uint8, compu {phys=raw}, range phys 0..252
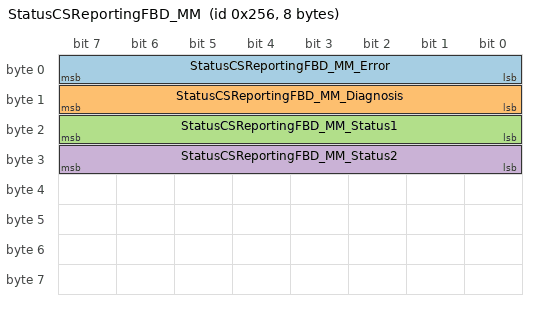
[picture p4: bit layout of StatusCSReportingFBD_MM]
      frame StatusCSReportingFBD_MM: id 0x256, frame-length=8, can-addressing-mode=STANDARD, can-frame-rx-behavior=CAN-20, can-frame-tx-behavior=CAN-20
        pdu StatusCSReportingFBD_MM: length=8, unused-bit-pattern=0
          signal StatusCSReportingFBD_MM_Error: start 0, 8 bit, little-endian, data-type-policy=OVERRIDE, compu {phys=raw}
          signal StatusCSReportingFBD_MM_Diagnosis: start 8, 8 bit, little-endian, data-type-policy=OVERRIDE, base-type=uint8, compu {phys=raw}, range phys 0..252
          signal StatusCSReportingFBD_MM_Status1: start 16, 8 bit, little-endian, data-type-policy=OVERRIDE, base-type=uint8, compu {phys=raw}, range phys 0..252
          signal StatusCSReportingFBD_MM_Status2: start 24, 8 bit, little-endian, data-type-policy=OVERRIDE, base-type=uint8, compu {phys=raw}, range phys 0..252
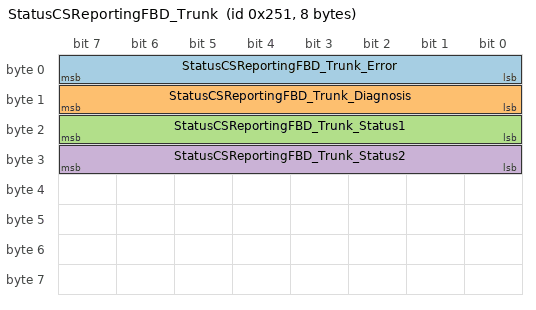
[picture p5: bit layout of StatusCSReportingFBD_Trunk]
      frame StatusCSReportingFBD_Trunk: id 0x251, frame-length=8, can-addressing-mode=STANDARD, can-frame-rx-behavior=CAN-20, can-frame-tx-behavior=CAN-20
        pdu StatusCSReportingFBD_Trunk: length=8, unused-bit-pattern=0
          signal StatusCSReportingFBD_Trunk_Error: start 0, 8 bit, little-endian, data-type-policy=OVERRIDE, compu {phys=raw}
          signal StatusCSReportingFBD_Trunk_Diagnosis: start 8, 8 bit, little-endian, data-type-policy=OVERRIDE, base-type=uint8, compu {phys=raw}, range phys 0..252
          signal StatusCSReportingFBD_Trunk_Status1: start 16, 8 bit, little-endian, data-type-policy=OVERRIDE, base-type=uint8, compu {phys=raw}, range phys 0..252
          signal StatusCSReportingFBD_Trunk_Status2: start 24, 8 bit, little-endian, data-type-policy=OVERRIDE, base-type=uint8, compu {phys=raw}, range phys 0..252
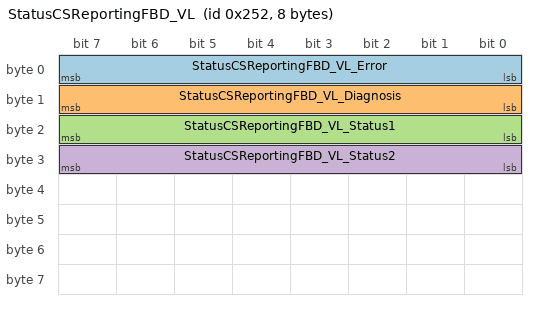
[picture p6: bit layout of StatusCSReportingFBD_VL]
      frame StatusCSReportingFBD_VL: id 0x252, frame-length=8, can-addressing-mode=STANDARD, can-frame-rx-behavior=CAN-20, can-frame-tx-behavior=CAN-20
        pdu StatusCSReportingFBD_VL: length=8, unused-bit-pattern=0
          signal StatusCSReportingFBD_VL_Error: start 0, 8 bit, little-endian, data-type-policy=OVERRIDE, compu {phys=raw}
          signal StatusCSReportingFBD_VL_Diagnosis: start 8, 8 bit, little-endian, data-type-policy=OVERRIDE, base-type=uint8, compu {phys=raw}, range phys 0..252
          signal StatusCSReportingFBD_VL_Status1: start 16, 8 bit, little-endian, data-type-policy=OVERRIDE, base-type=uint8, compu {phys=raw}, range phys 0..252
          signal StatusCSReportingFBD_VL_Status2: start 24, 8 bit, little-endian, data-type-policy=OVERRIDE, base-type=uint8, compu {phys=raw}, range phys 0..252
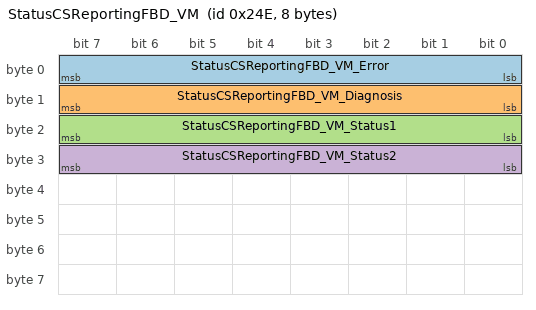
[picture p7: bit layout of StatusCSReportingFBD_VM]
      frame StatusCSReportingFBD_VM: id 0x24E, frame-length=8, can-addressing-mode=STANDARD, can-frame-rx-behavior=CAN-20, can-frame-tx-behavior=CAN-20
        pdu StatusCSReportingFBD_VM: length=8, unused-bit-pattern=0
          signal StatusCSReportingFBD_VM_Error: start 0, 8 bit, little-endian, data-type-policy=OVERRIDE, compu {phys=raw}
          signal StatusCSReportingFBD_VM_Diagnosis: start 8, 8 bit, little-endian, data-type-policy=OVERRIDE, base-type=uint8, compu {phys=raw}, range phys 0..252
          signal StatusCSReportingFBD_VM_Status1: start 16, 8 bit, little-endian, data-type-policy=OVERRIDE, base-type=uint8, compu {phys=raw}, range phys 0..252
          signal StatusCSReportingFBD_VM_Status2: start 24, 8 bit, little-endian, data-type-policy=OVERRIDE, base-type=uint8, compu {phys=raw}, range phys 0..252
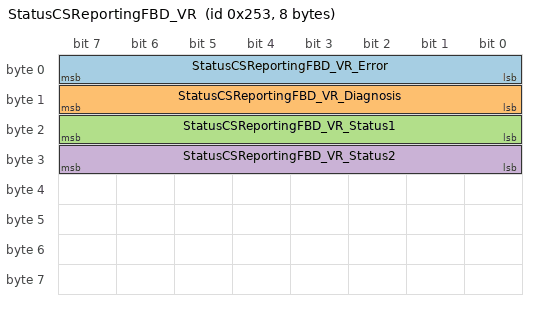
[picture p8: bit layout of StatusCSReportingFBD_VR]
      frame StatusCSReportingFBD_VR: id 0x253, frame-length=8, can-addressing-mode=STANDARD, can-frame-rx-behavior=CAN-20, can-frame-tx-behavior=CAN-20
        pdu StatusCSReportingFBD_VR: length=8, unused-bit-pattern=0
          signal StatusCSReportingFBD_VR_Error: start 0, 8 bit, little-endian, data-type-policy=OVERRIDE, compu {phys=raw}
          signal StatusCSReportingFBD_VR_Diagnosis: start 8, 8 bit, little-endian, data-type-policy=OVERRIDE, base-type=uint8, compu {phys=raw}, range phys 0..252
          signal StatusCSReportingFBD_VR_Status1: start 16, 8 bit, little-endian, data-type-policy=OVERRIDE, base-type=uint8, compu {phys=raw}, range phys 0..252
          signal StatusCSReportingFBD_VR_Status2: start 24, 8 bit, little-endian, data-type-policy=OVERRIDE, base-type=uint8, compu {phys=raw}, range phys 0..252
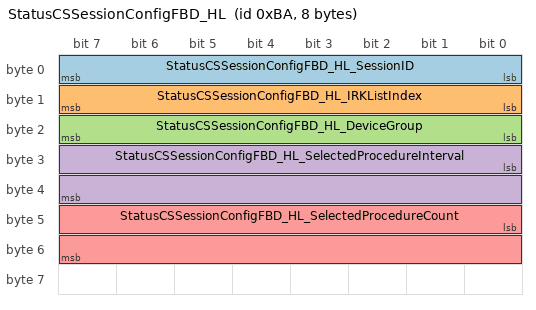
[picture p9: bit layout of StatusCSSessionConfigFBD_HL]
      frame StatusCSSessionConfigFBD_HL: id 0xBA, frame-length=8, can-addressing-mode=STANDARD, can-frame-rx-behavior=CAN-20, can-frame-tx-behavior=CAN-20
        pdu StatusCSSessionConfigFBD_HL: length=8, unused-bit-pattern=0
          signal StatusCSSessionConfigFBD_HL_SessionID: start 0, 8 bit, little-endian, data-type-policy=OVERRIDE, base-type=uint8, compu {phys=raw}, range phys 0..252
          signal StatusCSSessionConfigFBD_HL_IRKListIndex: start 8, 8 bit, little-endian, data-type-policy=OVERRIDE, base-type=uint8, compu {phys=raw}, range phys 0..252
          signal StatusCSSessionConfigFBD_HL_DeviceGroup: start 16, 8 bit, little-endian, data-type-policy=OVERRIDE, base-type=uint8, compu {phys=raw}, range phys 0..252
          signal StatusCSSessionConfigFBD_HL_SelectedProcedureInterval: start 24, 16 bit, little-endian, data-type-policy=OVERRIDE, base-type=uint16, compu {phys=raw*0.625; unit ms}, range phys 0..40900
          signal StatusCSSessionConfigFBD_HL_SelectedProcedureCount: start 40, 16 bit, little-endian, data-type-policy=OVERRIDE, base-type=uint16, compu {phys=raw}, range phys 0..65532
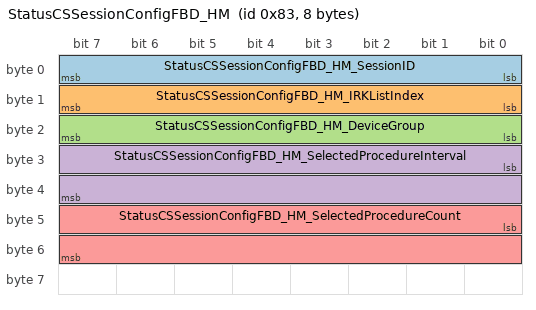
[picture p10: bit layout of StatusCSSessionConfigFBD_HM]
      frame StatusCSSessionConfigFBD_HM: id 0x83, frame-length=8, can-addressing-mode=STANDARD, can-frame-rx-behavior=CAN-20, can-frame-tx-behavior=CAN-20
        pdu StatusCSSessionConfigFBD_HM: length=8, unused-bit-pattern=0
          signal StatusCSSessionConfigFBD_HM_SessionID: start 0, 8 bit, little-endian, data-type-policy=OVERRIDE, base-type=uint8, compu {phys=raw}, range phys 0..252
          signal StatusCSSessionConfigFBD_HM_IRKListIndex: start 8, 8 bit, little-endian, data-type-policy=OVERRIDE, base-type=uint8, compu {phys=raw}, range phys 0..252
          signal StatusCSSessionConfigFBD_HM_DeviceGroup: start 16, 8 bit, little-endian, data-type-policy=OVERRIDE, base-type=uint8, compu {phys=raw}, range phys 0..252
          signal StatusCSSessionConfigFBD_HM_SelectedProcedureInterval: start 24, 16 bit, little-endian, data-type-policy=OVERRIDE, base-type=uint16, compu {phys=raw*0.625; unit ms}, range phys 0..40900
          signal StatusCSSessionConfigFBD_HM_SelectedProcedureCount: start 40, 16 bit, little-endian, data-type-policy=OVERRIDE, base-type=uint16, compu {phys=raw}, range phys 0..65532
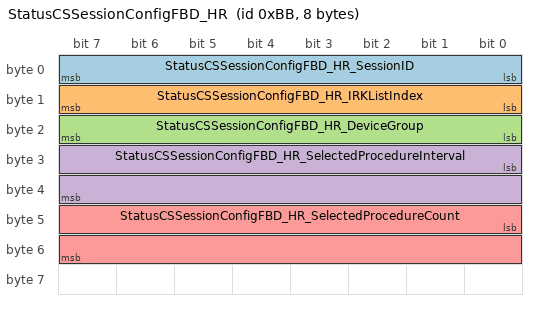
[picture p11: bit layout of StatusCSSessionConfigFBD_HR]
      frame StatusCSSessionConfigFBD_HR: id 0xBB, frame-length=8, can-addressing-mode=STANDARD, can-frame-rx-behavior=CAN-20, can-frame-tx-behavior=CAN-20
        pdu StatusCSSessionConfigFBD_HR: length=8, unused-bit-pattern=0
          signal StatusCSSessionConfigFBD_HR_SessionID: start 0, 8 bit, little-endian, data-type-policy=OVERRIDE, base-type=uint8, compu {phys=raw}, range phys 0..252
          signal StatusCSSessionConfigFBD_HR_IRKListIndex: start 8, 8 bit, little-endian, data-type-policy=OVERRIDE, base-type=uint8, compu {phys=raw}, range phys 0..252
          signal StatusCSSessionConfigFBD_HR_DeviceGroup: start 16, 8 bit, little-endian, data-type-policy=OVERRIDE, base-type=uint8, compu {phys=raw}, range phys 0..252
          signal StatusCSSessionConfigFBD_HR_SelectedProcedureInterval: start 24, 16 bit, little-endian, data-type-policy=OVERRIDE, base-type=uint16, compu {phys=raw*0.625; unit ms}, range phys 0..40900
          signal StatusCSSessionConfigFBD_HR_SelectedProcedureCount: start 40, 16 bit, little-endian, data-type-policy=OVERRIDE, base-type=uint16, compu {phys=raw}, range phys 0..65532
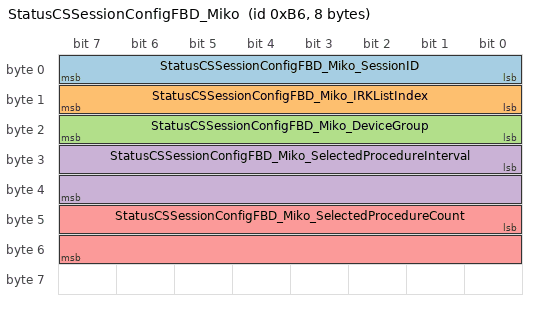
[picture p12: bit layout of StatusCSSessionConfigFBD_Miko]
      frame StatusCSSessionConfigFBD_Miko: id 0xB6, frame-length=8, can-addressing-mode=STANDARD, can-frame-rx-behavior=CAN-20, can-frame-tx-behavior=CAN-20
        pdu StatusCSSessionConfigFBD_Miko: length=8, unused-bit-pattern=0
          signal StatusCSSessionConfigFBD_Miko_SessionID: start 0, 8 bit, little-endian, data-type-policy=OVERRIDE, base-type=uint8, compu {phys=raw}, range phys 0..252
          signal StatusCSSessionConfigFBD_Miko_IRKListIndex: start 8, 8 bit, little-endian, data-type-policy=OVERRIDE, base-type=uint8, compu {phys=raw}, range phys 0..252
          signal StatusCSSessionConfigFBD_Miko_DeviceGroup: start 16, 8 bit, little-endian, data-type-policy=OVERRIDE, base-type=uint8, compu {phys=raw}, range phys 0..252
          signal StatusCSSessionConfigFBD_Miko_SelectedProcedureInterval: start 24, 16 bit, little-endian, data-type-policy=OVERRIDE, base-type=uint16, compu {phys=raw*0.625; unit ms}, range phys 0..40900
          signal StatusCSSessionConfigFBD_Miko_SelectedProcedureCount: start 40, 16 bit, little-endian, data-type-policy=OVERRIDE, base-type=uint16, compu {phys=raw}, range phys 0..65532
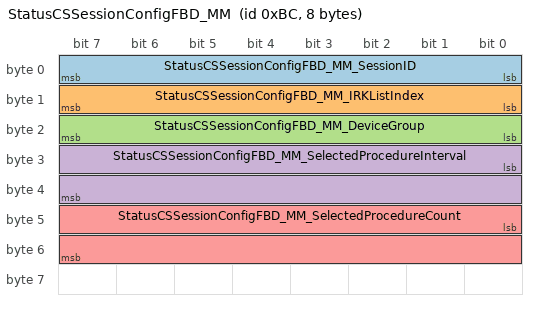
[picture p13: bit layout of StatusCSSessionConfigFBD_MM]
      frame StatusCSSessionConfigFBD_MM: id 0xBC, frame-length=8, can-addressing-mode=STANDARD, can-frame-rx-behavior=CAN-20, can-frame-tx-behavior=CAN-20
        pdu StatusCSSessionConfigFBD_MM: length=8, unused-bit-pattern=0
          signal StatusCSSessionConfigFBD_MM_SessionID: start 0, 8 bit, little-endian, data-type-policy=OVERRIDE, base-type=uint8, compu {phys=raw}, range phys 0..252
          signal StatusCSSessionConfigFBD_MM_IRKListIndex: start 8, 8 bit, little-endian, data-type-policy=OVERRIDE, base-type=uint8, compu {phys=raw}, range phys 0..252
          signal StatusCSSessionConfigFBD_MM_DeviceGroup: start 16, 8 bit, little-endian, data-type-policy=OVERRIDE, base-type=uint8, compu {phys=raw}, range phys 0..252
          signal StatusCSSessionConfigFBD_MM_SelectedProcedureInterval: start 24, 16 bit, little-endian, data-type-policy=OVERRIDE, base-type=uint16, compu {phys=raw*0.625; unit ms}, range phys 0..40900
          signal StatusCSSessionConfigFBD_MM_SelectedProcedureCount: start 40, 16 bit, little-endian, data-type-policy=OVERRIDE, base-type=uint16, compu {phys=raw}, range phys 0..65532
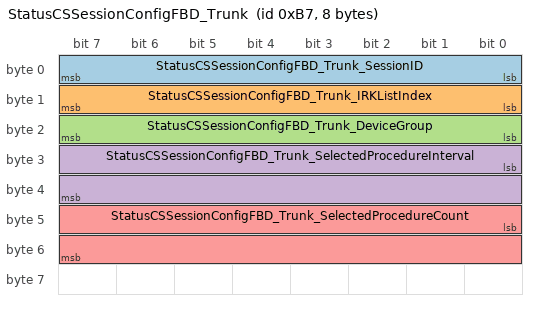
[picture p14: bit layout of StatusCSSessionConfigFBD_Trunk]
      frame StatusCSSessionConfigFBD_Trunk: id 0xB7, frame-length=8, can-addressing-mode=STANDARD, can-frame-rx-behavior=CAN-20, can-frame-tx-behavior=CAN-20
        pdu StatusCSSessionConfigFBD_Trunk: length=8, unused-bit-pattern=0
          signal StatusCSSessionConfigFBD_Trunk_SessionID: start 0, 8 bit, little-endian, data-type-policy=OVERRIDE, base-type=uint8, compu {phys=raw}, range phys 0..252
          signal StatusCSSessionConfigFBD_Trunk_IRKListIndex: start 8, 8 bit, little-endian, data-type-policy=OVERRIDE, base-type=uint8, compu {phys=raw}, range phys 0..252
          signal StatusCSSessionConfigFBD_Trunk_DeviceGroup: start 16, 8 bit, little-endian, data-type-policy=OVERRIDE, base-type=uint8, compu {phys=raw}, range phys 0..252
          signal StatusCSSessionConfigFBD_Trunk_SelectedProcedureInterval: start 24, 16 bit, little-endian, data-type-policy=OVERRIDE, base-type=uint16, compu {phys=raw*0.625; unit ms}, range phys 0..40900
          signal StatusCSSessionConfigFBD_Trunk_SelectedProcedureCount: start 40, 16 bit, little-endian, data-type-policy=OVERRIDE, base-type=uint16, compu {phys=raw}, range phys 0..65532
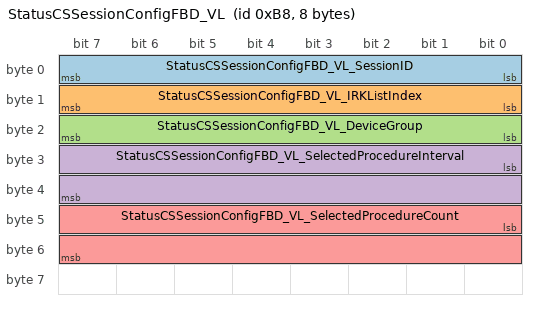
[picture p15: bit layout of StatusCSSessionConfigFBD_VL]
      frame StatusCSSessionConfigFBD_VL: id 0xB8, frame-length=8, can-addressing-mode=STANDARD, can-frame-rx-behavior=CAN-20, can-frame-tx-behavior=CAN-20
        pdu StatusCSSessionConfigFBD_VL: length=8, unused-bit-pattern=0
          signal StatusCSSessionConfigFBD_VL_SessionID: start 0, 8 bit, little-endian, data-type-policy=OVERRIDE, base-type=uint8, compu {phys=raw}, range phys 0..252
          signal StatusCSSessionConfigFBD_VL_IRKListIndex: start 8, 8 bit, little-endian, data-type-policy=OVERRIDE, base-type=uint8, compu {phys=raw}, range phys 0..252
          signal StatusCSSessionConfigFBD_VL_DeviceGroup: start 16, 8 bit, little-endian, data-type-policy=OVERRIDE, base-type=uint8, compu {phys=raw}, range phys 0..252
          signal StatusCSSessionConfigFBD_VL_SelectedProcedureInterval: start 24, 16 bit, little-endian, data-type-policy=OVERRIDE, base-type=uint16, compu {phys=raw*0.625; unit ms}, range phys 0..40900
          signal StatusCSSessionConfigFBD_VL_SelectedProcedureCount: start 40, 16 bit, little-endian, data-type-policy=OVERRIDE, base-type=uint16, compu {phys=raw}, range phys 0..65532
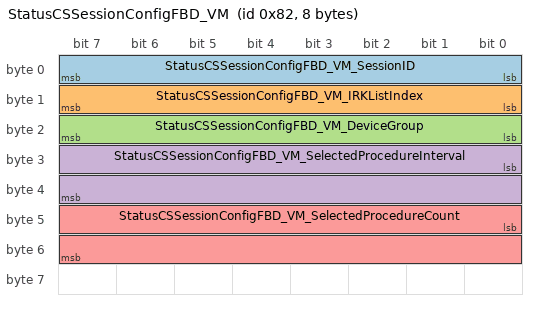
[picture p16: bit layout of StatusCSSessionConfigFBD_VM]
      frame StatusCSSessionConfigFBD_VM: id 0x82, frame-length=8, can-addressing-mode=STANDARD, can-frame-rx-behavior=CAN-20, can-frame-tx-behavior=CAN-20
        pdu StatusCSSessionConfigFBD_VM: length=8, unused-bit-pattern=0
          signal StatusCSSessionConfigFBD_VM_SessionID: start 0, 8 bit, little-endian, data-type-policy=OVERRIDE, base-type=uint8, compu {phys=raw}, range phys 0..252
          signal StatusCSSessionConfigFBD_VM_IRKListIndex: start 8, 8 bit, little-endian, data-type-policy=OVERRIDE, base-type=uint8, compu {phys=raw}, range phys 0..252
          signal StatusCSSessionConfigFBD_VM_DeviceGroup: start 16, 8 bit, little-endian, data-type-policy=OVERRIDE, base-type=uint8, compu {phys=raw}, range phys 0..252
          signal StatusCSSessionConfigFBD_VM_SelectedProcedureInterval: start 24, 16 bit, little-endian, data-type-policy=OVERRIDE, base-type=uint16, compu {phys=raw*0.625; unit ms}, range phys 0..40900
          signal StatusCSSessionConfigFBD_VM_SelectedProcedureCount: start 40, 16 bit, little-endian, data-type-policy=OVERRIDE, base-type=uint16, compu {phys=raw}, range phys 0..65532
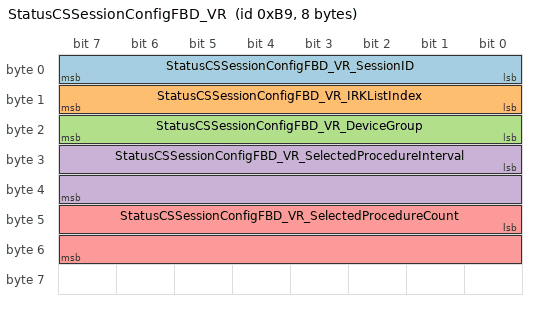
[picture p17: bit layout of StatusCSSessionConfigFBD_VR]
      frame StatusCSSessionConfigFBD_VR: id 0xB9, frame-length=8, can-addressing-mode=STANDARD, can-frame-rx-behavior=CAN-20, can-frame-tx-behavior=CAN-20
        pdu StatusCSSessionConfigFBD_VR: length=8, unused-bit-pattern=0
          signal StatusCSSessionConfigFBD_VR_SessionID: start 0, 8 bit, little-endian, data-type-policy=OVERRIDE, base-type=uint8, compu {phys=raw}, range phys 0..252
          signal StatusCSSessionConfigFBD_VR_IRKListIndex: start 8, 8 bit, little-endian, data-type-policy=OVERRIDE, base-type=uint8, compu {phys=raw}, range phys 0..252
          signal StatusCSSessionConfigFBD_VR_DeviceGroup: start 16, 8 bit, little-endian, data-type-policy=OVERRIDE, base-type=uint8, compu {phys=raw}, range phys 0..252
          signal StatusCSSessionConfigFBD_VR_SelectedProcedureInterval: start 24, 16 bit, little-endian, data-type-policy=OVERRIDE, base-type=uint16, compu {phys=raw*0.625; unit ms}, range phys 0..40900
          signal StatusCSSessionConfigFBD_VR_SelectedProcedureCount: start 40, 16 bit, little-endian, data-type-policy=OVERRIDE, base-type=uint16, compu {phys=raw}, range phys 0..65532
